VERSION ""

NS_ :

BS_:

BU_: FUSION ZONE_FR ZONE_DR D21_DKC ZONE_FR_24

BO_ 278 FD4_CE100_0: 32 FUSION
 SG_ CS_VCU1_CAN4 : 7|8@0+ (1,0) [0|255] ""  ZONE_FR,ZONE_DR
 SG_ RC_VCU1_CAN4 : 11|4@0+ (1,0) [0|14] ""  ZONE_FR,ZONE_DR
 SG_ Dr_SeatSta : 23|2@0+ (1,0) [0|2] ""  ZONE_FR,ZONE_DR,D21_DKC
 SG_ MSA_Crl_Sta : 21|3@0+ (1,0) [0|7] ""  ZONE_FR,ZONE_DR
 SG_ CC_Crl_Sta : 18|3@0+ (1,0) [0|7] ""  ZONE_FR,ZONE_DR
 SG_ ShiftGearPosn : 31|3@0+ (1,0) [0|7] ""  ZONE_FR,ZONE_DR,D21_DKC,ZONE_FR_24
 SG_ PwrSta : 28|3@0+ (1,0) [0|7] ""  ZONE_FR,ZONE_DR,D21_DKC,ZONE_FR_24
 SG_ ReBrakeLPReq : 25|1@0+ (1,0) [0|1] ""  ZONE_FR,ZONE_DR
 SG_ DKCTimeSN : 39|32@0+ (1,0) [0|4294967295] ""  ZONE_FR,ZONE_DR,D21_DKC
 SG_ TimeSNDKCFbk : 71|32@0+ (1,0) [0|4294967295] ""  ZONE_FR,ZONE_DR,D21_DKC
 SG_ EquivAccPedalSWSta : 103|1@0+ (1,0) [0|1] ""  ZONE_FR,ZONE_DR
 SG_ HornCtrl : 102|1@0+ (1,0) [0|1] ""  ZONE_FR,ZONE_DR
 SG_ BCM_DoorLock_Sta : 101|1@0+ (1,0) [0|1] ""  ZONE_FR,ZONE_DR,D21_DKC
 SG_ DimmerEN : 100|1@0+ (1,0) [0|1] ""  ZONE_FR,ZONE_DR
 SG_ RoomLampH : 99|1@0+ (1,0) [0|1] ""  ZONE_FR,ZONE_DR
 SG_ RoomLampL : 98|1@0+ (1,0) [0|1] ""  ZONE_FR,ZONE_DR
 SG_ TailgateRemote : 97|2@0+ (1,0) [0|3] ""  ZONE_FR,ZONE_DR
 SG_ Dimmer : 110|7@0+ (1,0) [0|100] "%"  ZONE_FR,ZONE_DR
 SG_ LockSetting : 118|1@0+ (1,0) [0|1] ""  ZONE_FR,ZONE_DR
 SG_ L_APM_WdwEnable : 117|1@0+ (1,0) [0|1] ""  ZONE_FR,ZONE_DR
 SG_ CrashDetd : 116|1@0+ (1,0) [0|1] ""  ZONE_FR,ZONE_DR
 SG_ AntiTheftSeatFold : 115|1@0+ (1,0) [0|1] ""  ZONE_FR,ZONE_DR
 SG_ AntitheftSta : 114|2@0+ (1,0) [0|3] ""  ZONE_FR,ZONE_DR,D21_DKC
 SG_ RTurnLP : 112|1@0+ (1,0) [0|1] ""  ZONE_FR,ZONE_DR,ZONE_FR_24
 SG_ LTurnLP : 127|1@0+ (1,0) [0|1] ""  ZONE_FR,ZONE_DR,ZONE_FR_24
 SG_ HazardSW : 126|1@0+ (1,0) [0|1] ""  ZONE_FR,ZONE_DR,ZONE_FR_24
 SG_ Rr_FogLamp : 125|1@0+ (1,0) [0|1] ""  ZONE_FR,ZONE_DR,ZONE_FR_24
 SG_ Fr_FogLamp : 124|1@0+ (1,0) [0|1] ""  ZONE_FR,ZONE_DR,ZONE_FR_24
 SG_ RBSD : 123|1@0+ (1,0) [0|1] ""  ZONE_FR,ZONE_DR,ZONE_FR_24
 SG_ LBSD : 122|1@0+ (1,0) [0|1] ""  ZONE_FR,ZONE_DR,ZONE_FR_24
 SG_ BrakeLamp : 121|1@0+ (1,0) [0|1] ""  ZONE_FR,ZONE_DR,ZONE_FR_24
 SG_ ReverseLamp : 120|1@0+ (1,0) [0|1] ""  ZONE_FR,ZONE_DR,ZONE_FR_24
 SG_ RDRL : 135|1@0+ (1,0) [0|1] ""  ZONE_FR,ZONE_DR,ZONE_FR_24
 SG_ LDRL : 134|1@0+ (1,0) [0|1] ""  ZONE_FR,ZONE_DR,ZONE_FR_24
 SG_ PosLamp : 133|1@0+ (1,0) [0|1] ""  ZONE_FR,ZONE_DR,ZONE_FR_24
 SG_ H_Beam : 132|1@0+ (1,0) [0|1] ""  ZONE_FR,ZONE_DR,ZONE_FR_24
 SG_ L_Beam : 131|1@0+ (1,0) [0|1] ""  ZONE_FR,ZONE_DR,ZONE_FR_24
 SG_ WasherCtrl : 130|2@0+ (1,0) [0|3] ""  ZONE_FR,ZONE_DR,ZONE_FR_24
 SG_ WiperFixMode : 128|1@0+ (1,0) [0|1] ""  ZONE_FR,ZONE_DR,ZONE_FR_24
 SG_ Rr_Wiper : 143|1@0+ (1,0) [0|1] ""  ZONE_FR,ZONE_DR
 SG_ Fr_Wiper_L : 142|1@0+ (1,0) [0|1] ""  ZONE_FR,ZONE_DR,ZONE_FR_24
 SG_ Fr_Wiper_H : 141|1@0+ (1,0) [0|1] ""  ZONE_FR,ZONE_DR,ZONE_FR_24
 SG_ MirrorCtrl : 140|2@0+ (1,0) [0|3] ""  ZONE_FR,ZONE_DR
 SG_ TailgateHDSW : 138|1@0+ (1,0) [0|1] ""  ZONE_FR,ZONE_DR,D21_DKC
 SG_ TrunkRel : 137|1@0+ (1,0) [0|1] ""  ZONE_FR,ZONE_DR
 SG_ Rr_Defog : 136|1@0+ (1,0) [0|1] ""  ZONE_FR,ZONE_DR
 SG_ Fr_ChargingDoorCtrl : 159|2@0+ (1,0) [0|3] ""  ZONE_FR,ZONE_DR
 SG_ HoodSW : 157|1@0+ (1,0) [0|1] ""  ZONE_FR,ZONE_DR,D21_DKC
 SG_ DoorLockIND : 156|1@0+ (1,0) [0|1] ""  ZONE_FR,ZONE_DR
 SG_ AllDoorSW : 155|1@0+ (1,0) [0|1] ""  ZONE_FR,ZONE_DR,D21_DKC
 SG_ RRDoorSW : 154|1@0+ (1,0) [0|1] ""  ZONE_FR,ZONE_DR,D21_DKC
 SG_ RLDoorSW : 153|1@0+ (1,0) [0|1] ""  ZONE_FR,ZONE_DR,D21_DKC
 SG_ PsDoorSW : 152|1@0+ (1,0) [0|1] ""  ZONE_FR,ZONE_DR,D21_DKC
 SG_ Rr_ChargingDoorCtrl : 167|2@0+ (1,0) [0|3] ""  ZONE_FR,ZONE_DR
 SG_ CTDCtrl : 165|2@0+ (1,0) [0|3] ""  ZONE_FR,ZONE_DR
 SG_ FD_TBOX_VehData_Sta : 163|4@0+ (1,0) [0|7] ""  ZONE_FR,ZONE_DR
 SG_ FD_TBOX_VehData_Err : 175|4@0+ (1,0) [0|7] ""  ZONE_FR,ZONE_DR
 SG_ FD_DKC_VehData_Sta : 171|4@0+ (1,0) [0|7] ""  ZONE_FR,ZONE_DR,D21_DKC
 SG_ FD_DKC_VehData_Err : 183|4@0+ (1,0) [0|7] ""  ZONE_FR,ZONE_DR,D21_DKC
 SG_ FD_TBOX_DTCData_Sta : 179|4@0+ (1,0) [0|7] ""  ZONE_FR,ZONE_DR
 SG_ FD_TBOX_DTCData_Err : 191|4@0+ (1,0) [0|7] ""  ZONE_FR,ZONE_DR
 SG_ LampPwr : 187|1@0+ (1,0) [0|1] ""  ZONE_FR,ZONE_DR
 SG_ DKCAuthSta : 185|2@0+ (1,0) [0|3] ""  ZONE_FR,ZONE_DR,D21_DKC
 SG_ MirrorDefog : 207|1@0+ (1,0) [0|1] ""  ZONE_FR,ZONE_DR
 SG_ DrDoorSW : 206|1@0+ (1,0) [0|1] ""  ZONE_FR,ZONE_DR,D21_DKC
 SG_ CTDLockSW : 215|1@0+ (1,0) [0|1] ""  ZONE_FR,ZONE_DR
 SG_ CTDUnlockSW : 214|1@0+ (1,0) [0|1] ""  ZONE_FR,ZONE_DR
 SG_ Tailgate_SW : 223|1@0+ (1,0) [0|1] ""  ZONE_FR,ZONE_DR,D21_DKC
 SG_ HWResetSta : 205|2@0+ (1,0) [0|3] ""  ZONE_FR,ZONE_DR
 SG_ CtrlFrBMSCCUCIR : 200|1@0+ (1,0) [0|1] ""  ZONE_FR
 SG_ CtrlFrEDUINVERTER : 201|1@0+ (1,0) [0|1] ""  ZONE_FR
 SG_ CtrlFrIRC1 : 202|1@0+ (1,0) [0|1] ""  ZONE_FR
 SG_ CtrlFrPwrStbA1P : 203|1@0+ (1,0) [0|1] ""  ZONE_FR
 SG_ CtrlDrPwrStbA2 : 222|1@0+ (1,0) [0|1] ""  ZONE_DR
 SG_ H_Beam_ADB : 24|1@0+ (1,0) [0|1] ""  ZONE_FR
 SG_ APS_Sta_System : 213|3@0+ (1,0) [0|7] ""  D21_DKC

BO_ 386 FD4_CE100_1: 64 FUSION
 SG_ CCU_HEATMaxLampSts : 23|1@0+ (1,0) [0|1] "" Vector__XXX
 SG_ CCU_ACLampSts : 22|1@0+ (1,0) [0|1] "" Vector__XXX
 SG_ CCU_Dispaly_Request : 21|1@0+ (1,0) [0|1] "" Vector__XXX
 SG_ CCU_EcoSts : 20|1@0+ (1,0) [0|1] "" Vector__XXX
 SG_ CCU_AutoMidLampSts : 19|1@0+ (1,0) [0|1] "" Vector__XXX
 SG_ CCU_AutoLampSts : 18|1@0+ (1,0) [0|1] "" Vector__XXX
 SG_ CCU_ACMaxLampSts : 17|1@0+ (1,0) [0|1] "" Vector__XXX
 SG_ Fr_Coolanttemp : 16|9@0+ (1,-40) [-40|214] "Deg^C" Vector__XXX
 SG_ CCU_RrOnOffLampSts : 39|1@0+ (1,0) [0|1] "" Vector__XXX
 SG_ CCU_FrtOnOffLampSts : 35|1@0+ (1,0) [0|1] "" Vector__XXX
 SG_ CCU_SyncLampSts : 55|1@0+ (1,0) [0|1] "" Vector__XXX
 SG_ HPThermalRecoveryReq : 71|2@0+ (1,0) [0|1] "" Vector__XXX
 SG_ EDriveMode : 79|2@0+ (1,0) [0|2] "" Vector__XXX
 SG_ Fr_Coolantflow : 77|6@0+ (0.25,0) [0|15.75] "L/min" Vector__XXX
 SG_ FD_RecyAuto_Cmd : 127|3@0+ (1,0) [0|7] ""  ZONE_DR
 SG_ BatteryMode : 134|3@0+ (1,0) [0|5] "" Vector__XXX
 SG_ CabinMode : 131|4@0+ (1,0) [0|15] ""  ZONE_DR
 SG_ Rr_Coolanttemp : 160|9@0+ (1,-40) [-40|214] "Deg^C" Vector__XXX
 SG_ FD_Blower_Cmd : 183|8@0+ (0.8,0) [0|200] "%"  ZONE_DR
 SG_ FD_SOV3_Cmd : 191|1@0+ (1,0) [0|1] ""  ZONE_FR
 SG_ FD_SOV2_Cmd : 190|1@0+ (1,0) [0|1] ""  ZONE_FR
 SG_ FD_SOV1_Cmd : 189|1@0+ (1,0) [0|1] ""  ZONE_FR
 SG_ FD_SOTXV_Cmd : 188|1@0+ (1,0) [0|1] ""  ZONE_FR
 SG_ FD_FWV_Cmd : 184|1@0+ (1,0) [0|1] ""  ZONE_FR
 SG_ CCU_HiVoltageReq : 199|1@0+ (1,0) [0|1] "" Vector__XXX
 SG_ FD_Comp_Cmd : 198|15@0+ (0.5,0) [0|8300] "RPM"  ZONE_FR
 SG_ CCU_CbnPreSts : 215|2@0+ (1,0) [0|3] "" Vector__XXX
 SG_ DeiceModReq : 213|2@0+ (1,0) [0|3] "" Vector__XXX
 SG_ CCU_CbnPreACWkSts : 211|2@0+ (1,0) [0|3] "" Vector__XXX
 SG_ FD_EXV1_Cmd : 209|10@0+ (1,0) [0|576] "step"  ZONE_FR
 SG_ CCU_CbnPreEstimdTi : 231|6@0+ (1,0) [0|63] "" Vector__XXX
 SG_ FD_EXV2_Cmd : 225|10@0+ (1,0) [0|576] "step"  ZONE_FR
 SG_ FD_TWV_Cmd : 247|8@0+ (0.392,0) [0|99.96] "%"  ZONE_FR
 SG_ FD_FrRiAPTCHeatPwr_Cmd : 255|8@0+ (25,0) [0|6375] "W"  ZONE_DR
 SG_ FD_FrLeAPTCHeatPwr_Cmd : 263|8@0+ (25,0) [0|6375] "W"  ZONE_DR
 SG_ FD_RrAPTCHeatPwr_Cmd : 271|8@0+ (25,0) [0|6375] "W"  ZONE_DR
 SG_ FD_FrWPTCHeatPwr_Cmd : 279|16@0+ (1,0) [0|65535] "W"  ZONE_FR
 SG_ FD_EWP3_Cmd : 295|8@0+ (1,0) [0|255] ""  ZONE_FR
 SG_ FD_EWP2_Cmd : 303|8@0+ (1,0) [0|255] ""  ZONE_FR
 SG_ FD_EWP1_Cmd : 311|8@0+ (1,0) [0|255] ""  ZONE_FR
 SG_ APTC_ActFrRiPwr : 319|8@0+ (25,0) [0|6375] "W" Vector__XXX
 SG_ BatLoopActWtFlw : 327|8@0+ (0.1,-5) [-5|20] "L/min" Vector__XXX
 SG_ CoolgFanActDuty : 335|8@0+ (0.5,0) [0|100] "%"  ZONE_FR
 SG_ sigRecircSt : 63|1@0+ (1,0) [0|1] ""  ZONE_DR
 SG_ sigWindDirZon1St : 38|3@0+ (1,0) [0|7] ""  ZONE_DR
 SG_ Rr_Coolantflow : 166|6@0+ (0.25,0) [0|15.75] "L/min" Vector__XXX
 SG_ sigHvacSt : 62|1@0+ (1,0) [0|1] "" Vector__XXX
 SG_ sigSetTempZon1St : 69|6@0+ (0.5,17) [17|32] "Deg^C" Vector__XXX
 SG_ sigSetTempZon2St : 61|6@0+ (0.5,17) [17|32] "Deg^C" Vector__XXX
 SG_ sigSetTempZon3St : 53|6@0+ (0.5,17) [17|32] "Deg^C" Vector__XXX
 SG_ sigWindDirZon3St : 34|3@0+ (1,0) [0|7] "" Vector__XXX
 SG_ ACSubMode : 187|3@0+ (1,0) [0|7] ""  ZONE_FR,ZONE_DR
 SG_ FDC_THCM_CLEVentY_Sta : 374|7@0+ (1,0) [0|127] "%"  ZONE_FR
 SG_ sigAirIntenZon1St : 47|4@0+ (1,0) [0|15] "" Vector__XXX
 SG_ sigAirIntenZon3St : 43|4@0+ (1,0) [0|15] "" Vector__XXX
 SG_ sigAmbAirT : 111|8@0+ (0.5,-40) [-40|85] "Deg^C"  ZONE_FR,ZONE_DR
 SG_ sigCbnAirT : 103|8@0+ (0.5,-40) [-40|85] "Deg^C" Vector__XXX
 SG_ sigCbnPTCPwrAct : 95|8@0+ (50,0) [0|12650] "W" Vector__XXX
 SG_ sigCbnSolarLeft : 143|8@0+ (5,0) [0|1265] "W" Vector__XXX
 SG_ sigCbnSolarRight : 119|8@0+ (5,0) [0|1265] "W" Vector__XXX
 SG_ sigClmtCmprPwrAct : 87|8@0+ (50,0) [0|12650] "W" Vector__XXX
 SG_ sigClntTHvBattOut : 151|8@0+ (0.5,-40) [-40|85] "Deg^C" Vector__XXX
 SG_ sigDfrstSt : 54|1@0+ (1,0) [0|1] "" Vector__XXX
 SG_ FDC_THCM_CLEVentZ_Sta : 382|7@0+ (1,0) [0|127] "%"  ZONE_FR
 SG_ FDC_THCM_CLVent_Sta : 359|1@0+ (1,0) [0|1] ""  ZONE_FR
 SG_ FDC_THCM_CREVentY_Sta : 390|7@0+ (1,0) [0|127] "%"  ZONE_FR
 SG_ FDC_THCM_CREVentZ_Sta : 398|7@0+ (1,0) [0|127] "%"  ZONE_FR
 SG_ FDC_THCM_CRVent_Sta : 367|1@0+ (1,0) [0|1] ""  ZONE_FR
 SG_ FDC_THCM_DrEVentMode_Sta : 405|3@0+ (1,0) [0|7] ""  ZONE_FR
 SG_ FDC_THCM_DrEVentY_Sta : 342|7@0+ (1,0) [0|127] "%"  ZONE_FR
 SG_ FDC_THCM_DrEVentZ_Sta : 350|7@0+ (1,0) [0|127] "%"  ZONE_FR
 SG_ FDC_THCM_DrVent_Sta : 343|1@0+ (1,0) [0|1] ""  ZONE_FR
 SG_ FDC_THCM_PsEVentMode_Sta : 402|3@0+ (1,0) [0|7] ""  ZONE_FR
 SG_ FDC_THCM_PsEVentY_Sta : 358|7@0+ (1,0) [0|127] "%"  ZONE_FR
 SG_ FDC_THCM_PsEVentZ_Sta : 366|7@0+ (1,0) [0|127] "%"  ZONE_FR
 SG_ FDC_THCM_PsVent_Sta : 351|1@0+ (1,0) [0|1] ""  ZONE_FR

BO_ 535 FD4_CE200_0: 32 FUSION
 SG_ FDLHandleLampCmd : 87|1@0+ (1,0) [0|1] "" Vector__XXX
 SG_ FDRHandleLampCmd : 79|1@0+ (1,0) [0|1] "" Vector__XXX
 SG_ AmbLightColor1 : 5|6@0+ (1,0) [0|63] ""  ZONE_DR
 SG_ BCM_Buzzer_Req : 63|1@0+ (1,0) [0|1] ""  ZONE_FR,ZONE_DR
 SG_ AmbLightColor2 : 13|6@0+ (1,0) [0|63] ""  ZONE_DR
 SG_ AmbLightColor3 : 21|6@0+ (1,0) [0|63] ""  ZONE_DR
 SG_ FDHandleCmd : 31|2@0+ (1,0) [0|3] "" Vector__XXX
 SG_ AmbLightColor4 : 29|6@0+ (1,0) [0|63] ""  ZONE_DR
 SG_ AmbLightColor5 : 37|6@0+ (1,0) [0|63] ""  ZONE_DR
 SG_ AmbLightColor6 : 45|6@0+ (1,0) [0|63] ""  ZONE_DR
 SG_ AmbLightBrightness1 : 54|7@0+ (1,0) [0|127] "%"  ZONE_DR
 SG_ AmbLightBrightness2 : 62|7@0+ (1,0) [0|127] "%"  ZONE_DR
 SG_ AmbLightBrightness3 : 70|7@0+ (1,0) [0|127] "%"  ZONE_DR
 SG_ AmbLightBrightness4 : 78|7@0+ (1,0) [0|127] "%"  ZONE_DR
 SG_ AmbLightBrightness5 : 86|7@0+ (1,0) [0|127] "%"  ZONE_DR
 SG_ AmbLightBrightness6 : 94|7@0+ (1,0) [0|127] "%"  ZONE_DR
 SG_ AmbLightBreath1 : 98|3@0+ (1,0) [0|7] ""  ZONE_DR
 SG_ AmbLightBreath2 : 101|3@0+ (1,0) [0|7] ""  ZONE_DR
 SG_ AmbLightBreath3 : 106|3@0+ (1,0) [0|7] ""  ZONE_DR
 SG_ AmbLightBreath4 : 109|3@0+ (1,0) [0|7] ""  ZONE_DR
 SG_ AmbLightBreath5 : 114|3@0+ (1,0) [0|7] ""  ZONE_DR
 SG_ AmbLightBreath6 : 117|3@0+ (1,0) [0|7] ""  ZONE_DR
 SG_ WelcomeLight : 23|2@0+ (1,0) [0|2] ""  ZONE_FR,ZONE_DR
 SG_ FDC_BCM_TurnSwTSetSta_Sta : 39|2@0+ (1,0) [0|3] ""  ZONE_DR
 SG_ FDC_BCM_UserHeightSet_Sta : 129|10@0+ (1,0) [0|1023] "" Vector__XXX
 SG_ FDC_BCM_UserNow_Sta : 122|3@0+ (1,0) [0|7] "" Vector__XXX
 SG_ FDC_DKC_CommandToBCM_Cmd : 159|4@0+ (1,0) [0|15] ""  ZONE_FR
 SG_ FDC_DKC_DKeyAreaPE_Sta : 47|2@0+ (1,0) [0|3] ""  ZONE_FR
 SG_ FDC_BCM_PTGOpenHeight_Sta : 125|3@0+ (1,0) [0|7] "" Vector__XXX
 SG_ FDC_BCM_ATCtrl_Cmd : 103|2@0+ (1,0) [0|2] ""  ZONE_DR
 SG_ FDC_BCM_LockAlarm_Cmd : 111|2@0+ (1,0) [0|2] ""  ZONE_DR
 SG_ FDC_BCM_FWipSw_Sta : 135|3@0+ (1,0) [0|7] ""  ZONE_DR
 SG_ FDC_BCM_TurnSw_Sta : 119|2@0+ (1,0) [0|3] ""  ZONE_DR
 SG_ FDC_BCM_FWasSw_Sta : 127|2@0+ (1,0) [0|3] ""  ZONE_DR
 SG_ FDC_BCM_PassSW_Sta : 55|1@0+ (1,0) [0|1] ""  ZONE_FR
 SG_ FDC_BCM_DimSw : 95|1@0+ (1,0) [0|1] ""  ZONE_FR
 SG_ FDC_THCM_ACTInitial_Cmd : 132|1@0+ (1,0) [0|1] ""  ZONE_DR
 SG_ FDC_DKC_SPTGDet_Cmd : 131|1@0+ (1,0) [0|1] "" Vector__XXX
 SG_ FDC_DKC_SPTGOpen_Cmd : 130|1@0+ (1,0) [0|1] "" Vector__XXX
 SG_ FDC_BCM_HazardIND_Cmd : 167|1@0+ (1,0) [0|1] ""  ZONE_DR
 SG_ FDC_THCM_AirIntZ3_Sta : 166|3@0+ (1,0) [0|7] ""  ZONE_DR
 SG_ FDC_BCM_OutMode_Cmd : 163|4@0+ (1,0) [0|15] "" Vector__XXX
 SG_ FDC_EChrg_SW_Sta : 175|2@0+ (1,0) [0|3] ""  ZONE_FR

BO_ 595 GW4_CE100_0: 32 FUSION
 SG_ IVI_Located_STA : 7|2@0+ (1,0) [0|3] ""  ZONE_FR,ZONE_DR
 SG_ Approach_Unlock_SW : 15|1@0+ (1,0) [0|1] ""  D21_DKC
 SG_ Walkaway_Lock_SW : 23|1@0+ (1,0) [0|1] ""  D21_DKC
 SG_ BrkSw_Sta : 31|1@0+ (1,0) [0|1] ""  ZONE_FR,ZONE_DR,D21_DKC
 SG_ DSEAT_anti_set : 39|1@0+ (1,0) [0|1] ""  ZONE_DR
 SG_ DSEAT_entryfun_set : 47|1@0+ (1,0) [0|1] ""  ZONE_DR
 SG_ IVI_PTG_Mode_SW : 46|2@0+ (1,0) [0|3] ""  ZONE_DR
 SG_ PSEAT_vent_req : 44|3@0+ (1,0) [0|7] ""  ZONE_DR
 SG_ IVI_PTG_Sta_SW : 41|2@0+ (1,0) [0|3] ""  ZONE_DR
 SG_ IVI_ISA_OffsetSpd : 55|4@0+ (1,0) [0|14] ""  ZONE_DR
 SG_ SenstivityPosition : 51|4@0+ (1,0) [0|15] ""  ZONE_DR
 SG_ IVI_Time_Check : 63|8@0+ (1,0) [0|255] ""  ZONE_FR,ZONE_DR,D21_DKC
 SG_ Distance_unit : 71|1@0+ (1,0) [0|1] ""  ZONE_DR
 SG_ IVI_Time_Year : 70|7@0+ (1,2000) [2000|2127] "YEAR"  ZONE_FR,ZONE_DR
 SG_ Hood_Latch_SW : 79|2@0+ (1,0) [0|3] ""  ZONE_DR
 SG_ IVI_Time_Minute : 77|6@0+ (1,0) [0|63] "MINUTE"  ZONE_FR,ZONE_DR,D21_DKC
 SG_ IVI_Time_Second : 85|6@0+ (1,0) [0|63] "SECOND"  ZONE_FR,ZONE_DR,D21_DKC
 SG_ DSEAT_vent_req : 95|3@0+ (1,0) [0|7] ""  ZONE_DR
 SG_ IVI_Time_Day : 92|5@0+ (1,0) [0|31] "DAY"  ZONE_FR,ZONE_DR,D21_DKC
 SG_ HeadLampSW : 102|2@0+ (1,0) [0|3] ""  ZONE_FR,ZONE_DR
 SG_ IVI_Time_Hour : 100|5@0+ (1,0) [0|31] "HOUR"  ZONE_FR,ZONE_DR,D21_DKC
 SG_ IVI_Time_Month : 107|4@0+ (1,0) [0|12] "MONTH"  ZONE_FR,ZONE_DR,D21_DKC
 SG_ IVI_DSEATHeater_Cmd : 110|3@0+ (1,0) [0|7] ""  ZONE_DR
 SG_ IVI_PSEATHeater_Cmd : 118|3@0+ (1,0) [0|7] ""  ZONE_DR
 SG_ FDC_PTG_inner_SW_2 : 5|2@0+ (1,0) [0|3] ""  D21_DKC
 SG_ BrkSw_V : 111|1@0+ (1,0) [0|1] ""  ZONE_DR
 SG_ MCPressure : 115|12@0+ (0.1,-9.7) [-9.7|195] "bar"  ZONE_DR
 SG_ MCPressure_V : 119|1@0+ (1,0) [0|1] ""  ZONE_DR
 SG_ BrkPedalPos : 135|8@0+ (0.4,0) [0|100] "%"  ZONE_DR
 SG_ BrkPedalPos_Sta : 103|1@0+ (1,0) [0|1] ""  ZONE_DR
 SG_ VehSpeed : 243|12@0+ (0.125,0) [0|255.875] "km/h"  ZONE_FR,ZONE_DR,D21_DKC
 SG_ L_Drv_CtrlCmd : 38|7@0+ (1,0) [0|127] "%"  ZONE_FR,ZONE_DR
 SG_ L_Pas_CtrlCmd : 30|7@0+ (1,0) [0|127] "%"  ZONE_FR,ZONE_DR
 SG_ L_RLD_CtrlCmd : 22|7@0+ (1,0) [0|127] "%"  ZONE_FR,ZONE_DR
 SG_ L_RRD_CtrlCmd : 14|7@0+ (1,0) [0|127] "%"  ZONE_FR,ZONE_DR
 SG_ OFF_AC_MODE : 143|3@0+ (1,0) [0|7] ""  ZONE_FR
 SG_ WlcmLight_Mode : 145|2@0+ (1,0) [0|3] ""  ZONE_FR,ZONE_DR
 SG_ Light_ShowStart_Req : 147|1@0+ (1,0) [0|1] ""  ZONE_FR,ZONE_DR
 SG_ Light_ShowStop_Req : 146|1@0+ (1,0) [0|1] ""  ZONE_FR,ZONE_DR
 SG_ AVM_parking_excute : 151|2@0+ (1,0) [0|3] ""  D21_DKC
 SG_ IVI_PTG_Open_Height : 2|3@0+ (1,0) [0|7] ""  ZONE_DR
 SG_ TBOX_Remote_PW : 140|5@0+ (1,0) [0|16] ""  ZONE_FR,ZONE_DR
 SG_ METER_KPH_Calcu : 159|8@0+ (1,0) [0|254] "km/h"  ZONE_DR
 SG_ ChrgInLockReq : 87|2@0+ (1,0) [0|2] ""  ZONE_FR
 SG_ IVI_TrailerCheckReq_Sta : 148|1@0+ (1,0) [0|1] ""  ZONE_FR
 SG_ IVI_TrailerModeSW_Sta : 149|1@0+ (1,0) [0|1] ""  ZONE_FR
 SG_ IVI_ChargePortSW_Sta : 3|1@0+ (1,0) [0|1] ""  ZONE_FR,ZONE_DR
 SG_ ChrgPlugSta : 183|2@0+ (1,0) [0|3] ""  ZONE_FR
 SG_ ExtChrgSta : 181|2@0+ (1,0) [0|3] ""  ZONE_FR
 SG_ OBCV2LSta : 179|2@0+ (1,0) [0|2] ""  ZONE_FR
 SG_ V2LSta : 177|2@0+ (1,0) [0|3] ""  ZONE_FR

BO_ 1080 FD4_OTA1: 12 FUSION
 SG_ OTA_Progress_Rate : 7|8@0+ (1,0) [0|102] "%" Vector__XXX
 SG_ OTA_MDA_Status : 52|5@0+ (1,0) [0|14] "" Vector__XXX
 SG_ OTA_Network_Type : 11|2@0+ (1,0) [0|3] "" Vector__XXX
 SG_ OTA_Mode : 9|1@0+ (1,0) [0|1] ""  ZONE_FR,ZONE_DR,D21_DKC
 SG_ OTA_DL_Available : 8|1@0+ (1,0) [0|1] "" Vector__XXX
 SG_ OTA_InVehicle_FW : 29|2@0+ (1,0) [0|2] "" Vector__XXX
 SG_ OTA_Update_Available : 62|1@0+ (1,0) [0|1] "" Vector__XXX
 SG_ OTA_Updating_ECU_8bit : 23|8@0+ (1,0) [0|255] "" Vector__XXX
 SG_ OTA_Lock_Req : 31|1@0+ (1,0) [0|1] ""  D21_DKC
 SG_ OTA_TBOXResetReq : 30|1@0+ (1,0) [0|1] ""  ZONE_DR
 SG_ OTA_DL_Speed : 27|20@0+ (1,0) [0|1048575] "Kb/s" Vector__XXX
 SG_ OTA_Permit_Agreed : 63|1@0+ (1,0) [0|1] "" Vector__XXX
 SG_ OTA_Remained_Time : 58|11@0+ (10,0) [0|1081] "SECOND" Vector__XXX
 SG_ OTA_Debug_Code : 79|8@0+ (1,0) [0|65] "" Vector__XXX
 SG_ OTA_Emergency_Sta : 61|2@0+ (1,0) [0|3] "" Vector__XXX

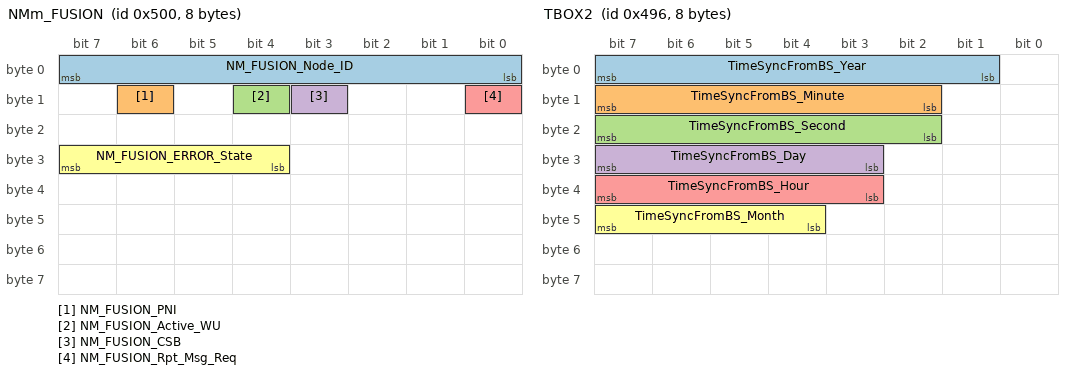
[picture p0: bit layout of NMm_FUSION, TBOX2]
BO_ 1280 NMm_FUSION: 8 FUSION
 SG_ NM_FUSION_Node_ID : 7|8@0+ (1,0) [0|127] ""  ZONE_FR,ZONE_DR,D21_DKC
 SG_ NM_FUSION_PNI : 14|1@0+ (1,0) [0|1] ""  ZONE_FR,ZONE_DR,D21_DKC
 SG_ NM_FUSION_Active_WU : 12|1@0+ (1,0) [0|1] ""  ZONE_FR,ZONE_DR,D21_DKC
 SG_ NM_FUSION_CSB : 11|1@0+ (1,0) [0|1] ""  ZONE_FR,ZONE_DR,D21_DKC
 SG_ NM_FUSION_Rpt_Msg_Req : 8|1@0+ (1,0) [0|1] ""  ZONE_FR,ZONE_DR,D21_DKC
 SG_ NM_FUSION_ERROR_State : 31|4@0+ (1,0) [0|8] ""  ZONE_FR,ZONE_DR,D21_DKC

BO_ 1668 DiagPhysReqToZONE_FR: 64 FUSION
 SG_ DiagPhysReqToZONE_FR : 455|64@0+ (1,0) [0|0] ""  ZONE_FR

BO_ 1669 DiagPhysReqToDKC: 32 FUSION
 SG_ DiagPhysReqToDKC : 7|64@0+ (1,0) [0|0] ""  D21_DKC

BO_ 1701 DiagPhysReqToAirPTC: 8 FUSION
 SG_ DiagPhysReqToAirPTC : 7|64@0+ (1,0) [0|0] ""  ZONE_DR

BO_ 1717 DiagPhysReqToWPTC: 8 FUSION
 SG_ DiagPhysReqToWPTC : 7|64@0+ (1,0) [0|0] ""  ZONE_FR

BO_ 1728 DiagPhysReqToZONE_DR: 64 FUSION
 SG_ DiagPhysReqToZONE_DR : 455|64@0+ (1,0) [0|0] ""  ZONE_DR

BO_ 1733 DiagPhysReqToCompressor: 8 FUSION
 SG_ DiagPhysReqToCompressor : 7|64@0+ (1,0) [0|0] ""  ZONE_FR

BO_ 2000 DiagFuncReqFT: 8 FUSION
 SG_ DiagFuncReqFT : 7|64@0+ (1,0) [0|0] ""  ZONE_FR,ZONE_DR,D21_DKC,ZONE_FR_24

BO_ 1174 TBOX2: 8 FUSION
 SG_ TimeSyncFromBS_Year : 7|7@0+ (1,2000) [2000|2099] "YEAR"  ZONE_FR,ZONE_DR
 SG_ TimeSyncFromBS_Minute : 15|6@0+ (1,0) [0|59] "MINUTE"  ZONE_FR,ZONE_DR
 SG_ TimeSyncFromBS_Second : 23|6@0+ (1,0) [0|59] "SECOND"  ZONE_FR,ZONE_DR
 SG_ TimeSyncFromBS_Day : 31|5@0+ (1,0) [0|31] "DAY"  ZONE_FR,ZONE_DR
 SG_ TimeSyncFromBS_Hour : 39|5@0+ (1,0) [0|23] "HOUR"  ZONE_FR,ZONE_DR
 SG_ TimeSyncFromBS_Month : 47|4@0+ (1,0) [0|12] "MONTH"  ZONE_FR,ZONE_DR

BO_ 497 ZONE_DR_VCU: 48 ZONE_DR
 SG_ DrPMMSysErrLmp : 7|1@0+ (1,0) [0|1] ""  FUSION
 SG_ DrPMMLVOutPErrLmp : 6|1@0+ (1,0) [0|1] ""  FUSION
 SG_ DrPMMLimpHomeActReq : 5|1@0+ (1,0) [0|1] ""  FUSION
 SG_ DrAPWStaErr : 4|1@0+ (1,0) [0|1] ""  FUSION
 SG_ DrIVIFault : 3|2@0+ (1,0) [0|2] ""  FUSION
 SG_ DrEOBDFault : 1|2@0+ (1,0) [0|2] ""  FUSION
 SG_ DrInfoFault : 15|2@0+ (1,0) [0|2] ""  FUSION
 SG_ DrPwrWindowECUFault : 13|2@0+ (1,0) [0|2] ""  FUSION
 SG_ DrTHCMFault : 11|2@0+ (1,0) [0|2] ""  FUSION
 SG_ DrColumnSWFault : 9|2@0+ (1,0) [0|2] ""  FUSION
 SG_ DrADASCurr : 23|8@0+ (0.125,0) [0|31.875] "A"  FUSION
 SG_ DrAuBoxPwrN2Curr : 31|8@0+ (0.125,0) [0|31.875] "A"  FUSION
 SG_ DrAuBoxPwrN1Curr : 39|8@0+ (0.125,0) [0|31.875] "A"  FUSION
 SG_ DrPwrStdbyACurr : 47|8@0+ (0.125,0) [0|31.875] "A"  FUSION
 SG_ DrPwrONA2Curr : 55|8@0+ (0.125,0) [0|31.875] "A"  FUSION
 SG_ DrPwrONA1Curr : 63|8@0+ (0.125,0) [0|31.875] "A"  FUSION
 SG_ Blower_FB : 71|4@0+ (12.5,0) [0|187.5] "%"  FUSION
 SG_ DrCtrlBDVolt : 67|12@0+ (0.01,0) [0|36] "V"  FUSION
 SG_ DrCtrlTemp : 87|16@0+ (0.01,-40) [-40|125] "Deg^C"  FUSION
 SG_ DrPowerTemp1 : 103|16@0+ (0.01,-40) [-40|125] "Deg^C"  FUSION
 SG_ DrPowerTemp2 : 119|16@0+ (0.01,-40) [-40|125] "Deg^C"  FUSION
 SG_ T_Foot_R : 135|8@0+ (0.5,-40) [-40|85] "Deg^C"  FUSION
 SG_ T_Foot_Rr : 143|8@0+ (0.5,-40) [-40|85] "Deg^C"  FUSION
 SG_ T_Face_Rr : 151|8@0+ (0.5,-40) [-40|85] "Deg^C"  FUSION
 SG_ T_Foot_L : 159|8@0+ (0.5,-40) [-40|85] "Deg^C"  FUSION
 SG_ T_Face_R : 167|8@0+ (0.5,-40) [-40|85] "Deg^C"  FUSION
 SG_ T_Face_L : 175|8@0+ (0.5,-40) [-40|85] "Deg^C"  FUSION
 SG_ Tevap : 183|8@0+ (0.5,-40) [-40|85] "Deg^C"  FUSION
 SG_ Tincar : 191|8@0+ (0.5,-40) [-40|85] "Deg^C"  FUSION
 SG_ SolarR : 199|8@0+ (5,0) [0|1265] "W"  FUSION
 SG_ SolarL : 207|8@0+ (5,0) [0|1265] "W"  FUSION
 SG_ APTC_Err : 215|2@0+ (1,0) [0|3] ""  FUSION
 SG_ Blower_Err : 213|2@0+ (1,0) [0|3] ""  FUSION
 SG_ T_Foot_Rr_Err : 211|2@0+ (1,0) [0|3] ""  FUSION
 SG_ T_Face_Rr_Err : 209|2@0+ (1,0) [0|3] ""  FUSION
 SG_ T_Foot_R_Err : 223|2@0+ (1,0) [0|3] ""  FUSION
 SG_ T_Face_R_Err : 221|2@0+ (1,0) [0|3] ""  FUSION
 SG_ T_Foot_L_Err : 219|2@0+ (1,0) [0|3] ""  FUSION
 SG_ T_Face_L_Err : 217|2@0+ (1,0) [0|3] ""  FUSION
 SG_ Tincar_Err : 231|2@0+ (1,0) [0|3] ""  FUSION
 SG_ Tevap_Err : 229|2@0+ (1,0) [0|3] ""  FUSION
 SG_ SolarR_Err : 227|2@0+ (1,0) [0|3] ""  FUSION
 SG_ SolarL_Err : 225|2@0+ (1,0) [0|3] ""  FUSION
 SG_ DrSCPSysErrLmp : 260|1@0+ (1,0) [0|1] ""  FUSION
 SG_ ZoneDrMalfunLevel : 250|3@0+ (1,0) [0|5] ""  FUSION
 SG_ DrAPWLINErr : 254|1@0+ (1,0) [0|1] ""  FUSION
 SG_ DrONA1ErrSta : 252|1@0+ (1,0) [0|1] ""  FUSION
 SG_ DrStdAErrSta : 251|1@0+ (1,0) [0|1] ""  FUSION
 SG_ DrPwrWinErrSta : 255|1@0+ (1,0) [0|1] ""  FUSION
 SG_ DrInfoErrSta : 253|1@0+ (1,0) [0|1] ""  FUSION
 SG_ RegenSW_Err : 262|1@0+ (1,0) [0|1] ""  FUSION
 SG_ DrPwrSta : 258|3@0+ (1,0) [0|7] ""  FUSION
 SG_ DrPwrInformationSta : 261|1@0+ (1,0) [0|1] ""  FUSION
 SG_ ZDR_SYS_APMRetryCnt_Sta : 247|8@0+ (1,0) [0|255] ""  FUSION
 SG_ ZDR_SYS_CSWRetryCnt_Sta : 239|8@0+ (1,0) [0|255] ""  FUSION
 SG_ ZDR_SYS_BSWSleepReq_Sta : 259|1@0+ (1,0) [0|1] ""  FUSION
 SG_ ZDR_VCU_HWReset_Sta : 268|5@0+ (1,0) [0|31] ""  FUSION
 SG_ ZDR_VCU_PwrSupply_Sta : 263|1@0+ (1,0) [0|1] ""  FUSION

BO_ 498 ZONE_FR_VCU: 48 ZONE_FR
 SG_ FrPwrStdbyA2PlusCurr : 7|8@0+ (0.125,0) [0|31.875] "A"  FUSION
 SG_ FrBMS_CCU_CIRCurr : 15|8@0+ (0.125,0) [0|31.875] "A"  FUSION
 SG_ FrEDU_INVERTERCurr : 23|8@0+ (0.125,0) [0|31.875] "A"  FUSION
 SG_ FrPwrStdbyA1PlusFault : 31|3@0+ (1,0) [0|7] ""  FUSION
 SG_ FrPwrStdbyA2PlusFault : 28|3@0+ (1,0) [0|7] ""  FUSION
 SG_ FrPwrONA1Fault : 25|2@0+ (1,0) [0|2] ""  FUSION
 SG_ FrBMS_CCU_CIRFault : 39|3@0+ (1,0) [0|7] ""  FUSION
 SG_ FrEDU_INVERTERFault : 36|3@0+ (1,0) [0|7] ""  FUSION
 SG_ FrPwrStdbyA1Fault : 33|2@0+ (1,0) [0|2] ""  FUSION
 SG_ FrPMMSysErrLmp : 47|1@0+ (1,0) [0|1] ""  FUSION
 SG_ FrPMMLVOutPErrLmp : 46|1@0+ (1,0) [0|1] ""  FUSION
 SG_ FrPMMLimpHomeActReq : 45|1@0+ (1,0) [0|1] ""  FUSION
 SG_ ZoneFrMalfunLevel : 44|3@0+ (1,0) [0|5] ""  FUSION
 SG_ FrIRC_1Curr : 41|10@0+ (1,0) [0|1023] "mA"  FUSION
 SG_ FrPwrStdbyA2Curr : 63|8@0+ (0.125,0) [0|31.875] "A"  FUSION
 SG_ FrPwrONA3Curr : 71|8@0+ (0.125,0) [0|31.875] "A"  FUSION
 SG_ FrPwrONA2Curr : 79|8@0+ (0.125,0) [0|31.875] "A"  FUSION
 SG_ FrStdA1PCErr : 87|1@0+ (1,0) [0|1] ""  FUSION
 SG_ FrStdA2PErr : 86|1@0+ (1,0) [0|1] ""  FUSION
 SG_ FrStdA2PCErr : 85|1@0+ (1,0) [0|1] ""  FUSION
 SG_ FrBMSCCUCErr : 84|1@0+ (1,0) [0|1] ""  FUSION
 SG_ FrEDUErr : 83|1@0+ (1,0) [0|1] ""  FUSION
 SG_ FrIRC_2Curr : 81|10@0+ (1,0) [0|1023] "mA"  FUSION
 SG_ FrPwrStdbyA1PlusCurr : 103|8@0+ (0.125,0) [0|31.875] "A"  FUSION
 SG_ FrPwrSta : 111|3@0+ (1,0) [0|7] ""  FUSION
 SG_ FrCtrlBDVolt : 107|12@0+ (0.01,0) [0|36] "V"  FUSION
 SG_ FrCtrlTemp : 127|16@0+ (0.01,-40) [-40|125] "Deg^C"  FUSION
 SG_ FrPowerTemp2 : 143|16@0+ (0.01,-40) [-40|125] "Deg^C"  FUSION
 SG_ FrPowerTemp1 : 159|16@0+ (0.01,-40) [-40|125] "Deg^C"  FUSION
 SG_ PT_High_Tact : 175|8@0+ (1,-40) [-40|140] "Deg^C"  FUSION
 SG_ EACProtectEnable : 183|2@0+ (1,0) [0|2] ""  FUSION
 SG_ PT_High_P : 179|12@0+ (1,0) [0|4000] "KPa"  FUSION
 SG_ PT_High_T : 199|8@0+ (0.5,-40) [-40|85] "Deg^C"  FUSION
 SG_ PT_Low_T2 : 207|8@0+ (0.5,-40) [-40|85] "Deg^C"  FUSION
 SG_ PT_Low_P2 : 215|12@0+ (1,0) [0|4000] "KPa"  FUSION
 SG_ PT_Low_P1 : 219|12@0+ (1,0) [0|4000] "KPa"  FUSION
 SG_ PT_Low_T1 : 239|8@0+ (0.5,-40) [-40|85] "Deg^C"  FUSION
 SG_ Tamb : 247|8@0+ (0.5,-40) [-40|85] "Deg^C"  FUSION
 SG_ Bat_Out_Temp : 255|8@0+ (0.5,-40) [-40|85] "Deg^C"  FUSION
 SG_ Bat_In_Temp : 263|8@0+ (0.5,-40) [-40|85] "Deg^C"  FUSION
 SG_ Motor_Out_Temp : 271|8@0+ (0.5,-40) [-40|85] "Deg^C"  FUSION
 SG_ Motor_In_Temp : 279|8@0+ (0.5,-40) [-40|85] "Deg^C"  FUSION
 SG_ TWV_Err : 287|2@0+ (1,0) [0|3] ""  FUSION
 SG_ EWP3_Err : 285|2@0+ (1,0) [0|3] ""  FUSION
 SG_ EWP2_Err : 283|2@0+ (1,0) [0|3] ""  FUSION
 SG_ FWV_Err : 281|2@0+ (1,0) [0|3] ""  FUSION
 SG_ EWP1_Err : 295|2@0+ (1,0) [0|3] ""  FUSION
 SG_ WPTC_Err : 293|2@0+ (1,0) [0|3] ""  FUSION
 SG_ Fan_Err : 289|2@0+ (1,0) [0|3] ""  FUSION
 SG_ EXV2_Err : 303|2@0+ (1,0) [0|3] ""  FUSION
 SG_ EXV1_Err : 301|2@0+ (1,0) [0|3] ""  FUSION
 SG_ SOTXV_Err : 299|2@0+ (1,0) [0|3] ""  FUSION
 SG_ COMP_Err : 297|2@0+ (1,0) [0|3] ""  FUSION
 SG_ SOV3_Err : 311|2@0+ (1,0) [0|3] ""  FUSION
 SG_ SOV2_Err : 309|2@0+ (1,0) [0|3] ""  FUSION
 SG_ SOV1_Err : 307|2@0+ (1,0) [0|3] ""  FUSION
 SG_ PT_High_Tact_Err : 305|2@0+ (1,0) [0|3] ""  FUSION
 SG_ PT_High_P_Err : 319|2@0+ (1,0) [0|3] ""  FUSION
 SG_ PT_Low_T2_Err : 317|2@0+ (1,0) [0|3] ""  FUSION
 SG_ PT_Low_P2_Err : 315|2@0+ (1,0) [0|3] ""  FUSION
 SG_ PT_Low_T1_Err : 313|2@0+ (1,0) [0|3] ""  FUSION
 SG_ PT_Low_P1_Err : 327|2@0+ (1,0) [0|3] ""  FUSION
 SG_ Motor_Out_Temp_Err : 325|2@0+ (1,0) [0|3] ""  FUSION
 SG_ Bat_Out_Temp_Err : 323|2@0+ (1,0) [0|3] ""  FUSION
 SG_ Motor_In_Temp_Err : 321|2@0+ (1,0) [0|3] ""  FUSION
 SG_ Bat_In_Temp_Err : 335|2@0+ (1,0) [0|3] ""  FUSION
 SG_ Tamb_Err : 333|2@0+ (1,0) [0|3] ""  FUSION
 SG_ ZFR_SYS_MCURetryCnt_Sta : 343|8@0+ (1,0) [0|255] ""  FUSION
 SG_ ZFR_SYS_BMSCCURetryCnt_Sta : 351|8@0+ (1,0) [0|255] ""  FUSION
 SG_ ZFR_SYS_BSWSleepReq_Sta : 82|1@0+ (1,0) [0|1] ""  FUSION
 SG_ ZFR_VCU_HWReset_Sta : 356|5@0+ (1,0) [0|31] ""  FUSION
 SG_ ZFR_VCU_PwrSupply_Sta : 108|1@0+ (1,0) [0|1] ""  FUSION

BO_ 547 zGW_APTC1: 24 ZONE_DR
 SG_ FrntPTCSts : 7|1@0+ (1,0) [0|1] ""  FUSION
 SG_ FrntPTCFltSt : 6|2@0+ (1,0) [0|3] ""  FUSION
 SG_ FrntPTCLVUnderUFlt : 4|1@0+ (1,0) [0|1] ""  FUSION
 SG_ FrntPTCLVOverUFlt : 3|1@0+ (1,0) [0|1] ""  FUSION
 SG_ FrntPTCHVUnderUFlt : 2|1@0+ (1,0) [0|1] ""  FUSION
 SG_ FrntPTCHVOverUFlt : 1|1@0+ (1,0) [0|1] ""  FUSION
 SG_ FrntPTCLeOverAFlt : 0|1@0+ (1,0) [0|1] ""  FUSION
 SG_ FrntPTCRiOverAFlt : 15|1@0+ (1,0) [0|1] ""  FUSION
 SG_ FrntPTCLeCoreTSnsrFlt : 14|1@0+ (1,0) [0|1] ""  FUSION
 SG_ FrntPTCRiCoreTSnsrFlt : 13|1@0+ (1,0) [0|1] ""  FUSION
 SG_ FrntPTCLeCoreOverTFlt : 12|1@0+ (1,0) [0|1] ""  FUSION
 SG_ FrntPTCRiCoreOverTFlt : 11|1@0+ (1,0) [0|1] ""  FUSION
 SG_ FrntPTCLeIGBTShoCircFlt : 10|1@0+ (1,0) [0|1] ""  FUSION
 SG_ FrntPTCRiIGBTShoCircFlt : 9|1@0+ (1,0) [0|1] ""  FUSION
 SG_ FrntPTCLeOpentCircFlt : 8|1@0+ (1,0) [0|1] ""  FUSION
 SG_ FrntPTCRiOpentCircFlt : 23|1@0+ (1,0) [0|1] ""  FUSION
 SG_ FrntPTCPCBTSnsrFlt : 22|1@0+ (1,0) [0|1] ""  FUSION
 SG_ FrntPTCPCBOverTFlt : 21|1@0+ (1,0) [0|1] ""  FUSION
 SG_ FrntPTCComFlt : 20|1@0+ (1,0) [0|1] ""  FUSION
 SG_ FrntPTCLeIGBTTSnsrFlt : 19|1@0+ (1,0) [0|1] ""  FUSION
 SG_ FrntPTCRiIGBTTSnsrFlt : 18|1@0+ (1,0) [0|1] ""  FUSION
 SG_ FrntPTCLeIGBTOverTFlt : 17|1@0+ (1,0) [0|1] ""  FUSION
 SG_ FrntPTCRiIGBTOverTFlt : 16|1@0+ (1,0) [0|1] ""  FUSION
 SG_ FrntPTCSWVers : 31|8@0+ (1,0) [0|255] ""  FUSION
 SG_ FrntPTCHWVers : 39|8@0+ (1,0) [0|255] ""  FUSION
 SG_ FrntPTCSupplierCod : 47|4@0+ (1,0) [0|15] ""  FUSION
 SG_ FrntPTCRearLeOverAFlt : 43|1@0+ (1,0) [0|1] ""  FUSION
 SG_ FrntPTCRearLeOpentCircFlt : 42|1@0+ (1,0) [0|1] ""  FUSION
 SG_ FrntPTCRearRiCoreOverTFlt : 41|1@0+ (1,0) [0|1] ""  FUSION
 SG_ FrntPTCRearLeCoreOverTFlt : 40|1@0+ (1,0) [0|1] ""  FUSION
 SG_ FrntPTCRearRiCoreTSnsrFlt : 55|1@0+ (1,0) [0|1] ""  FUSION
 SG_ FrntPTCRearLeCoreTSnsrFlt : 54|1@0+ (1,0) [0|1] ""  FUSION
 SG_ FrntPTCRearRiOverAFlt : 53|1@0+ (1,0) [0|1] ""  FUSION
 SG_ FrntPTCRearRiOpentCircFlt : 52|1@0+ (1,0) [0|1] ""  FUSION
 SG_ FrntPTCRearRiIGBTShoCFlt : 51|1@0+ (1,0) [0|1] ""  FUSION
 SG_ FrntPTCRearLeIGBTShoCFlt : 50|1@0+ (1,0) [0|1] ""  FUSION
 SG_ FrntPTCRearLeBusLineC : 63|8@0+ (0.1,0) [0|25.5] "A"  FUSION
 SG_ FrntPTCLeCoreT : 71|8@0+ (1,-40) [-40|215] "Deg^C"  FUSION
 SG_ FrntPTCRiCoreT : 79|8@0+ (1,-40) [-40|215] "Deg^C"  FUSION
 SG_ FrntPTCLeActHeatPwr : 87|8@0+ (25,0) [0|6375] "W"  FUSION
 SG_ FrntPTCRiActHeatPwr : 95|8@0+ (25,0) [0|6375] "W"  FUSION
 SG_ FrntPTCLeIGBTT : 103|8@0+ (1,-40) [-40|215] "Deg^C"  FUSION
 SG_ FrntPTCRiIGBTT : 111|8@0+ (1,-40) [-40|215] "Deg^C"  FUSION
 SG_ FrntPTCPCBT : 119|8@0+ (1,-40) [-40|215] "Deg^C"  FUSION
 SG_ FrntPTCRearRiBusLineC : 127|8@0+ (0.1,0) [0|25.5] "A"  FUSION
 SG_ FrntPTCRearLeActHeatPwr : 135|8@0+ (25,0) [0|6375] "W"  FUSION
 SG_ FrntPTCRearLeCoreT : 143|8@0+ (1,-40) [-40|215] "Deg^C"  FUSION
 SG_ FrntPTCRearRiActHeatPwr : 151|8@0+ (25,0) [0|6375] "W"  FUSION
 SG_ FrntPTCRearRiCoreT : 159|8@0+ (1,-40) [-40|215] "Deg^C"  FUSION
 SG_ FrntPTCLeBusLineC : 167|8@0+ (0.1,0) [0|25.5] "A"  FUSION
 SG_ FrntPTCRiBusLineC : 175|8@0+ (0.1,0) [0|25.5] "A"  FUSION
 SG_ FrntPTCBusLineHiV : 177|10@0+ (1,0) [0|1023] "V"  FUSION

BO_ 550 zGW_LINDr1: 32 ZONE_DR
 SG_ RLS_LIN_Resp_Err : 175|1@0+ (1,0) [0|1] ""  FUSION
 SG_ RLS_LightSnrErr : 255|1@0+ (1,0) [0|1] ""  FUSION
 SG_ RLS_RainSnrErr : 254|1@0+ (1,0) [0|1] ""  FUSION
 SG_ CSW_resp_error : 253|1@0+ (1,0) [0|1] ""  FUSION
 SG_ RLS_Lamp_Sta : 147|1@0+ (1,0) [0|1] ""  FUSION
 SG_ RLS_RainSnrWiperCmd : 146|3@0+ (1,0) [0|7] ""  FUSION
 SG_ CSW_FWipSw_Sta : 165|3@0+ (1,0) [0|7] ""  FUSION
 SG_ CSW_TurnSw_Sta : 63|2@0+ (1,0) [0|3] ""  FUSION
 SG_ CSW_RWasSW_Sta : 61|2@0+ (1,0) [0|3] ""  FUSION
 SG_ CSW_FWasSw_Sta : 59|2@0+ (1,0) [0|3] ""  FUSION
 SG_ CSW_PassSW_Sta : 252|1@0+ (1,0) [0|1] ""  FUSION
 SG_ CSW_DimSw : 251|1@0+ (1,0) [0|1] ""  FUSION
 SG_ CSW_RWipIntSw_Sta : 57|2@0+ (1,0) [0|3] ""  FUSION
 SG_ CSW_HW_version : 71|16@0+ (0.01,0) [0|99.99] ""  FUSION
 SG_ CSW_SW_version : 87|16@0+ (0.01,0) [0|99.99] ""  FUSION
 SG_ SWC_A_SW_version : 103|16@0+ (0.01,0) [0|99.99] ""  FUSION
 SG_ SWC_A_HW_version : 119|16@0+ (0.01,0) [0|99.99] ""  FUSION
 SG_ SWC_Drivemode_Sta : 135|2@0+ (1,0) [0|1] ""  FUSION
 SG_ SWC_CANCEL_Sta : 133|1@0+ (1,0) [0|1] ""  FUSION
 SG_ SWC_ACC_Sta : 132|1@0+ (1,0) [0|1] ""  FUSION
 SG_ SWC_A_Resp_Err : 131|1@0+ (1,0) [0|1] ""  FUSION
 SG_ SWC_Distance_Sta : 130|1@0+ (1,0) [0|1] ""  FUSION
 SG_ SWC_Down_Sta : 129|1@0+ (1,0) [0|1] ""  FUSION
 SG_ SWC_RegenUp : 128|1@0+ (1,0) [0|1] ""  FUSION
 SG_ SWC_Left_Sta : 143|1@0+ (1,0) [0|1] ""  FUSION
 SG_ SWC_mode_Sta : 142|1@0+ (1,0) [0|1] ""  FUSION
 SG_ SWC_resp_error : 141|1@0+ (1,0) [0|1] ""  FUSION
 SG_ SWC_Res_Up_Sta : 140|1@0+ (1,0) [0|1] ""  FUSION
 SG_ SWC_RegenDown : 139|1@0+ (1,0) [0|1] ""  FUSION
 SG_ SWC_Right_Sta : 138|1@0+ (1,0) [0|1] ""  FUSION
 SG_ SWC_Set_down_Sta : 137|1@0+ (1,0) [0|1] ""  FUSION
 SG_ SWC_Trip_Sta : 136|1@0+ (1,0) [0|1] ""  FUSION
 SG_ SWC_Up_Sta : 151|1@0+ (1,0) [0|1] ""  FUSION
 SG_ SWC_VR_Sta : 150|1@0+ (1,0) [0|1] ""  FUSION
 SG_ SWC_Undefined_Sta : 149|1@0+ (1,0) [0|1] ""  FUSION
 SG_ SWC_LKA_Sta : 148|1@0+ (1,0) [0|1] ""  FUSION
 SG_ L_Pas_Wdw_Obs_InhibitSts : 159|1@0+ (1,0) [0|1] ""  FUSION
 SG_ L_Drv_Wdw_RRD_Switch : 157|3@0+ (1,0) [0|7] ""  FUSION
 SG_ L_Drv_Wdw_RLD_Switch : 154|3@0+ (1,0) [0|7] ""  FUSION
 SG_ L_Pas_Wdw_OD_Sts : 167|1@0+ (1,0) [0|1] ""  FUSION
 SG_ L_Pas_Wdw_Init : 166|1@0+ (1,0) [0|1] ""  FUSION
 SG_ L_Pas_OverHeat_Protect : 158|1@0+ (1,0) [0|1] ""  FUSION
 SG_ L_Pas_Motor_Relay_Error : 54|1@0+ (1,0) [0|1] ""  FUSION
 SG_ L_Pas_Motor_Ripple_Error : 55|1@0+ (1,0) [0|1] ""  FUSION
 SG_ L_Drv_Wdw_Pas_Switch : 162|3@0+ (1,0) [0|7] ""  FUSION
 SG_ L_Pas_Val_Wdw_Opened : 174|7@0+ (1,0) [0|100] "%"  FUSION
 SG_ L_Pas_Wdw_PositionSts : 183|2@0+ (1,0) [0|3] ""  FUSION
 SG_ L_Pas_Wdw_LocalSwitch : 181|3@0+ (1,0) [0|7] ""  FUSION
 SG_ L_Pas_Wdw_Running_Sts : 178|3@0+ (1,0) [0|7] ""  FUSION
 SG_ L_Power_Status : 191|2@0+ (1,0) [0|3] ""  FUSION
 SG_ FAPWL_01_LIN_Response_Error : 189|1@0+ (1,0) [0|1] ""  FUSION
 SG_ L_Drv_Wdw_Obs_InhibitSts : 188|1@0+ (1,0) [0|1] ""  FUSION
 SG_ L_Drv_Wdw_OD_Sts : 187|1@0+ (1,0) [0|1] ""  FUSION
 SG_ L_Drv_Wdw_Init : 186|1@0+ (1,0) [0|1] ""  FUSION
 SG_ L_Drv_OverHeat_Protect : 185|1@0+ (1,0) [0|1] ""  FUSION
 SG_ L_Drv_Motor_Relay_Error : 184|1@0+ (1,0) [0|1] ""  FUSION
 SG_ L_Drv_Motor_Ripple_Error : 199|1@0+ (1,0) [0|1] ""  FUSION
 SG_ L_Drv_Val_Wdw_Opened : 198|7@0+ (1,0) [0|100] "%"  FUSION
 SG_ L_Drv_Wdw_PositionSts : 207|2@0+ (1,0) [0|3] ""  FUSION
 SG_ L_Drv_Wdw_LocalSwitch : 205|3@0+ (1,0) [0|7] ""  FUSION
 SG_ L_Drv_Wdw_Running_Sts : 202|3@0+ (1,0) [0|7] ""  FUSION
 SG_ L_RLD_Wdw_Init : 215|1@0+ (1,0) [0|1] ""  FUSION
 SG_ L_RRD_Val_Wdw_Opened : 214|7@0+ (1,0) [0|100] "%"  FUSION
 SG_ L_RRD_Wdw_PositionSts : 223|2@0+ (1,0) [0|3] ""  FUSION
 SG_ L_RRD_Wdw_Obs_InhibitSts : 221|1@0+ (1,0) [0|1] ""  FUSION
 SG_ L_RRD_Wdw_OD_Sts : 220|1@0+ (1,0) [0|1] ""  FUSION
 SG_ L_RRD_Wdw_Init : 219|1@0+ (1,0) [0|1] ""  FUSION
 SG_ L_RRD_OverHeat_Protect : 218|1@0+ (1,0) [0|1] ""  FUSION
 SG_ L_RRD_Motor_Relay_Error : 217|1@0+ (1,0) [0|1] ""  FUSION
 SG_ L_RRD_Motor_Ripple_Error : 216|1@0+ (1,0) [0|1] ""  FUSION
 SG_ L_RRD_Wdw_LocalSwitch : 231|3@0+ (1,0) [0|7] ""  FUSION
 SG_ L_RRD_Wdw_Running_Sts : 228|3@0+ (1,0) [0|7] ""  FUSION
 SG_ RAPWL_01_LIN_Response_Error : 225|1@0+ (1,0) [0|1] ""  FUSION
 SG_ L_RLD_Wdw_Obs_InhibitSts : 224|1@0+ (1,0) [0|1] ""  FUSION
 SG_ L_RLD_Wdw_OD_Sts : 239|1@0+ (1,0) [0|1] ""  FUSION
 SG_ L_RLD_Val_Wdw_Opened : 238|7@0+ (1,0) [0|100] "%"  FUSION
 SG_ L_RLD_OverHeat_Protect : 247|1@0+ (1,0) [0|1] ""  FUSION
 SG_ L_RLD_Motor_Relay_Error : 246|1@0+ (1,0) [0|1] ""  FUSION
 SG_ L_RLD_Motor_Ripple_Error : 245|1@0+ (1,0) [0|1] ""  FUSION
 SG_ L_RLD_Wdw_PositionSts : 244|2@0+ (1,0) [0|3] ""  FUSION
 SG_ L_RLD_Wdw_LocalSwitch : 242|3@0+ (1,0) [0|7] ""  FUSION
 SG_ L_RLD_Wdw_Running_Sts : 250|3@0+ (1,0) [0|7] ""  FUSION
 SG_ SWC2_HW_Version : 7|16@0+ (0.01,0) [0|655.35] ""  FUSION
 SG_ SWC2_SW_Version : 23|16@0+ (0.01,0) [0|655.35] ""  FUSION
 SG_ SWC2_R_Right_Sta : 39|1@0+ (1,0) [0|1] ""  FUSION
 SG_ SWC2_R_ScrollUp_Sta : 38|1@0+ (1,0) [0|1] ""  FUSION
 SG_ SWC2_R_ScrollPress_Sta : 37|1@0+ (1,0) [0|1] ""  FUSION
 SG_ SWC2_R_ScrollDown_Sta : 36|1@0+ (1,0) [0|1] ""  FUSION
 SG_ SWC2_R_Left_Sta : 35|1@0+ (1,0) [0|1] ""  FUSION
 SG_ SWC2_R_VR_Sta : 34|1@0+ (1,0) [0|1] ""  FUSION
 SG_ SWC2_R_PageSwitch_Sta : 33|1@0+ (1,0) [0|1] ""  FUSION
 SG_ SWC2_R_Customize_Sta : 32|1@0+ (1,0) [0|1] ""  FUSION
 SG_ SWC2_L_Left_Sta : 47|1@0+ (1,0) [0|1] ""  FUSION
 SG_ SWC2_L_ScrollUp_Sta : 46|1@0+ (1,0) [0|1] ""  FUSION
 SG_ SWC2_L_ScrollPress_Sta : 45|1@0+ (1,0) [0|1] ""  FUSION
 SG_ SWC2_L_ScrollDown_Sta : 44|1@0+ (1,0) [0|1] ""  FUSION
 SG_ SWC2_L_Right_Sta : 43|1@0+ (1,0) [0|1] ""  FUSION
 SG_ SWC2_L_RegenUp_Sta : 42|1@0+ (1,0) [0|1] ""  FUSION
 SG_ SWC2_L_ADAS_Sta : 41|1@0+ (1,0) [0|1] ""  FUSION
 SG_ SWC2_L_Home_Sta : 40|1@0+ (1,0) [0|1] ""  FUSION
 SG_ SWC2_ResponseError : 53|1@0+ (1,0) [0|1] ""  FUSION
 SG_ SWC2_R_RegenDown_Sta : 52|1@0+ (1,0) [0|1] ""  FUSION
 SG_ SWC2_L_DriveMode_Sta : 51|1@0+ (1,0) [0|1] ""  FUSION

BO_ 805 ZONE_DR1: 48 ZONE_DR
 SG_ ACT5_Stop_mode : 71|2@0+ (1,0) [0|3] ""  FUSION
 SG_ ACT5_Rotation_direction : 69|2@0+ (1,0) [0|3] ""  FUSION
 SG_ ACT5_Emergency_run_position : 67|2@0+ (1,0) [0|3] ""  FUSION
 SG_ ACT5_Emergency_run_release : 65|2@0+ (1,0) [0|3] ""  FUSION
 SG_ ACT5_Actuator_start_position : 79|16@0+ (1,0) [0|65535] ""  FUSION
 SG_ ACT5_Actuator_set_position : 95|16@0+ (1,0) [0|65535] ""  FUSION
 SG_ ACT5_Speed_specification : 111|4@0+ (1,0) [0|5] ""  FUSION
 SG_ ACT5_Select_position_specificati : 107|2@0+ (1,0) [0|3] ""  FUSION
 SG_ ACT5_Applied_holding_current : 105|2@0+ (1,0) [0|3] ""  FUSION
 SG_ ACT5_Clear_Event_Flags : 119|4@0+ (1,0) [0|15] ""  FUSION
 SG_ ACT5_Stall_detection_release : 115|2@0+ (1,0) [0|3] ""  FUSION
 SG_ ACT5_Save_programming_data : 113|2@0+ (1,0) [0|3] ""  FUSION
 SG_ ACT5_Actuator_address : 127|8@0+ (1,0) [1|126] ""  FUSION
 SG_ ACT4_Stop_mode : 135|2@0+ (1,0) [0|3] ""  FUSION
 SG_ ACT4_Rotation_direction : 133|2@0+ (1,0) [0|3] ""  FUSION
 SG_ ACT4_Emergency_run_position : 131|2@0+ (1,0) [0|3] ""  FUSION
 SG_ ACT4_Emergency_run_release : 129|2@0+ (1,0) [0|3] ""  FUSION
 SG_ ACT4_Actuator_start_position : 143|16@0+ (1,0) [0|65535] ""  FUSION
 SG_ ACT4_Actuator_set_position : 159|16@0+ (1,0) [0|65535] ""  FUSION
 SG_ ACT4_Speed_specification : 175|4@0+ (1,0) [0|5] ""  FUSION
 SG_ ACT4_Select_position_specificati : 171|2@0+ (1,0) [0|3] ""  FUSION
 SG_ ACT4_Applied_holding_current : 169|2@0+ (1,0) [0|3] ""  FUSION
 SG_ ACT4_Clear_Event_Flags : 183|4@0+ (1,0) [0|15] ""  FUSION
 SG_ ACT4_Stall_detection_release : 179|2@0+ (1,0) [0|3] ""  FUSION
 SG_ ACT4_Save_programming_data : 177|2@0+ (1,0) [0|3] ""  FUSION
 SG_ ACT4_Actuator_address : 191|8@0+ (1,0) [1|126] ""  FUSION
 SG_ ACT3_Stop_mode : 199|2@0+ (1,0) [0|3] ""  FUSION
 SG_ ACT3_Rotation_direction : 197|2@0+ (1,0) [0|3] ""  FUSION
 SG_ ACT3_Emergency_run_position : 195|2@0+ (1,0) [0|3] ""  FUSION
 SG_ ACT3_Emergency_run_release : 193|2@0+ (1,0) [0|3] ""  FUSION
 SG_ ACT3_Actuator_start_position : 207|16@0+ (1,0) [0|65535] ""  FUSION
 SG_ ACT3_Actuator_set_position : 223|16@0+ (1,0) [0|65535] ""  FUSION
 SG_ ACT3_Speed_specification : 239|4@0+ (1,0) [0|5] ""  FUSION
 SG_ ACT3_Select_position_specificati : 235|2@0+ (1,0) [0|3] ""  FUSION
 SG_ ACT3_Applied_holding_current : 233|2@0+ (1,0) [0|3] ""  FUSION
 SG_ ACT3_Clear_Event_Flags : 247|4@0+ (1,0) [0|15] ""  FUSION
 SG_ ACT3_Stall_detection_release : 243|2@0+ (1,0) [0|3] ""  FUSION
 SG_ ACT3_Save_programming_data : 241|2@0+ (1,0) [0|3] ""  FUSION
 SG_ ACT3_Actuator_address : 255|8@0+ (1,0) [1|126] ""  FUSION
 SG_ ACT2_Stop_mode : 263|2@0+ (1,0) [0|3] ""  FUSION
 SG_ ACT2_Rotation_direction : 261|2@0+ (1,0) [0|3] ""  FUSION
 SG_ ACT2_Emergency_run_position : 259|2@0+ (1,0) [0|3] ""  FUSION
 SG_ ACT2_Emergency_run_release : 257|2@0+ (1,0) [0|3] ""  FUSION
 SG_ ACT2_Actuator_start_position : 271|16@0+ (1,0) [0|65535] ""  FUSION
 SG_ ACT2_Actuator_set_position : 287|16@0+ (1,0) [0|65535] ""  FUSION
 SG_ ACT2_Speed_specification : 303|4@0+ (1,0) [0|5] ""  FUSION
 SG_ ACT2_Select_position_specificati : 299|2@0+ (1,0) [0|3] ""  FUSION
 SG_ ACT2_Applied_holding_current : 297|2@0+ (1,0) [0|3] ""  FUSION
 SG_ ACT2_Clear_Event_Flags : 311|4@0+ (1,0) [0|15] ""  FUSION
 SG_ ACT2_Stall_detection_release : 307|2@0+ (1,0) [0|3] ""  FUSION
 SG_ ACT2_Save_programming_data : 305|2@0+ (1,0) [0|3] ""  FUSION
 SG_ ACT2_Actuator_address : 319|8@0+ (1,0) [1|126] ""  FUSION
 SG_ ACT1_Stop_mode : 327|2@0+ (1,0) [0|3] ""  FUSION
 SG_ ACT1_Select_position_specificati : 363|2@0+ (1,0) [0|3] ""  FUSION
 SG_ ACT1_Stall_detection_release : 371|2@0+ (1,0) [0|3] ""  FUSION
 SG_ HornSW : 30|1@0+ (1,0) [0|1] ""  FUSION
 SG_ AllLockSta : 25|1@0+ (1,0) [0|1] ""  FUSION
 SG_ AutoLightSW : 35|1@0+ (1,0) [0|1] ""  FUSION
 SG_ BrakeLampFail : 29|1@0+ (1,0) [0|1] ""  FUSION
 SG_ DrLockSta : 24|1@0+ (1,0) [0|1] ""  FUSION
 SG_ WiperSWPos : 47|8@0+ (1,0) [0|255] ""  FUSION
 SG_ RRTurnLampC : 55|8@0+ (10,0) [0|2550] "mA"  FUSION
 SG_ RLTurnLampC : 63|8@0+ (10,0) [0|2550] "mA"  FUSION
 SG_ Wip_Speed : 33|2@0+ (1,0) [0|3] ""  FUSION
 SG_ MIRROR_FOLD_SW : 26|1@0+ (1,0) [0|1] ""  FUSION
 SG_ PsLockSta : 38|1@0+ (1,0) [0|1] ""  FUSION
 SG_ RLLockSta : 37|1@0+ (1,0) [0|1] ""  FUSION
 SG_ RLS_Exist : 39|1@0+ (1,0) [0|1] ""  FUSION
 SG_ RRLockSta : 36|1@0+ (1,0) [0|1] ""  FUSION
 SG_ RWiperAS : 27|1@0+ (1,0) [0|1] ""  FUSION
 SG_ RWiperProtection : 28|1@0+ (1,0) [0|1] ""  FUSION
 SG_ WiperZeroPosSW : 34|1@0+ (1,0) [0|1] ""  FUSION
 SG_ RLTurnLPErr : 23|1@0+ (1,0) [0|1] ""  FUSION
 SG_ RRTurnLPErr : 22|1@0+ (1,0) [0|1] ""  FUSION
 SG_ ZDR_THCM_IntakeFail_Sta : 15|2@0+ (1,0) [0|2] ""  FUSION
 SG_ ZDR_THCM_LINACT1_Sta : 11|2@0+ (1,0) [0|2] ""  FUSION
 SG_ ZDR_THCM_LINACT2_Sta : 9|2@0+ (1,0) [0|2] ""  FUSION
 SG_ ZDR_THCM_LINACT3_Sta : 21|2@0+ (1,0) [0|2] ""  FUSION
 SG_ ZDR_THCM_LINACT4_Sta : 19|2@0+ (1,0) [0|2] ""  FUSION
 SG_ ZDR_THCM_LINACT5_Sta : 17|2@0+ (1,0) [0|2] ""  FUSION
 SG_ ZDR_THCM_ModeFail_Sta : 13|2@0+ (1,0) [0|2] ""  FUSION
 SG_ ACT1_Actuator_address : 383|8@0+ (1,0) [1|126] ""  FUSION
 SG_ ACT1_Actuator_set_position : 351|16@0+ (1,0) [0|65535] ""  FUSION
 SG_ ACT1_Actuator_start_position : 335|16@0+ (1,0) [0|65535] ""  FUSION
 SG_ ACT1_Applied_holding_current : 361|2@0+ (1,0) [0|3] ""  FUSION
 SG_ ACT1_Clear_Event_Flags : 375|4@0+ (1,0) [0|15] ""  FUSION
 SG_ ACT1_Emergency_run_position : 323|2@0+ (1,0) [0|3] ""  FUSION
 SG_ ACT1_Emergency_run_release : 321|2@0+ (1,0) [0|3] ""  FUSION
 SG_ ACT1_Rotation_direction : 325|2@0+ (1,0) [0|3] ""  FUSION
 SG_ ACT1_Speed_specification : 367|4@0+ (1,0) [0|5] ""  FUSION
 SG_ ACT1_Save_programming_data : 369|2@0+ (1,0) [0|3] ""  FUSION

CM_ SG_ 278 CS_VCU1_CAN4 "Checksum of VCU1(AUTOSAR E2E profile 1)

Polynomial 0x1D (x^8+x^4+x^3+x^2+1) Both start value and XOR value are 0x00.";
CM_ SG_ 278 RC_VCU1_CAN4 "VCU1 4-bit rolling counter
It starts counting from 0, ends at 14 and returns to zero (0~14).";
CM_ SG_ 278 Dr_SeatSta "Driver seat switch state";
CM_ SG_ 278 MSA_Crl_Sta "MSA Status";
CM_ SG_ 278 CC_Crl_Sta "Cruise Control Status";
CM_ SG_ 278 ShiftGearPosn "EV Selector Position Status/ Selector Position Status Signal Failure";
CM_ SG_ 278 PwrSta "Vehicle Power Status";
CM_ SG_ 278 ReBrakeLPReq "Regen brake lamp request";
CM_ SG_ 278 DKCTimeSN "DKC time serial number";
CM_ SG_ 278 TimeSNDKCFbk "Time serial number DKC feedback";
CM_ SG_ 278 EquivAccPedalSWSta "ADAS equivalent acceleration pedal switch status";
CM_ SG_ 278 HornCtrl "Horn Control";
CM_ SG_ 278 BCM_DoorLock_Sta "BCM Unlock Single Door Setting";
CM_ SG_ 278 DimmerEN "Dimmer Enable";
CM_ SG_ 278 RoomLampH "Room Lamp High";
CM_ SG_ 278 RoomLampL "Room Lamp Low";
CM_ SG_ 278 TailgateRemote "Remote Control PTG";
CM_ SG_ 278 Dimmer "Dimmer";
CM_ SG_ 278 LockSetting "BCM Unlock Single Door Setting";
CM_ SG_ 278 L_APM_WdwEnable "Enable windows movement";
CM_ SG_ 278 CrashDetd "Crash Detected";
CM_ SG_ 278 AntiTheftSeatFold "Anti-theft Seat Fold";
CM_ SG_ 278 AntitheftSta "Anti-theft Status";
CM_ SG_ 278 RTurnLP "Right Turn Lamp";
CM_ SG_ 278 LTurnLP "Left Turn Lamp";
CM_ SG_ 278 HazardSW "Hazard SW";
CM_ SG_ 278 Rr_FogLamp "Rear Fog Lamp";
CM_ SG_ 278 Fr_FogLamp "Front Fog Lamp";
CM_ SG_ 278 RBSD "Right BSD";
CM_ SG_ 278 LBSD "Left BSD";
CM_ SG_ 278 BrakeLamp "BrakeLamp";
CM_ SG_ 278 ReverseLamp "ReverseLamp";
CM_ SG_ 278 RDRL "Right DRL";
CM_ SG_ 278 LDRL "Left DRL";
CM_ SG_ 278 PosLamp "PositionLamp";
CM_ SG_ 278 H_Beam "High Beam";
CM_ SG_ 278 L_Beam "Low Beam";
CM_ SG_ 278 WasherCtrl "WasherControl";
CM_ SG_ 278 WiperFixMode "Wiper Fix Mode";
CM_ SG_ 278 Rr_Wiper "Rear Wiper";
CM_ SG_ 278 Fr_Wiper_L "Front Wiper LOW";
CM_ SG_ 278 Fr_Wiper_H "Front Wiper High";
CM_ SG_ 278 MirrorCtrl "Mirror Control";
CM_ SG_ 278 TailgateHDSW "Tailgate Handle SW";
CM_ SG_ 278 TrunkRel "Trunk Release";
CM_ SG_ 278 Rr_Defog "Rear Defog";
CM_ SG_ 278 Fr_ChargingDoorCtrl "Front Charging Door Control";
CM_ SG_ 278 HoodSW "Hood Switch";
CM_ SG_ 278 DoorLockIND "Door Lock Indicator";
CM_ SG_ 278 AllDoorSW "All Door Switch";
CM_ SG_ 278 RRDoorSW "Rear Right Door Switch";
CM_ SG_ 278 RLDoorSW "Rear Left Door Switch";
CM_ SG_ 278 PsDoorSW "Passenger Side Door Switch";
CM_ SG_ 278 Rr_ChargingDoorCtrl "Rear Charging Door Control";
CM_ SG_ 278 CTDCtrl "Door Lock Control";
CM_ SG_ 278 FD_TBOX_VehData_Sta "Response the Status of  VehData to TBOX";
CM_ SG_ 278 FD_TBOX_VehData_Err "Response the Error of  VehData to TBOX";
CM_ SG_ 278 FD_DKC_VehData_Sta "Response the Status of  VehData to DKC";
CM_ SG_ 278 FD_DKC_VehData_Err "Response the Error of  VehData to DKC";
CM_ SG_ 278 FD_TBOX_DTCData_Sta "Response the Status of  DTCData to TBOX";
CM_ SG_ 278 FD_TBOX_DTCData_Err "Response the Error of  DTCData to TBOX";
CM_ SG_ 278 LampPwr "Lamp Power";
CM_ SG_ 278 DKCAuthSta "DKC authentication status";
CM_ SG_ 278 MirrorDefog "Mirror Defog";
CM_ SG_ 278 DrDoorSW "Driver Side Door Switch";
CM_ SG_ 278 CTDLockSW "Central Door Lock SW";
CM_ SG_ 278 CTDUnlockSW "Central Door Unlock SW";
CM_ SG_ 278 Tailgate_SW "Tailgate Switch";
CM_ SG_ 278 HWResetSta "Hardware reset state";
CM_ SG_ 278 CtrlFrBMSCCUCIR "Control zone Fr BMSCCUCIR  pin signal";
CM_ SG_ 278 CtrlFrEDUINVERTER "Control zone Fr EDUINVERTER  pin signal";
CM_ SG_ 278 CtrlFrIRC1 "Control zone Fr IRC1 plus pin signal";
CM_ SG_ 278 CtrlFrPwrStbA1P "Control zone Fr power standby A1 plus pin signal";
CM_ SG_ 278 CtrlDrPwrStbA2 "Control zone Dr power standby A2  pin signal";
CM_ SG_ 278 H_Beam_ADB "High Beam for ADB";
CM_ SG_ 278 APS_Sta_System "The operation status of APA system";
CM_ SG_ 386 CCU_HEATMaxLampSts "Climate HEATING Max lamp state";
CM_ SG_ 386 CCU_ACLampSts "Climate AC lamp state";
CM_ SG_ 386 CCU_Dispaly_Request "Air Conditioner display reuqest trigger";
CM_ SG_ 386 CCU_EcoSts "Economic mode status";
CM_ SG_ 386 CCU_AutoMidLampSts "Climate air conditionning middle left automatic mode lamp state";
CM_ SG_ 386 CCU_AutoLampSts "Climate air conditionning Front  automatic mode lamp state";
CM_ SG_ 386 CCU_ACMaxLampSts "Climate AC Max lamp state";
CM_ SG_ 386 Fr_Coolanttemp "LLC coolant temp";
CM_ SG_ 386 CCU_RrOnOffLampSts "Rear Climate On Off lamp state";
CM_ SG_ 386 CCU_FrtOnOffLampSts "Front Climate On Off lamp state";
CM_ SG_ 386 CCU_SyncLampSts "Climate SYNC lamp state";
CM_ SG_ 386 HPThermalRecoveryReq "Heat Pump thermal reuse request";
CM_ SG_ 386 EDriveMode "E-Drive Mode";
CM_ SG_ 386 Fr_Coolantflow "LLC coolant flow rate";
CM_ SG_ 386 FD_RecyAuto_Cmd "Auto recycle command";
CM_ SG_ 386 BatteryMode "Battery Mode";
CM_ SG_ 386 CabinMode "Cabin Mode";
CM_ SG_ 386 Rr_Coolanttemp "LLC coolant temp";
CM_ SG_ 386 FD_Blower_Cmd "Fusion Domain Blower Command";
CM_ SG_ 386 FD_SOV3_Cmd "Fusion Domain SOV3 Command";
CM_ SG_ 386 FD_SOV2_Cmd "Fusion Domain SOV2 Command";
CM_ SG_ 386 FD_SOV1_Cmd "Fusion Domain SOV1 Command";
CM_ SG_ 386 FD_SOTXV_Cmd "Fusion Domain SOTXV Command";
CM_ SG_ 386 FD_FWV_Cmd "Fusion Domain Four Way Valve Position Request";
CM_ SG_ 386 CCU_HiVoltageReq "High voltage request";
CM_ SG_ 386 FD_Comp_Cmd "Fusion Domain Compressor Request";
CM_ SG_ 386 CCU_CbnPreSts "Cabin Preconditioning Status
It shall stay as Off if A/C is turned on not by preconditioning request";
CM_ SG_ 386 DeiceModReq "Deice mode request";
CM_ SG_ 386 CCU_CbnPreACWkSts "Cabin Preconditioning A/C work status";
CM_ SG_ 386 FD_EXV1_Cmd "Fusion Domain Chiller EXV Command";
CM_ SG_ 386 CCU_CbnPreEstimdTi "Maximum Estimated Time to achieve the target temperature in minutes(Value 61,62 for reserved, value 63 for Invalid)
0x3d~0x3E:Reserved";
CM_ SG_ 386 FD_EXV2_Cmd "Fusion Domain HPChiller EXV Command";
CM_ SG_ 386 FD_TWV_Cmd "Fusion Domain Three Way Valve Position Request";
CM_ SG_ 386 FD_FrRiAPTCHeatPwr_Cmd "Fusion Domain Front Right Air PTC Heat Power Request";
CM_ SG_ 386 FD_FrLeAPTCHeatPwr_Cmd "Fusion Domain Front Left Air PTC Heat Power Request";
CM_ SG_ 386 FD_RrAPTCHeatPwr_Cmd "Fusion Domain Rear Air PTC Heat Power Request";
CM_ SG_ 386 FD_FrWPTCHeatPwr_Cmd "Fusion Domain Front Water PTC Heat Power Request";
CM_ SG_ 386 FD_EWP3_Cmd "Fusion Domain Battery Water Pump Command";
CM_ SG_ 386 FD_EWP2_Cmd "Fusion Domain FrTM Water Pump Command";
CM_ SG_ 386 FD_EWP1_Cmd "Fusion Domain RrTM Water Pump Command";
CM_ SG_ 386 APTC_ActFrRiPwr "Air PTC actual power front right";
CM_ SG_ 386 BatLoopActWtFlw "Battery loop actual water flow";
CM_ SG_ 386 CoolgFanActDuty "Cooling fan actual duty cycle (PWM)";
CM_ SG_ 386 sigRecircSt "Recirculation Status in the HVAC (Fre/Rec/Auto)";
CM_ SG_ 386 sigWindDirZon1St "Feedback: WInd DirectionZone 1. 
Feed, Body, WIndscreen and/or Auto";
CM_ SG_ 386 Rr_Coolantflow "LLC coolant flow rate";
CM_ SG_ 386 sigHvacSt "Status of the HVAC (ON / OFF)";
CM_ SG_ 386 sigSetTempZon1St "Feedback: Temperature set in the HVAC for Zone 1";
CM_ SG_ 386 sigSetTempZon2St "Feedback: Temperature set in the HVAC for Zone 2";
CM_ SG_ 386 sigSetTempZon3St "Feedback: Temperature set in the HVAC for Zone 3";
CM_ SG_ 386 sigWindDirZon3St "Feedback: WInd DirectionZone 3. 
Feed, Body and/or Auto";
CM_ SG_ 386 ACSubMode "AC system sub mode";
CM_ SG_ 386 FDC_THCM_CLEVentY_Sta "Y Status of Electric Vent on CTR-LH";
CM_ SG_ 386 sigAirIntenZon1St "Feedback FAN Level/Air Intensirty : 0-Max or Auto for zone 1";
CM_ SG_ 386 sigAirIntenZon3St "Feedback FAN Level/Air Intensirty : 0-Max or Auto for zone 3";
CM_ SG_ 386 sigAmbAirT "Environment temperature (outside ambient vehicle temperature)";
CM_ SG_ 386 sigCbnAirT "Cabin air temperature";
CM_ SG_ 386 sigCbnPTCPwrAct "Current power consumption FRONT AirPTC";
CM_ SG_ 386 sigCbnSolarLeft "Measured cabin sun exposure";
CM_ SG_ 386 sigCbnSolarRight "Measured cabin sun exposure";
CM_ SG_ 386 sigClmtCmprPwrAct "Current power consumption AC compressor";
CM_ SG_ 386 sigClntTHvBattOut "battery coolant outlet temperature";
CM_ SG_ 386 sigDfrstSt "Defrost Status in the HVAC (ON / AUTO)";
CM_ SG_ 386 FDC_THCM_CLEVentZ_Sta "Z Status of Electric Vent on CTR-LH";
CM_ SG_ 386 FDC_THCM_CLVent_Sta "CTR-LH Vent on off";
CM_ SG_ 386 FDC_THCM_CREVentY_Sta "Y Status of Electric Vent on CTR-RH";
CM_ SG_ 386 FDC_THCM_CREVentZ_Sta "Z Status of Electric Vent on CTR-RH";
CM_ SG_ 386 FDC_THCM_CRVent_Sta "CTR-RH Vent on off";
CM_ SG_ 386 FDC_THCM_DrEVentMode_Sta "Electric Vent Mode on Driver Side";
CM_ SG_ 386 FDC_THCM_DrEVentY_Sta "Y Status of Electric Vent on LH";
CM_ SG_ 386 FDC_THCM_DrEVentZ_Sta "Z Status of Electric Vent on LH";
CM_ SG_ 386 FDC_THCM_DrVent_Sta "LH Vent on off";
CM_ SG_ 386 FDC_THCM_PsEVentMode_Sta "Electric Vent Mode on Passenger Side";
CM_ SG_ 386 FDC_THCM_PsEVentY_Sta "Y Status of Electric Vent on RH";
CM_ SG_ 386 FDC_THCM_PsEVentZ_Sta "Z Status of Electric Vent on RH";
CM_ SG_ 386 FDC_THCM_PsVent_Sta "RH Vent on off";
CM_ SG_ 535 FDLHandleLampCmd "Door Handle Lamp Command for Zone_L";
CM_ SG_ 535 FDRHandleLampCmd "Door Handle Lamp Command for Zone_R";
CM_ SG_ 535 AmbLightColor1 "RGB 64 Color";
CM_ SG_ 535 BCM_Buzzer_Req "BCM Buzzer Request";
CM_ SG_ 535 AmbLightColor2 "RGB 64 Color";
CM_ SG_ 535 AmbLightColor3 "RGB 64 Color";
CM_ SG_ 535 FDHandleCmd "Door Handle Command";
CM_ SG_ 535 AmbLightColor4 "RGB 64 Color";
CM_ SG_ 535 AmbLightColor5 "RGB 64 Color";
CM_ SG_ 535 AmbLightColor6 "RGB 64 Color";
CM_ SG_ 535 AmbLightBrightness1 "Atmosphere Lamp 1 Bright adjustment";
CM_ SG_ 535 AmbLightBrightness2 "Atmosphere Lamp 2 Bright adjustment";
CM_ SG_ 535 AmbLightBrightness3 "Atmosphere Lamp 3 Bright adjustment";
CM_ SG_ 535 AmbLightBrightness4 "Atmosphere Lamp 4 Bright adjustment";
CM_ SG_ 535 AmbLightBrightness5 "Atmosphere Lamp 5 Bright adjustment";
CM_ SG_ 535 AmbLightBrightness6 "Atmosphere Lamp 6 Bright adjustment";
CM_ SG_ 535 AmbLightBreath1 "Atmosphere Lamp 1 Breathing Mode";
CM_ SG_ 535 AmbLightBreath2 "Atmosphere Lamp 2 Breathing Mode";
CM_ SG_ 535 AmbLightBreath3 "Atmosphere Lamp 3 Breathing Mode";
CM_ SG_ 535 AmbLightBreath4 "Atmosphere Lamp 4 Breathing Mode";
CM_ SG_ 535 AmbLightBreath5 "Atmosphere Lamp 5 Breathing Mode";
CM_ SG_ 535 AmbLightBreath6 "Atmosphere Lamp 6 Breathing Mode";
CM_ SG_ 535 WelcomeLight "Welcome mode Signal";
CM_ SG_ 535 FDC_BCM_TurnSwTSetSta_Sta "Turn Switch Time Set status";
CM_ SG_ 535 FDC_BCM_UserHeightSet_Sta "PTG user setting max open height";
CM_ SG_ 535 FDC_BCM_UserNow_Sta "Current User Number";
CM_ SG_ 535 FDC_DKC_CommandToBCM_Cmd "DKC command to BCM";
CM_ SG_ 535 FDC_DKC_DKeyAreaPE_Sta "Digital key  Lock and Unlock Area";
CM_ SG_ 535 FDC_BCM_PTGOpenHeight_Sta "PTG max open height";
CM_ SG_ 535 FDC_BCM_ATCtrl_Cmd "Antitheft Lamp Control";
CM_ SG_ 535 FDC_BCM_LockAlarm_Cmd "Lock alarm command";
CM_ SG_ 535 FDC_BCM_FWipSw_Sta "(FD_BCM combines the results of CAN CSW and LIN CSW)";
CM_ SG_ 535 FDC_BCM_TurnSw_Sta "CSW_TurnSw_Sta_CANbus (FD_BCM combines the results of CAN CSW and LIN CSW)";
CM_ SG_ 535 FDC_BCM_FWasSw_Sta "CSW_FWasherSW_Sta (FD_BCM combines the results of CAN CSW and LIN CSW)";
CM_ SG_ 535 FDC_BCM_PassSW_Sta "Passing Switch Status (FD_BCM combines the results of CAN CSW and LIN CSW)";
CM_ SG_ 535 FDC_BCM_DimSw "CSW_DimSw (FD_BCM combines the results of CAN CSW and LIN CSW)";
CM_ SG_ 535 FDC_THCM_ACTInitial_Cmd "Actuator Initial Command";
CM_ SG_ 535 FDC_DKC_SPTGDet_Cmd "SPTG Detect ";
CM_ SG_ 535 FDC_DKC_SPTGOpen_Cmd "SPTG open request";
CM_ SG_ 535 FDC_BCM_HazardIND_Cmd "Hazard Indicator";
CM_ SG_ 535 FDC_THCM_AirIntZ3_Sta "Air Volume state in Zone 3";
CM_ SG_ 535 FDC_BCM_OutMode_Cmd "Output mode for turn lamps";
CM_ SG_ 535 FDC_EChrg_SW_Sta "FDC EchrgPort switch state";
CM_ SG_ 595 IVI_Located_STA "IVI_GPS Satellite Located status";
CM_ SG_ 595 Approach_Unlock_SW "Unlock when approaching Switch";
CM_ SG_ 595 Walkaway_Lock_SW "Lock when walking away";
CM_ SG_ 595 BrkSw_Sta "Brake switch signal status";
CM_ SG_ 595 DSEAT_anti_set "Driver Seat Antitheft on/off request";
CM_ SG_ 595 DSEAT_entryfun_set "Driver Seat Entry on/off request";
CM_ SG_ 595 IVI_PTG_Mode_SW "Power Tail Gate Manual and Automatic mode Switch";
CM_ SG_ 595 PSEAT_vent_req "Passenger Seat Ventilate request
0= No Request,
1= Vent1,
2= Vent2,
3= Vent3,
4= Off";
CM_ SG_ 595 IVI_PTG_Sta_SW "Power Tail Gate Open and Close Switch";
CM_ SG_ 595 IVI_ISA_OffsetSpd "IVI ISA Offset speed";
CM_ SG_ 595 SenstivityPosition "wiper Senstivity Position";
CM_ SG_ 595 IVI_Time_Check "IVI_GPS Satellite Time_Check Sum";
CM_ SG_ 595 Distance_unit "Distance unit";
CM_ SG_ 595 IVI_Time_Year "IVI_GPS Satellite Time_Year";
CM_ SG_ 595 Hood_Latch_SW "Hood Latch Switch";
CM_ SG_ 595 IVI_Time_Minute "IVI_GPS Satellite Time_Minute";
CM_ SG_ 595 IVI_Time_Second "IVI_GPS Satellite Time_Second";
CM_ SG_ 595 DSEAT_vent_req "Driver Seat ventilate request";
CM_ SG_ 595 IVI_Time_Day "IVI_GPS Satellite Time_Day";
CM_ SG_ 595 HeadLampSW "Head Lamp Switch";
CM_ SG_ 595 IVI_Time_Hour "IVI_GPS Satellite Time_Hour";
CM_ SG_ 595 IVI_Time_Month "IVI_GPS Satellite Time_Month";
CM_ SG_ 595 IVI_DSEATHeater_Cmd "IVI Driver seat heater request";
CM_ SG_ 595 IVI_PSEATHeater_Cmd "IVI Passenger seat heater request";
CM_ SG_ 595 FDC_PTG_inner_SW_2 "FD routing Power Tail Gate Inner SW#2 State to DKC";
CM_ SG_ 595 BrkSw_V "Brake switch signal Vaild";
CM_ SG_ 595 MCPressure "Master Cylinder Pressure";
CM_ SG_ 595 MCPressure_V "Master Cylinder Pressure Validity";
CM_ SG_ 595 BrkPedalPos "Brake Pedal Position";
CM_ SG_ 595 BrkPedalPos_Sta "Brake Pedal Position Status";
CM_ SG_ 595 VehSpeed "Vehicle Speed";
CM_ SG_ 595 L_Drv_CtrlCmd "Driver Window Control  Command
FDC BCM Tx";
CM_ SG_ 595 L_Pas_CtrlCmd "Passenger Window Control  Command
FDC BCM Tx";
CM_ SG_ 595 L_RLD_CtrlCmd "Rear Left Window Control  Command
FDC BCM Tx";
CM_ SG_ 595 L_RRD_CtrlCmd "Rear Right Window Control  Command
FDC BCM Tx";
CM_ SG_ 595 OFF_AC_MODE "OFF AC MODE";
CM_ SG_ 595 WlcmLight_Mode "Welcome Light Mode";
CM_ SG_ 595 Light_ShowStart_Req "Light Show Start Request";
CM_ SG_ 595 Light_ShowStop_Req "Light Show Stop Request";
CM_ SG_ 595 AVM_parking_excute "confirm and start to auto parking";
CM_ SG_ 595 IVI_PTG_Open_Height "IVI 'PTG Open Height' Menu Status";
CM_ SG_ 595 TBOX_Remote_PW "TBOX_Remote_PW";
CM_ SG_ 595 METER_KPH_Calcu "METER Calculated Speed(KPH)";
CM_ SG_ 595 ChrgInLockReq "ChargeInlet Lock Request";
CM_ SG_ 595 IVI_TrailerCheckReq_Sta "Trailer Check request";
CM_ SG_ 595 IVI_TrailerModeSW_Sta "Trailer Mode Switch";
CM_ SG_ 595 IVI_ChargePortSW_Sta "IVI Charge Port Switch";
CM_ SG_ 595 ChrgPlugSta "Charger plug status";
CM_ SG_ 595 ExtChrgSta "External charging status";
CM_ SG_ 595 OBCV2LSta "OBC V2L Status";
CM_ SG_ 595 V2LSta "V2L Adapter Status";
CM_ SG_ 1080 OTA_Progress_Rate "MDA download or update progress rate";
CM_ SG_ 1080 OTA_MDA_Status "Fusion Master OTA agent status";
CM_ SG_ 1080 OTA_Network_Type "Vehicle Network Type";
CM_ SG_ 1080 OTA_Mode "Vehicel OTA mode Status";
CM_ SG_ 1080 OTA_DL_Available "Fusion MDA available for download";
CM_ SG_ 1080 OTA_InVehicle_FW "In Vehicle Firmware Version Status";
CM_ SG_ 1080 OTA_Update_Available "Fusion MDA available for update";
CM_ SG_ 1080 OTA_Updating_ECU_8bit "Fusion MDA is updating ECU";
CM_ SG_ 1080 OTA_Lock_Req "OTA Lock request to DKC";
CM_ SG_ 1080 OTA_TBOXResetReq "TBOX Reset Request";
CM_ SG_ 1080 OTA_DL_Speed "Firmware Package download speed";
CM_ SG_ 1080 OTA_Permit_Agreed "Download/Upgrade coundition check result";
CM_ SG_ 1080 OTA_Remained_Time "Download/Upgrade Estimated Time";
CM_ SG_ 1080 OTA_Debug_Code "OTA Error Code for Debug";
CM_ SG_ 1080 OTA_Emergency_Sta "Fusion emergency state";
CM_ SG_ 1280 NM_FUSION_Node_ID "Source Node Identifier";
CM_ SG_ 1280 NM_FUSION_PNI "Partial Network Information Bit (PNI)";
CM_ SG_ 1280 NM_FUSION_Active_WU "Active Wakeup Bit";
CM_ SG_ 1280 NM_FUSION_CSB "NM Coordinator Sleep Bit";
CM_ SG_ 1280 NM_FUSION_Rpt_Msg_Req "Repeat Message Request";
CM_ SG_ 1280 NM_FUSION_ERROR_State "Defined Error states of the CAN Controller";
CM_ SG_ 1668 DiagPhysReqToZONE_FR "Diagnostic Physical Request to ZONE_FR";
CM_ SG_ 1669 DiagPhysReqToDKC "Diagnostic Physical Request to DKC";
CM_ SG_ 1701 DiagPhysReqToAirPTC "Diagnostic Physical Request to AirPTC";
CM_ SG_ 1717 DiagPhysReqToWPTC "Diagnostic Physical Request to WPTC";
CM_ SG_ 1728 DiagPhysReqToZONE_DR "Diagnostic Physical Request to ZONE_DR";
CM_ SG_ 1733 DiagPhysReqToCompressor "Diagnostic Physical Request to Compressor";
CM_ SG_ 2000 DiagFuncReqFT "Diagnostic Functional Request from Tester";
CM_ SG_ 1174 TimeSyncFromBS_Year "Time Sync. From Base Station of Year";
CM_ SG_ 1174 TimeSyncFromBS_Minute "Time Sync. From Base Station of Minute";
CM_ SG_ 1174 TimeSyncFromBS_Second "Time Sync. From Base Station of Second";
CM_ SG_ 1174 TimeSyncFromBS_Day "Time Sync. from Base Station - DAY";
CM_ SG_ 1174 TimeSyncFromBS_Hour "Time Sync. From Base Station of Hour";
CM_ SG_ 1174 TimeSyncFromBS_Month "Time Sync. From Base Station of  Month";
CM_ SG_ 497 DrPMMSysErrLmp "PMM system error lamp request";
CM_ SG_ 497 DrPMMLVOutPErrLmp "PMM LV output error lamp request";
CM_ SG_ 497 DrPMMLimpHomeActReq "PMM Limp Home act request";
CM_ SG_ 497 DrAPWStaErr "APW relay error state";
CM_ SG_ 497 DrIVIFault "Zone Dr 'IVI' pin fault state";
CM_ SG_ 497 DrEOBDFault "Zone Dr 'EOBD' pin fault state";
CM_ SG_ 497 DrInfoFault "Zone Dr 'Information' pin pin fault state";
CM_ SG_ 497 DrPwrWindowECUFault "Zone Dr 'Power_Window_ECU' pin fault state";
CM_ SG_ 497 DrTHCMFault "Zone Dr 'THCM' pin fault state";
CM_ SG_ 497 DrColumnSWFault "Zone Dr 'ColumnSW' pin fault state";
CM_ SG_ 497 DrADASCurr "Zone Dr 'ADAS' pin electric current";
CM_ SG_ 497 DrAuBoxPwrN2Curr "Zone Dr 'AUDIO BOX POWER NODE2' pin electric current";
CM_ SG_ 497 DrAuBoxPwrN1Curr "Zone Dr 'AUDIO BOX POWER NODE1' pin electric current";
CM_ SG_ 497 DrPwrStdbyACurr "Zone Dr 'Power_Standby_A' pin electric current";
CM_ SG_ 497 DrPwrONA2Curr "Zone Dr 'Power_ON_A2' pin electric current";
CM_ SG_ 497 DrPwrONA1Curr "Zone Dr 'Power_ON_A1' pin electric current";
CM_ SG_ 497 Blower_FB "Blower Feedback";
CM_ SG_ 497 DrCtrlBDVolt "Detect voltage on ZONE Ctrl board";
CM_ SG_ 497 DrCtrlTemp "Detect temperature on ZONE Ctrl board";
CM_ SG_ 497 DrPowerTemp1 "Detect temperature on ZONE power board";
CM_ SG_ 497 DrPowerTemp2 "Detect temperature on ZONE power board";
CM_ SG_ 497 T_Foot_R "Right Foot Temperature";
CM_ SG_ 497 T_Foot_Rr "Rear Foot Temperature";
CM_ SG_ 497 T_Face_Rr "Rear Face Temperature";
CM_ SG_ 497 T_Foot_L "Left Foot Temperature";
CM_ SG_ 497 T_Face_R "Right Face Temperature";
CM_ SG_ 497 T_Face_L "Left Face Temperature";
CM_ SG_ 497 Tevap "Evaporator Temperature";
CM_ SG_ 497 Tincar "Incar Temperature";
CM_ SG_ 497 SolarR "cabin sun exposure Right";
CM_ SG_ 497 SolarL "cabin sun exposure Left";
CM_ SG_ 497 APTC_Err "Air PTC error";
CM_ SG_ 497 Blower_Err "Blower error";
CM_ SG_ 497 T_Foot_Rr_Err "Foot wind direction rear duct temperature sensor error";
CM_ SG_ 497 T_Face_Rr_Err "Face wind direction rear duct temperature sensor error";
CM_ SG_ 497 T_Foot_R_Err "Foot wind direction in right side duct temperature sensor error";
CM_ SG_ 497 T_Face_R_Err "Face wind direction in right side duct temperature sensor error";
CM_ SG_ 497 T_Foot_L_Err "Foot wind direction in left side duct temperature sensor error";
CM_ SG_ 497 T_Face_L_Err "Face wind direction in left side duct temperature sensor error";
CM_ SG_ 497 Tincar_Err "In-cabin temperature sensor error";
CM_ SG_ 497 Tevap_Err "Evaporator temperature sensor error";
CM_ SG_ 497 SolarR_Err "Solar sensor right error";
CM_ SG_ 497 SolarL_Err "Solar sensor left error";
CM_ SG_ 497 DrSCPSysErrLmp "SCP system error lamp  request ";
CM_ SG_ 497 ZoneDrMalfunLevel "Zone Dr VCU error level";
CM_ SG_ 497 DrAPWLINErr "APW LIN lost communication";
CM_ SG_ 497 DrONA1ErrSta "Zone Dr power ON A1 power pin error state";
CM_ SG_ 497 DrStdAErrSta "Zone Dr power standby A power pin error  state";
CM_ SG_ 497 DrPwrWinErrSta "Zone Dr power window power pin error  state";
CM_ SG_ 497 DrInfoErrSta "Zone Dr information power pin error  state";
CM_ SG_ 497 RegenSW_Err "regen switch error";
CM_ SG_ 497 DrPwrSta "DR PwrSta transmit";
CM_ SG_ 497 DrPwrInformationSta "Information pin B+ power request status";
CM_ SG_ 497 ZDR_SYS_APMRetryCnt_Sta "Zone DR APM power output pin retry count";
CM_ SG_ 497 ZDR_SYS_CSWRetryCnt_Sta "Zone DR ColumnSW power output pin retry count";
CM_ SG_ 497 ZDR_SYS_BSWSleepReq_Sta "Zone DR sleep request from BSW";
CM_ SG_ 497 ZDR_VCU_HWReset_Sta "Zone Dr VCU hardware reset state";
CM_ SG_ 497 ZDR_VCU_PwrSupply_Sta "Zone Dr VCU power supply state";
CM_ SG_ 498 FrPwrStdbyA2PlusCurr "Zone Fr 'Power_Standby_A2+' pin electric current";
CM_ SG_ 498 FrBMS_CCU_CIRCurr "Zone Fr 'BMS_CCU_CIR' pin electric current";
CM_ SG_ 498 FrEDU_INVERTERCurr "Zone Fr 'INVERTER' pin electric current";
CM_ SG_ 498 FrPwrStdbyA1PlusFault "Zone Fr 'Power_Standby_A1+' pin fault state";
CM_ SG_ 498 FrPwrStdbyA2PlusFault "Zone Fr 'Power_Standby_A2+' pin fault state";
CM_ SG_ 498 FrPwrONA1Fault "Zone Fr 'Power_ON_A1' pin fault state";
CM_ SG_ 498 FrBMS_CCU_CIRFault "Zone Fr 'BMS_CCU_CIR' pin fault state";
CM_ SG_ 498 FrEDU_INVERTERFault "Zone Fr 'INVERTER' pin fault state";
CM_ SG_ 498 FrPwrStdbyA1Fault "Zone Fr 'Power_Standby_A1' pin fault state";
CM_ SG_ 498 FrPMMSysErrLmp "PMM system error lamp request";
CM_ SG_ 498 FrPMMLVOutPErrLmp "PMM LV output error lamp request";
CM_ SG_ 498 FrPMMLimpHomeActReq "PMM Limp Home act request";
CM_ SG_ 498 ZoneFrMalfunLevel "Zone Fr VCU error level";
CM_ SG_ 498 FrIRC_1Curr "Zone Fr 'IRC_1' pin electric current";
CM_ SG_ 498 FrPwrStdbyA2Curr "Zone Fr 'Power_Standby_A2' pin electric current";
CM_ SG_ 498 FrPwrONA3Curr "Zone Fr 'Power_ON_A3' pin electric current";
CM_ SG_ 498 FrPwrONA2Curr "Zone Fr 'Power_ON_A2' pin electric current";
CM_ SG_ 498 FrStdA1PCErr "Zone Fr power standby A1 plus power pin current error state";
CM_ SG_ 498 FrStdA2PErr "Zone Fr power standby A2 plus power pin error state";
CM_ SG_ 498 FrStdA2PCErr "Zone Fr power standby A2 plus power pin current error state";
CM_ SG_ 498 FrBMSCCUCErr "Zone Fr BMS CCU power pin current error state";
CM_ SG_ 498 FrEDUErr "Zone Fr EDU power pin current error state";
CM_ SG_ 498 FrIRC_2Curr "Zone Fr 'IRC_2' pin electric current";
CM_ SG_ 498 FrPwrStdbyA1PlusCurr "Zone Fr 'Power_Standby_A1+' pin electric current";
CM_ SG_ 498 FrPwrSta "FR PwrSta transmit";
CM_ SG_ 498 FrCtrlBDVolt "Detect voltage on ZONE Ctrl board";
CM_ SG_ 498 FrCtrlTemp "Detect temperature on ZONE Ctrl board";
CM_ SG_ 498 FrPowerTemp2 "Detect temperature on ZONE power board";
CM_ SG_ 498 FrPowerTemp1 "Detect temperature on ZONE power board";
CM_ SG_ 498 PT_High_Tact "actual temperature of PT SENSOR_HIGH";
CM_ SG_ 498 EACProtectEnable "E-compressor protect enable";
CM_ SG_ 498 PT_High_P "Comp dis Pressure";
CM_ SG_ 498 PT_High_T "Comp dis Temperature";
CM_ SG_ 498 PT_Low_T2 "Heating Mode Temperature";
CM_ SG_ 498 PT_Low_P2 "Heating Mode Pressure";
CM_ SG_ 498 PT_Low_P1 "Cooling Mode Pressure";
CM_ SG_ 498 PT_Low_T1 "Cooling Mode Temperature";
CM_ SG_ 498 Tamb "AMB Temperature";
CM_ SG_ 498 Bat_Out_Temp "Battery Out Water Temperature";
CM_ SG_ 498 Bat_In_Temp "Battery In Water Temperature";
CM_ SG_ 498 Motor_Out_Temp "Motor Out Water Temperature";
CM_ SG_ 498 Motor_In_Temp "Motor In Water Temperature";
CM_ SG_ 498 TWV_Err "Three way valve error";
CM_ SG_ 498 EWP3_Err "NO3 electrical water pump error";
CM_ SG_ 498 EWP2_Err "NO2 electrical water pump error";
CM_ SG_ 498 FWV_Err "Four way valve error";
CM_ SG_ 498 EWP1_Err "NO1 electrical water pump error";
CM_ SG_ 498 WPTC_Err "Water PTC error";
CM_ SG_ 498 Fan_Err "Cooling fan error";
CM_ SG_ 498 EXV2_Err "NO2 electronic expansion valve error";
CM_ SG_ 498 EXV1_Err "NO1 electronic expansion valve error";
CM_ SG_ 498 SOTXV_Err "Thermal expansion valve with solenoid valve function is error";
CM_ SG_ 498 COMP_Err "Compressor error";
CM_ SG_ 498 SOV3_Err "NO3 solenoid valve error";
CM_ SG_ 498 SOV2_Err "NO2 solenoid valve error";
CM_ SG_ 498 SOV1_Err "NO1 solenoid valve error";
CM_ SG_ 498 PT_High_Tact_Err "The temperature of temperature and high pressure sensor is error";
CM_ SG_ 498 PT_High_P_Err "The pressure of temperature and high pressure sensor is error";
CM_ SG_ 498 PT_Low_T2_Err "The temperature of NO2 temperature and low pressure sensor is error";
CM_ SG_ 498 PT_Low_P2_Err "The pressure of NO2 temperature and low pressure sensor is error";
CM_ SG_ 498 PT_Low_T1_Err "The temperature of NO1 temperature and low pressure sensor is error";
CM_ SG_ 498 PT_Low_P1_Err "The pressure of NO1 temperature and low pressure sensor is error";
CM_ SG_ 498 Motor_Out_Temp_Err "Driver motor outlet water temperature sensor error";
CM_ SG_ 498 Bat_Out_Temp_Err "High voltage battery outlet water temperature sensor error";
CM_ SG_ 498 Motor_In_Temp_Err "Driver motor inlet water temperature sensor error";
CM_ SG_ 498 Bat_In_Temp_Err "High voltage battery inlet water temperature sensor error";
CM_ SG_ 498 Tamb_Err "Ambient temperature sensor error";
CM_ SG_ 498 ZFR_SYS_MCURetryCnt_Sta "Zone FR MCU power output pin retry count";
CM_ SG_ 498 ZFR_SYS_BMSCCURetryCnt_Sta "Zone FR BMS_CCU power output pin retry count";
CM_ SG_ 498 ZFR_SYS_BSWSleepReq_Sta "Zone FR sleep request from BSW";
CM_ SG_ 498 ZFR_VCU_HWReset_Sta "Zone Fr VCU hardware reset state";
CM_ SG_ 498 ZFR_VCU_PwrSupply_Sta "Zone Fr VCU power supply state";
CM_ SG_ 547 FrntPTCSts "Front PTC Status signals";
CM_ SG_ 547 FrntPTCFltSt "Front PTC Fault Status";
CM_ SG_ 547 FrntPTCLVUnderUFlt "Front PTC Low Voltage Under Voltage Fault";
CM_ SG_ 547 FrntPTCLVOverUFlt "Front PTC Low Voltage Over Voltage Fault";
CM_ SG_ 547 FrntPTCHVUnderUFlt "Front PTC High Voltage Under Voltage Fault";
CM_ SG_ 547 FrntPTCHVOverUFlt "Frot PTC High Voltage Over Voltage Fault";
CM_ SG_ 547 FrntPTCLeOverAFlt "Front PTC Left Over Current Fault";
CM_ SG_ 547 FrntPTCRiOverAFlt "Front PTC Right Over Current Fault";
CM_ SG_ 547 FrntPTCLeCoreTSnsrFlt "Front PTC Left Core Temperature Sensor Fault";
CM_ SG_ 547 FrntPTCRiCoreTSnsrFlt "Frotn PTC Right Core Temperature Sensor Fault";
CM_ SG_ 547 FrntPTCLeCoreOverTFlt "Front PTC Left Core Over Remperature Fault";
CM_ SG_ 547 FrntPTCRiCoreOverTFlt "Front PTC Right Core Over Remperature Fault";
CM_ SG_ 547 FrntPTCLeIGBTShoCircFlt "Front PTC Left IGBT Short Circuit Fault";
CM_ SG_ 547 FrntPTCRiIGBTShoCircFlt "Front PTC Right IGBT Short Circuit Fault";
CM_ SG_ 547 FrntPTCLeOpentCircFlt "Front PTC Left Opent Circuit Fault";
CM_ SG_ 547 FrntPTCRiOpentCircFlt "Front PTC Right Opent Circuit Fault";
CM_ SG_ 547 FrntPTCPCBTSnsrFlt "Front PTC PCB Temperature Sensor Fault";
CM_ SG_ 547 FrntPTCPCBOverTFlt "Front PTC PCB Over Temperature Fault";
CM_ SG_ 547 FrntPTCComFlt "Front PTC Communication Fault";
CM_ SG_ 547 FrntPTCLeIGBTTSnsrFlt "Front PTC Left IGBT Temperature Sensor Fault";
CM_ SG_ 547 FrntPTCRiIGBTTSnsrFlt "Front PTC Right IGBT Temperature Sensor Fault";
CM_ SG_ 547 FrntPTCLeIGBTOverTFlt "Front PTC Left IGBT Over Temperature Fault";
CM_ SG_ 547 FrntPTCRiIGBTOverTFlt "Front PTC Right IGBT Over Temperature Fault";
CM_ SG_ 547 FrntPTCSWVers "Front PTC Software Version";
CM_ SG_ 547 FrntPTCHWVers "Front PTC Hardware Version";
CM_ SG_ 547 FrntPTCSupplierCod "Front PTC Supplier Code";
CM_ SG_ 547 FrntPTCRearLeOverAFlt "Frnt PTC Rear Left Over Current Fault";
CM_ SG_ 547 FrntPTCRearLeOpentCircFlt "Frnt PTC Rear Left Opent Circuit Fault";
CM_ SG_ 547 FrntPTCRearRiCoreOverTFlt "Frnt PTC Rear Right Core Over Remperature Fault";
CM_ SG_ 547 FrntPTCRearLeCoreOverTFlt "Frnt PTC Rear Left Core Over Remperature Fault";
CM_ SG_ 547 FrntPTCRearRiCoreTSnsrFlt "Frotn PTC Rear Right Core Temperature Sensor Fault";
CM_ SG_ 547 FrntPTCRearLeCoreTSnsrFlt "Frnt PTC Rear Left Core Temperature Sensor Fault";
CM_ SG_ 547 FrntPTCRearRiOverAFlt "Frnt PTC Rear Right Over Current Fault";
CM_ SG_ 547 FrntPTCRearRiOpentCircFlt "Frnt PTC Rear Right Opent Circuit Fault";
CM_ SG_ 547 FrntPTCRearRiIGBTShoCFlt "Frnt PTC Rear Right IGBT Short Circuit Fault";
CM_ SG_ 547 FrntPTCRearLeIGBTShoCFlt "Frnt PTC Rear Left IGBT Short Circuit Fault";
CM_ SG_ 547 FrntPTCRearLeBusLineC "Frnt PTC Rear Left  current";
CM_ SG_ 547 FrntPTCLeCoreT "Front PTC Left Core Temperature";
CM_ SG_ 547 FrntPTCRiCoreT "Front PTC Right Core Temperature";
CM_ SG_ 547 FrntPTCLeActHeatPwr "Front PTC Left Actual Heat Power";
CM_ SG_ 547 FrntPTCRiActHeatPwr "Front PTC Right Actual Heat Power";
CM_ SG_ 547 FrntPTCLeIGBTT "Front PTC Left IGBT Temperature";
CM_ SG_ 547 FrntPTCRiIGBTT "Front PTC Right IGBT Temperature";
CM_ SG_ 547 FrntPTCPCBT "Front PTC PCB Temperature";
CM_ SG_ 547 FrntPTCRearRiBusLineC "Frnt PTC Rear Right  current";
CM_ SG_ 547 FrntPTCRearLeActHeatPwr "Frnt PTC Rear Left Actual Heat Power 0x00-0xC8:actual value; 0xC9-0xFE:Reserved";
CM_ SG_ 547 FrntPTCRearLeCoreT "0x00~0xFE:Value 0xFF:Invalid";
CM_ SG_ 547 FrntPTCRearRiCoreT "Frnt PTC Rear Right Core Temperature 0x00~0xFE:Value";
CM_ BO_ 550 "Routing from LIN_DR1,2,3";
CM_ SG_ 550 RLS_LightSnrErr "LightSensorError";
CM_ SG_ 550 RLS_RainSnrErr "RainSensorError";
CM_ SG_ 550 RLS_Lamp_Sta "Lampstatus";
CM_ SG_ 550 RLS_RainSnrWiperCmd "RainSensorWiperCommand";
CM_ SG_ 550 CSW_TurnSw_Sta "CSW_TurnSw_Sta_CANbus (ZONE_DR BCM)";
CM_ SG_ 550 CSW_RWasSW_Sta "CSW_RWasherSW_Sta";
CM_ SG_ 550 CSW_FWasSw_Sta "CSW_FWasherSW_Sta";
CM_ SG_ 550 CSW_PassSW_Sta "CSW_PassSW_Sta";
CM_ SG_ 550 CSW_DimSw "CSW_DimSw";
CM_ SG_ 550 CSW_RWipIntSw_Sta "CSW_RWipSW_Sta";
CM_ SG_ 550 SWC_CANCEL_Sta "CANCEL Button Status";
CM_ SG_ 550 SWC_ACC_Sta "ACC Button Status";
CM_ SG_ 550 SWC_Distance_Sta "Distance Button Status";
CM_ SG_ 550 SWC_Down_Sta "DOWN Button Status";
CM_ SG_ 550 SWC_RegenUp "Regen Up";
CM_ SG_ 550 SWC_Left_Sta "Seek Backward track/radio";
CM_ SG_ 550 SWC_mode_Sta "Mode Button Status";
CM_ SG_ 550 SWC_Res_Up_Sta "Res up Button Status";
CM_ SG_ 550 SWC_RegenDown "Regen Down";
CM_ SG_ 550 SWC_Right_Sta "Seek Forward track/radio";
CM_ SG_ 550 SWC_Set_down_Sta "SET down Button Status";
CM_ SG_ 550 SWC_Trip_Sta "Trip Button Status";
CM_ SG_ 550 SWC_Up_Sta "UP Button Status";
CM_ SG_ 550 SWC_VR_Sta "VR Button Status";
CM_ SG_ 550 SWC_Undefined_Sta "Undefined button Status";
CM_ SG_ 550 SWC_LKA_Sta "LKA Button Status";
CM_ SG_ 550 L_Pas_Wdw_Obs_InhibitSts "Obstacle inhibit status";
CM_ SG_ 550 L_Drv_Wdw_RRD_Switch "Passager switch status of Rear Right window";
CM_ SG_ 550 L_Drv_Wdw_RLD_Switch "Passager switch status of Rear Left window";
CM_ SG_ 550 L_Pas_Wdw_OD_Sts "Obstacle detection status";
CM_ SG_ 550 L_Pas_Wdw_Init "ECU Initialization";
CM_ SG_ 550 L_Pas_OverHeat_Protect "OverHeat Protect";
CM_ SG_ 550 L_Pas_Motor_Relay_Error "Motor relay Error";
CM_ SG_ 550 L_Pas_Motor_Ripple_Error "Motor ripple Error";
CM_ SG_ 550 L_Drv_Wdw_Pas_Switch "Passager switch status of driver window";
CM_ SG_ 550 L_Pas_Val_Wdw_Opened "Window Opened Value";
CM_ SG_ 550 L_Pas_Wdw_PositionSts "Position status of passager window";
CM_ SG_ 550 L_Pas_Wdw_LocalSwitch "Local switch status of passager window";
CM_ SG_ 550 L_Pas_Wdw_Running_Sts "Running status of passager window";
CM_ SG_ 550 L_Power_Status "Power_Status";
CM_ SG_ 550 FAPWL_01_LIN_Response_Error "LIN Communication ERROR";
CM_ SG_ 550 L_Drv_Wdw_Obs_InhibitSts "Obstacle inhibit status";
CM_ SG_ 550 L_Drv_Wdw_OD_Sts "Obstacle detection status";
CM_ SG_ 550 L_Drv_Wdw_Init "ECU Initialization";
CM_ SG_ 550 L_Drv_OverHeat_Protect "OverHeat Protect";
CM_ SG_ 550 L_Drv_Motor_Relay_Error "Motor relay Error";
CM_ SG_ 550 L_Drv_Motor_Ripple_Error "Motor ripple Error";
CM_ SG_ 550 L_Drv_Val_Wdw_Opened "Window Opened Value";
CM_ SG_ 550 L_Drv_Wdw_PositionSts "Position status of driver window";
CM_ SG_ 550 L_Drv_Wdw_LocalSwitch "Local switch status of driver window";
CM_ SG_ 550 L_Drv_Wdw_Running_Sts "Running status of driver window";
CM_ SG_ 550 L_RLD_Wdw_Init "ECU Initialization";
CM_ SG_ 550 L_RRD_Val_Wdw_Opened "Window Opened Value";
CM_ SG_ 550 L_RRD_Wdw_PositionSts "Position status of Rear Right window";
CM_ SG_ 550 L_RRD_Wdw_Obs_InhibitSts "Obstacle inhibit status";
CM_ SG_ 550 L_RRD_Wdw_OD_Sts "Obstacle detection status";
CM_ SG_ 550 L_RRD_Wdw_Init "ECU Initialization";
CM_ SG_ 550 L_RRD_OverHeat_Protect "OverHeat Protect";
CM_ SG_ 550 L_RRD_Motor_Relay_Error "Motor relay Error";
CM_ SG_ 550 L_RRD_Motor_Ripple_Error "Motor ripple Error";
CM_ SG_ 550 L_RRD_Wdw_LocalSwitch "Local switch status of Rear Right window";
CM_ SG_ 550 L_RRD_Wdw_Running_Sts "Running status of Rear Right window";
CM_ SG_ 550 RAPWL_01_LIN_Response_Error "LIN Communication ERROR";
CM_ SG_ 550 L_RLD_Wdw_Obs_InhibitSts "Obstacle inhibit status";
CM_ SG_ 550 L_RLD_Wdw_OD_Sts "Obstacle detection status";
CM_ SG_ 550 L_RLD_Val_Wdw_Opened "Window Opened Value";
CM_ SG_ 550 L_RLD_OverHeat_Protect "OverHeat Protect";
CM_ SG_ 550 L_RLD_Motor_Relay_Error "Motor relay Error";
CM_ SG_ 550 L_RLD_Motor_Ripple_Error "Motor ripple Error";
CM_ SG_ 550 L_RLD_Wdw_PositionSts "Position status of Rear Left window";
CM_ SG_ 550 L_RLD_Wdw_LocalSwitch "Local switch status of Rear Left window";
CM_ SG_ 550 L_RLD_Wdw_Running_Sts "Running status of Rear Left window";
CM_ SG_ 550 SWC2_HW_Version "SWC gen2 HardwareVersionNumber, Min= 00h, Max= 270Fh, Undefined= 2710h - FFFFh";
CM_ SG_ 550 SWC2_SW_Version "SWC gen2 SoftwareVersionNumber, Min= 00h, Max= 270Fh, Undefined= 2710h - FFFFh";
CM_ SG_ 550 SWC2_R_Right_Sta "R Right Status SWC gen2";
CM_ SG_ 550 SWC2_R_ScrollUp_Sta "R Scroll Up Status SWC gen2";
CM_ SG_ 550 SWC2_R_ScrollPress_Sta "R Scroll Press Status SWC gen2";
CM_ SG_ 550 SWC2_R_ScrollDown_Sta "R Scroll Down Status SWC gen2";
CM_ SG_ 550 SWC2_R_Left_Sta "R Left Status SWC gen2";
CM_ SG_ 550 SWC2_R_VR_Sta "R VR Status SWC gen2";
CM_ SG_ 550 SWC2_R_PageSwitch_Sta "R PageSwitch Status SWC gen2";
CM_ SG_ 550 SWC2_R_Customize_Sta "R Customize Status SWC gen2";
CM_ SG_ 550 SWC2_L_Left_Sta "L Left Status SWC gen2";
CM_ SG_ 550 SWC2_L_ScrollUp_Sta "L Scroll Up Status SWC gen2";
CM_ SG_ 550 SWC2_L_ScrollPress_Sta "L Scroll press Status SWC gen2";
CM_ SG_ 550 SWC2_L_ScrollDown_Sta "L Scroll Down Status SWC gen2";
CM_ SG_ 550 SWC2_L_Right_Sta "L Right Status SWC gen2";
CM_ SG_ 550 SWC2_L_RegenUp_Sta "L Regen Up Status SWC gen2";
CM_ SG_ 550 SWC2_L_ADAS_Sta "L ADAS Status SWC gen2";
CM_ SG_ 550 SWC2_L_Home_Sta "L Home Status SWC gen2";
CM_ SG_ 550 SWC2_ResponseError "ResponseError SWC gen2";
CM_ SG_ 550 SWC2_R_RegenDown_Sta "R Regen Down Status SWC gen2";
CM_ SG_ 550 SWC2_L_DriveMode_Sta "L Drive Mode Status SWC gen2";
CM_ SG_ 805 HornSW "Horn Switch status";
CM_ SG_ 805 AllLockSta "All Door Lock";
CM_ SG_ 805 AutoLightSW "LightActivation";
CM_ SG_ 805 BrakeLampFail "BrakeLamp Failed";
CM_ SG_ 805 DrLockSta "Driver Side Door Lock Staus";
CM_ SG_ 805 WiperSWPos "WiperSwitchPosition";
CM_ SG_ 805 RRTurnLampC "Rear Right TurnLamp Current";
CM_ SG_ 805 RLTurnLampC "Rear Left TurnLamp Current";
CM_ SG_ 805 Wip_Speed "Wip_Speed";
CM_ SG_ 805 MIRROR_FOLD_SW "MIRROR_FOLD_SW";
CM_ SG_ 805 PsLockSta "Passenger Side Door Lock Status";
CM_ SG_ 805 RLLockSta "Rear Left Door Lock Status";
CM_ SG_ 805 RLS_Exist "RLS_Exist";
CM_ SG_ 805 RRLockSta "Rear Right Door Lock Status";
CM_ SG_ 805 RWiperAS "Rear Wiper AS";
CM_ SG_ 805 RWiperProtection "Rear Wiper Protection";
CM_ SG_ 805 WiperZeroPosSW "WiperZeroPositionSwitch";
CM_ SG_ 805 RLTurnLPErr "Rear Left Turn Lamp Err";
CM_ SG_ 805 RRTurnLPErr "Rear Right Turn Lamp Err";
CM_ SG_ 805 ZDR_THCM_IntakeFail_Sta "Intake Motor Fail Signal";
CM_ SG_ 805 ZDR_THCM_LINACT1_Sta "LIN ACT1 Fail Signal";
CM_ SG_ 805 ZDR_THCM_LINACT2_Sta "LIN ACT2 Fail Signal";
CM_ SG_ 805 ZDR_THCM_LINACT3_Sta "LIN ACT3 Fail Signal";
CM_ SG_ 805 ZDR_THCM_LINACT4_Sta "LIN ACT4 Fail Signal";
CM_ SG_ 805 ZDR_THCM_LINACT5_Sta "LIN ACT5 Fail Signal";
CM_ SG_ 805 ZDR_THCM_ModeFail_Sta "Mode Motor Fail Signal";
BA_DEF_ BO_  "GenMsgSendType" ENUM  "Cycle","NoMsgSendType","IfActive","Event","CA","CE";
BA_DEF_ BO_  "GenMsgNrOfRepetition" INT 0 0;
BA_DEF_ BO_  "GenMsgILSupport" ENUM  "No","Yes";
BA_DEF_ BO_  "GenMsgCycleTimeFast" INT 0 0;
BA_DEF_ BO_  "GenMsgCycleTime" INT 0 0;
BA_DEF_ BO_  "DiagResponse" ENUM  "No","Yes";
BA_DEF_ BO_  "DiagRequest" ENUM  "No","Yes";
BA_DEF_ BO_  "NmMessage" ENUM  "No","Yes";
BA_DEF_ BO_  "VFrameFormat" ENUM  "StandardCAN","ExtendedCAN","reserved","reserved","reserved","reserved","reserved","reserved","reserved","reserved","reserved","reserved","reserved","reserved","StandardCAN_FD","ExtendedCAN_FD";
BA_DEF_ BO_  "DataID" STRING ;
BA_DEF_ BO_  "DoIPLogicalAddress" STRING ;
BA_DEF_ BO_  "CANFD_BRS" ENUM  "0","1";
BA_DEF_ BO_  "GenMsgRequestable" INT 0 1;
BA_DEF_  "NmType" STRING ;
BA_DEF_  "VersionYear" INT 2010 2999;
BA_DEF_  "ProtocolType" STRING ;
BA_DEF_  "NmMessageCount" INT 0 255;
BA_DEF_  "NmBaseAddress" HEX 1280 1407;
BA_DEF_  "Manufacturer" STRING ;
BA_DEF_  "DBName" STRING ;
BA_DEF_  "BusType" STRING ;
BA_DEF_  "Baudrate" INT 0 1000000;
BA_DEF_  "Datarate" INT 0 2000000;
BA_DEF_  "NmAsrWaitBusSleepTime" INT 0 0;
BA_DEF_  "NmAsrTimeoutTime" INT 0 0;
BA_DEF_  "NmAsrRepeatMessageTime" INT 0 0;
BA_DEF_  "NmAsrMessageCount" INT 1 128;
BA_DEF_  "NmAsrCanMsgCycleTime" INT 0 0;
BA_DEF_  "NmAsrBaseAddress" HEX 0 536870911;
BA_DEF_ BU_  "NodeLayerModules" STRING ;
BA_DEF_ BU_  "ILUsed" ENUM  "No","Yes";
BA_DEF_ BU_  "NmCAN" INT 1 2;
BA_DEF_ BU_  "NmStationAddress" HEX 0 127;
BA_DEF_ BU_  "NmAsrNodeIdentifier" HEX 0 255;
BA_DEF_ BU_  "NmAsrCanMsgReducedTime" INT 0 0;
BA_DEF_ BU_  "CANFD_CANFD_Gateway" ENUM  "Yes","No";
BA_DEF_ BU_  "CAN_CANFD_Gateway" ENUM  "Yes","No";
BA_DEF_ BU_  "CANFD_LIN_Gateway" ENUM  "Yes","No";
BA_DEF_ BU_  "CAN_LIN_Gateway" ENUM  "Yes","No";
BA_DEF_ BU_  "CAN_CAN_Gateway" ENUM  "Yes","No";
BA_DEF_ BU_  "BootloaderNode" ENUM  "No","Yes";
BA_DEF_ SG_  "GenSigInvalidValue" HEX 0 0;
BA_DEF_ SG_  "GenSigStartValue" HEX 0 0;
BA_DEF_ SG_  "GenSigInactiveValue" HEX 0 0;
BA_DEF_ SG_  "GenSigRoutingTimeoutValue_String" STRING ;
BA_DEF_ SG_  "GenSigRoutingTimeoutValue" HEX 0 0;
BA_DEF_ SG_  "GenSigSendType" ENUM  "Cycle","OnWrite","OnWriteWithRepetition","OnChange","OnChangeWithRepetition","IfActive","IfActiveWithRepetition","NoSigSendType","vector_leerstring";
BA_DEF_ SG_  "SigType" ENUM  "Default","Range","RangeSigned","ASCII","Discrete","Control","ReferencePGN","DTC","StringDelimiter","StringLength","StringLengthControl","MessageCounter","MessageChecksum";
BA_DEF_ SG_  "GenSigILSupport" ENUM  "No","Yes";
BA_DEF_ SG_  "SystemSignalLongSymbol" STRING ;
BA_DEF_DEF_  "GenMsgSendType" "Cycle";
BA_DEF_DEF_  "GenMsgNrOfRepetition" 0;
BA_DEF_DEF_  "GenMsgILSupport" "Yes";
BA_DEF_DEF_  "GenMsgCycleTimeFast" 0;
BA_DEF_DEF_  "GenMsgCycleTime" 100;
BA_DEF_DEF_  "DiagResponse" "No";
BA_DEF_DEF_  "DiagRequest" "No";
BA_DEF_DEF_  "NmMessage" "No";
BA_DEF_DEF_  "VFrameFormat" "StandardCAN";
BA_DEF_DEF_  "DataID" "";
BA_DEF_DEF_  "DoIPLogicalAddress" "";
BA_DEF_DEF_  "CANFD_BRS" "1";
BA_DEF_DEF_  "GenMsgRequestable" 1;
BA_DEF_DEF_  "NmType" "AUTOSAR";
BA_DEF_DEF_  "VersionYear" 2024;
BA_DEF_DEF_  "ProtocolType" "CAN";
BA_DEF_DEF_  "NmMessageCount" 128;
BA_DEF_DEF_  "NmBaseAddress" 1280;
BA_DEF_DEF_  "Manufacturer" "";
BA_DEF_DEF_  "DBName" "";
BA_DEF_DEF_  "BusType" "";
BA_DEF_DEF_  "Baudrate" 500000;
BA_DEF_DEF_  "Datarate" 2000000;
BA_DEF_DEF_  "NmAsrWaitBusSleepTime" 1500;
BA_DEF_DEF_  "NmAsrTimeoutTime" 2000;
BA_DEF_DEF_  "NmAsrRepeatMessageTime" 3200;
BA_DEF_DEF_  "NmAsrMessageCount" 64;
BA_DEF_DEF_  "NmAsrCanMsgCycleTime" 640;
BA_DEF_DEF_  "NmAsrBaseAddress" 1024;
BA_DEF_DEF_  "NodeLayerModules" "CANoeILNLVector.dll";
BA_DEF_DEF_  "ILUsed" "Yes";
BA_DEF_DEF_  "NmCAN" 2;
BA_DEF_DEF_  "NmStationAddress" 0;
BA_DEF_DEF_  "NmAsrNodeIdentifier" 0;
BA_DEF_DEF_  "NmAsrCanMsgReducedTime" 6400;
BA_DEF_DEF_  "CANFD_CANFD_Gateway" "No";
BA_DEF_DEF_  "CAN_CANFD_Gateway" "No";
BA_DEF_DEF_  "CANFD_LIN_Gateway" "No";
BA_DEF_DEF_  "CAN_LIN_Gateway" "No";
BA_DEF_DEF_  "CAN_CAN_Gateway" "No";
BA_DEF_DEF_  "BootloaderNode" "No";
BA_DEF_DEF_  "GenSigInvalidValue" 0;
BA_DEF_DEF_  "GenSigStartValue" 0;
BA_DEF_DEF_  "GenSigInactiveValue" 0;
BA_DEF_DEF_  "GenSigRoutingTimeoutValue_String" "";
BA_DEF_DEF_  "GenSigRoutingTimeoutValue" 0;
BA_DEF_DEF_  "GenSigSendType" "Cycle";
BA_DEF_DEF_  "SigType" "Default";
BA_DEF_DEF_  "GenSigILSupport" "Yes";
BA_DEF_DEF_  "SystemSignalLongSymbol" "";
BA_ "Manufacturer" "FVT";
BA_ "NmAsrBaseAddress" 4132;
BA_ "ProtocolType" "CAN FD";
BA_ "BusType" "CAN FD";
BA_ "DBName" "CAN4";
BA_ "CANFD_LIN_Gateway" BU_ FUSION 0;
BA_ "CAN_CANFD_Gateway" BU_ FUSION 0;
BA_ "CANFD_CANFD_Gateway" BU_ FUSION 0;
BA_ "CAN_CAN_Gateway" BU_ FUSION 0;
BA_ "CANFD_LIN_Gateway" BU_ ZONE_FR 0;
BA_ "CAN_CANFD_Gateway" BU_ ZONE_FR 0;
BA_ "CANFD_CANFD_Gateway" BU_ ZONE_FR 0;
BA_ "BootloaderNode" BU_ ZONE_FR 1;
BA_ "CAN_LIN_Gateway" BU_ ZONE_DR 0;
BA_ "CANFD_LIN_Gateway" BU_ ZONE_DR 0;
BA_ "CAN_CANFD_Gateway" BU_ ZONE_DR 0;
BA_ "CANFD_CANFD_Gateway" BU_ ZONE_DR 0;
BA_ "BootloaderNode" BU_ ZONE_DR 1;
BA_ "BootloaderNode" BU_ D21_DKC 1;
BA_ "CAN_CANFD_Gateway" BU_ ZONE_FR_24 0;
BA_ "GenMsgSendType" BO_ 278 3;
BA_ "GenMsgCycleTimeFast" BO_ 278 10;
BA_ "DataID" BO_ 278 "0x4D08";
BA_ "GenMsgNrOfRepetition" BO_ 278 1;
BA_ "VFrameFormat" BO_ 278 14;
BA_ "GenMsgSendType" BO_ 386 5;
BA_ "GenMsgCycleTimeFast" BO_ 386 10;
BA_ "GenMsgNrOfRepetition" BO_ 386 1;
BA_ "VFrameFormat" BO_ 386 14;
BA_ "GenMsgSendType" BO_ 535 5;
BA_ "GenMsgCycleTimeFast" BO_ 535 10;
BA_ "GenMsgCycleTime" BO_ 535 200;
BA_ "GenMsgNrOfRepetition" BO_ 535 1;
BA_ "VFrameFormat" BO_ 535 14;
BA_ "GenMsgSendType" BO_ 595 5;
BA_ "GenMsgCycleTimeFast" BO_ 595 10;
BA_ "GenMsgNrOfRepetition" BO_ 595 1;
BA_ "VFrameFormat" BO_ 595 14;
BA_ "GenMsgSendType" BO_ 1080 5;
BA_ "GenMsgCycleTimeFast" BO_ 1080 20;
BA_ "GenMsgCycleTime" BO_ 1080 200;
BA_ "GenMsgNrOfRepetition" BO_ 1080 1;
BA_ "VFrameFormat" BO_ 1080 14;
BA_ "GenMsgSendType" BO_ 1280 3;
BA_ "NmMessage" BO_ 1280 1;
BA_ "GenMsgCycleTime" BO_ 1280 0;
BA_ "DoIPLogicalAddress" BO_ 1668 "0x0684";
BA_ "GenMsgSendType" BO_ 1668 3;
BA_ "DiagRequest" BO_ 1668 1;
BA_ "GenMsgCycleTime" BO_ 1668 0;
BA_ "VFrameFormat" BO_ 1668 14;
BA_ "DoIPLogicalAddress" BO_ 1669 "0x0685";
BA_ "GenMsgSendType" BO_ 1669 3;
BA_ "DiagRequest" BO_ 1669 1;
BA_ "GenMsgCycleTime" BO_ 1669 0;
BA_ "VFrameFormat" BO_ 1669 14;
BA_ "DoIPLogicalAddress" BO_ 1701 "0x06A5";
BA_ "GenMsgSendType" BO_ 1701 3;
BA_ "DiagRequest" BO_ 1701 1;
BA_ "GenMsgCycleTime" BO_ 1701 0;
BA_ "VFrameFormat" BO_ 1701 14;
BA_ "DoIPLogicalAddress" BO_ 1717 "0x06B5";
BA_ "GenMsgSendType" BO_ 1717 3;
BA_ "DiagRequest" BO_ 1717 1;
BA_ "GenMsgCycleTime" BO_ 1717 0;
BA_ "VFrameFormat" BO_ 1717 14;
BA_ "DoIPLogicalAddress" BO_ 1728 "0x06C0";
BA_ "GenMsgSendType" BO_ 1728 3;
BA_ "DiagRequest" BO_ 1728 1;
BA_ "GenMsgCycleTime" BO_ 1728 0;
BA_ "VFrameFormat" BO_ 1728 14;
BA_ "DoIPLogicalAddress" BO_ 1733 "0x06C5";
BA_ "GenMsgSendType" BO_ 1733 3;
BA_ "DiagRequest" BO_ 1733 1;
BA_ "GenMsgCycleTime" BO_ 1733 0;
BA_ "VFrameFormat" BO_ 1733 14;
BA_ "DoIPLogicalAddress" BO_ 2000 "0xEFFF";
BA_ "GenMsgSendType" BO_ 2000 3;
BA_ "DiagRequest" BO_ 2000 1;
BA_ "GenMsgCycleTime" BO_ 2000 0;
BA_ "VFrameFormat" BO_ 2000 14;
BA_ "GenMsgCycleTime" BO_ 1174 1000;
BA_ "GenMsgNrOfRepetition" BO_ 1174 1;
BA_ "VFrameFormat" BO_ 1174 14;
BA_ "GenMsgSendType" BO_ 497 5;
BA_ "GenMsgCycleTimeFast" BO_ 497 5;
BA_ "GenMsgCycleTime" BO_ 497 20;
BA_ "GenMsgNrOfRepetition" BO_ 497 1;
BA_ "VFrameFormat" BO_ 497 14;
BA_ "GenMsgSendType" BO_ 498 5;
BA_ "GenMsgCycleTimeFast" BO_ 498 5;
BA_ "GenMsgCycleTime" BO_ 498 20;
BA_ "GenMsgNrOfRepetition" BO_ 498 1;
BA_ "VFrameFormat" BO_ 498 14;
BA_ "GenMsgCycleTimeFast" BO_ 547 50;
BA_ "GenMsgNrOfRepetition" BO_ 547 1;
BA_ "VFrameFormat" BO_ 547 14;
BA_ "GenMsgSendType" BO_ 550 5;
BA_ "GenMsgCycleTimeFast" BO_ 550 50;
BA_ "GenMsgCycleTime" BO_ 550 200;
BA_ "GenMsgNrOfRepetition" BO_ 550 1;
BA_ "VFrameFormat" BO_ 550 14;
BA_ "GenMsgSendType" BO_ 805 5;
BA_ "GenMsgCycleTimeFast" BO_ 805 50;
BA_ "GenMsgNrOfRepetition" BO_ 805 1;
BA_ "VFrameFormat" BO_ 805 14;
BA_ "GenSigSendType" SG_ 278 CS_VCU1_CAN4 1;
BA_ "GenSigSendType" SG_ 278 RC_VCU1_CAN4 1;
BA_ "GenSigSendType" SG_ 278 Dr_SeatSta 1;
BA_ "GenSigRoutingTimeoutValue" SG_ 278 Dr_SeatSta 2;
BA_ "GenSigInactiveValue" SG_ 278 Dr_SeatSta 2;
BA_ "GenSigRoutingTimeoutValue_String" SG_ 278 Dr_SeatSta "0x2";
BA_ "GenSigStartValue" SG_ 278 Dr_SeatSta 2;
BA_ "GenSigInvalidValue" SG_ 278 Dr_SeatSta 2;
BA_ "GenSigSendType" SG_ 278 MSA_Crl_Sta 1;
BA_ "GenSigRoutingTimeoutValue" SG_ 278 MSA_Crl_Sta 6;
BA_ "GenSigInactiveValue" SG_ 278 MSA_Crl_Sta 6;
BA_ "GenSigRoutingTimeoutValue_String" SG_ 278 MSA_Crl_Sta "0x6";
BA_ "GenSigInvalidValue" SG_ 278 MSA_Crl_Sta 6;
BA_ "GenSigSendType" SG_ 278 CC_Crl_Sta 1;
BA_ "GenSigInvalidValue" SG_ 278 CC_Crl_Sta 6;
BA_ "GenSigSendType" SG_ 278 ShiftGearPosn 1;
BA_ "GenSigRoutingTimeoutValue" SG_ 278 ShiftGearPosn 1;
BA_ "GenSigInactiveValue" SG_ 278 ShiftGearPosn 1;
BA_ "GenSigRoutingTimeoutValue_String" SG_ 278 ShiftGearPosn "0x1";
BA_ "GenSigStartValue" SG_ 278 ShiftGearPosn 1;
BA_ "GenSigInvalidValue" SG_ 278 ShiftGearPosn 1;
BA_ "GenSigSendType" SG_ 278 PwrSta 1;
BA_ "GenSigRoutingTimeoutValue" SG_ 278 PwrSta 7;
BA_ "GenSigInactiveValue" SG_ 278 PwrSta 7;
BA_ "GenSigRoutingTimeoutValue_String" SG_ 278 PwrSta "0x7";
BA_ "GenSigStartValue" SG_ 278 PwrSta 7;
BA_ "GenSigInvalidValue" SG_ 278 PwrSta 7;
BA_ "GenSigSendType" SG_ 278 ReBrakeLPReq 1;
BA_ "GenSigSendType" SG_ 278 DKCTimeSN 1;
BA_ "GenSigSendType" SG_ 278 TimeSNDKCFbk 1;
BA_ "GenSigSendType" SG_ 278 EquivAccPedalSWSta 1;
BA_ "GenSigSendType" SG_ 278 HornCtrl 1;
BA_ "GenSigSendType" SG_ 278 BCM_DoorLock_Sta 1;
BA_ "GenSigRoutingTimeoutValue_String" SG_ 278 BCM_DoorLock_Sta "0x0";
BA_ "GenSigSendType" SG_ 278 DimmerEN 1;
BA_ "GenSigSendType" SG_ 278 RoomLampH 1;
BA_ "GenSigSendType" SG_ 278 RoomLampL 1;
BA_ "GenSigSendType" SG_ 278 TailgateRemote 1;
BA_ "GenSigSendType" SG_ 278 Dimmer 1;
BA_ "GenSigRoutingTimeoutValue" SG_ 278 Dimmer 127;
BA_ "GenSigRoutingTimeoutValue_String" SG_ 278 Dimmer "0x7F";
BA_ "GenSigInvalidValue" SG_ 278 Dimmer 127;
BA_ "GenSigSendType" SG_ 278 LockSetting 1;
BA_ "GenSigSendType" SG_ 278 L_APM_WdwEnable 1;
BA_ "GenSigSendType" SG_ 278 CrashDetd 1;
BA_ "GenSigSendType" SG_ 278 AntiTheftSeatFold 1;
BA_ "GenSigRoutingTimeoutValue_String" SG_ 278 AntiTheftSeatFold "0x0";
BA_ "GenSigSendType" SG_ 278 AntitheftSta 1;
BA_ "GenSigRoutingTimeoutValue_String" SG_ 278 AntitheftSta "0x0";
BA_ "GenSigSendType" SG_ 278 RTurnLP 1;
BA_ "GenSigSendType" SG_ 278 LTurnLP 1;
BA_ "GenSigSendType" SG_ 278 HazardSW 1;
BA_ "GenSigSendType" SG_ 278 Rr_FogLamp 1;
BA_ "GenSigSendType" SG_ 278 Fr_FogLamp 1;
BA_ "GenSigSendType" SG_ 278 RBSD 1;
BA_ "GenSigSendType" SG_ 278 LBSD 1;
BA_ "GenSigSendType" SG_ 278 BrakeLamp 1;
BA_ "GenSigSendType" SG_ 278 ReverseLamp 1;
BA_ "GenSigSendType" SG_ 278 RDRL 1;
BA_ "GenSigSendType" SG_ 278 LDRL 1;
BA_ "GenSigSendType" SG_ 278 PosLamp 1;
BA_ "GenSigSendType" SG_ 278 H_Beam 1;
BA_ "GenSigSendType" SG_ 278 L_Beam 1;
BA_ "GenSigSendType" SG_ 278 WasherCtrl 1;
BA_ "GenSigSendType" SG_ 278 WiperFixMode 1;
BA_ "GenSigSendType" SG_ 278 Rr_Wiper 1;
BA_ "GenSigSendType" SG_ 278 Fr_Wiper_L 1;
BA_ "GenSigSendType" SG_ 278 Fr_Wiper_H 1;
BA_ "GenSigSendType" SG_ 278 MirrorCtrl 1;
BA_ "GenSigSendType" SG_ 278 TailgateHDSW 1;
BA_ "GenSigSendType" SG_ 278 TrunkRel 1;
BA_ "GenSigSendType" SG_ 278 Rr_Defog 1;
BA_ "GenSigSendType" SG_ 278 Fr_ChargingDoorCtrl 1;
BA_ "GenSigSendType" SG_ 278 HoodSW 1;
BA_ "GenSigSendType" SG_ 278 DoorLockIND 1;
BA_ "GenSigSendType" SG_ 278 AllDoorSW 1;
BA_ "GenSigSendType" SG_ 278 RRDoorSW 1;
BA_ "GenSigSendType" SG_ 278 RLDoorSW 1;
BA_ "GenSigSendType" SG_ 278 PsDoorSW 1;
BA_ "GenSigSendType" SG_ 278 Rr_ChargingDoorCtrl 1;
BA_ "GenSigSendType" SG_ 278 CTDCtrl 1;
BA_ "GenSigSendType" SG_ 278 FD_TBOX_VehData_Sta 1;
BA_ "GenSigSendType" SG_ 278 FD_TBOX_VehData_Err 1;
BA_ "GenSigSendType" SG_ 278 FD_DKC_VehData_Sta 1;
BA_ "GenSigSendType" SG_ 278 FD_DKC_VehData_Err 1;
BA_ "GenSigSendType" SG_ 278 FD_TBOX_DTCData_Sta 1;
BA_ "GenSigSendType" SG_ 278 FD_TBOX_DTCData_Err 1;
BA_ "GenSigSendType" SG_ 278 LampPwr 1;
BA_ "GenSigSendType" SG_ 278 DKCAuthSta 1;
BA_ "GenSigRoutingTimeoutValue" SG_ 278 DKCAuthSta 3;
BA_ "GenSigRoutingTimeoutValue_String" SG_ 278 DKCAuthSta "0x3";
BA_ "GenSigInvalidValue" SG_ 278 DKCAuthSta 3;
BA_ "GenSigSendType" SG_ 278 MirrorDefog 1;
BA_ "GenSigSendType" SG_ 278 DrDoorSW 1;
BA_ "GenSigRoutingTimeoutValue_String" SG_ 278 DrDoorSW "0x0";
BA_ "GenSigSendType" SG_ 278 CTDLockSW 1;
BA_ "GenSigSendType" SG_ 278 CTDUnlockSW 1;
BA_ "GenSigSendType" SG_ 278 Tailgate_SW 1;
BA_ "GenSigSendType" SG_ 278 HWResetSta 1;
BA_ "GenSigSendType" SG_ 278 CtrlFrBMSCCUCIR 1;
BA_ "GenSigSendType" SG_ 278 CtrlFrEDUINVERTER 1;
BA_ "GenSigSendType" SG_ 278 CtrlFrIRC1 1;
BA_ "GenSigSendType" SG_ 278 CtrlFrPwrStbA1P 1;
BA_ "GenSigSendType" SG_ 278 CtrlDrPwrStbA2 1;
BA_ "GenSigSendType" SG_ 278 H_Beam_ADB 1;
BA_ "GenSigSendType" SG_ 278 APS_Sta_System 1;
BA_ "GenSigStartValue" SG_ 386 Fr_Coolanttemp 40;
BA_ "GenSigRoutingTimeoutValue" SG_ 386 FD_RecyAuto_Cmd 7;
BA_ "GenSigInactiveValue" SG_ 386 FD_RecyAuto_Cmd 7;
BA_ "GenSigRoutingTimeoutValue_String" SG_ 386 FD_RecyAuto_Cmd "0x7";
BA_ "GenSigStartValue" SG_ 386 FD_RecyAuto_Cmd 7;
BA_ "GenSigInvalidValue" SG_ 386 FD_RecyAuto_Cmd 7;
BA_ "GenSigRoutingTimeoutValue" SG_ 386 CabinMode 15;
BA_ "GenSigInactiveValue" SG_ 386 CabinMode 15;
BA_ "GenSigRoutingTimeoutValue_String" SG_ 386 CabinMode "0xF";
BA_ "GenSigStartValue" SG_ 386 CabinMode 15;
BA_ "GenSigInvalidValue" SG_ 386 CabinMode 15;
BA_ "GenSigStartValue" SG_ 386 Rr_Coolanttemp 40;
BA_ "GenSigSendType" SG_ 386 FD_Blower_Cmd 3;
BA_ "GenSigSendType" SG_ 386 FD_Comp_Cmd 3;
BA_ "GenSigSendType" SG_ 386 FD_FrRiAPTCHeatPwr_Cmd 3;
BA_ "GenSigInvalidValue" SG_ 386 FD_FrRiAPTCHeatPwr_Cmd 255;
BA_ "GenSigSendType" SG_ 386 FD_FrLeAPTCHeatPwr_Cmd 3;
BA_ "GenSigInvalidValue" SG_ 386 FD_FrLeAPTCHeatPwr_Cmd 255;
BA_ "GenSigSendType" SG_ 386 FD_RrAPTCHeatPwr_Cmd 3;
BA_ "GenSigSendType" SG_ 386 FD_FrWPTCHeatPwr_Cmd 3;
BA_ "GenSigInvalidValue" SG_ 386 FD_FrWPTCHeatPwr_Cmd 255;
BA_ "GenSigInvalidValue" SG_ 386 FD_EWP3_Cmd 255;
BA_ "GenSigInvalidValue" SG_ 386 FD_EWP2_Cmd 255;
BA_ "GenSigInvalidValue" SG_ 386 FD_EWP1_Cmd 255;
BA_ "GenSigSendType" SG_ 386 APTC_ActFrRiPwr 3;
BA_ "GenSigSendType" SG_ 386 CoolgFanActDuty 3;
BA_ "GenSigRoutingTimeoutValue" SG_ 386 sigWindDirZon1St 7;
BA_ "GenSigInactiveValue" SG_ 386 sigWindDirZon1St 7;
BA_ "GenSigRoutingTimeoutValue_String" SG_ 386 sigWindDirZon1St "0x7";
BA_ "GenSigStartValue" SG_ 386 sigWindDirZon1St 7;
BA_ "GenSigInvalidValue" SG_ 386 sigWindDirZon1St 7;
BA_ "GenSigRoutingTimeoutValue" SG_ 386 sigWindDirZon3St 7;
BA_ "GenSigInactiveValue" SG_ 386 sigWindDirZon3St 7;
BA_ "GenSigRoutingTimeoutValue_String" SG_ 386 sigWindDirZon3St "0x7";
BA_ "GenSigStartValue" SG_ 386 sigWindDirZon3St 7;
BA_ "GenSigInvalidValue" SG_ 386 sigWindDirZon3St 7;
BA_ "GenSigRoutingTimeoutValue" SG_ 386 FDC_THCM_CLEVentY_Sta 127;
BA_ "GenSigRoutingTimeoutValue_String" SG_ 386 FDC_THCM_CLEVentY_Sta "0x7F";
BA_ "GenSigInvalidValue" SG_ 386 FDC_THCM_CLEVentY_Sta 127;
BA_ "GenSigRoutingTimeoutValue" SG_ 386 sigAirIntenZon1St 15;
BA_ "GenSigRoutingTimeoutValue_String" SG_ 386 sigAirIntenZon1St "0xF";
BA_ "GenSigInvalidValue" SG_ 386 sigAirIntenZon1St 15;
BA_ "GenSigRoutingTimeoutValue" SG_ 386 sigAirIntenZon3St 15;
BA_ "GenSigRoutingTimeoutValue_String" SG_ 386 sigAirIntenZon3St "0xF";
BA_ "GenSigInvalidValue" SG_ 386 sigAirIntenZon3St 15;
BA_ "GenSigInvalidValue" SG_ 386 sigAmbAirT 255;
BA_ "GenSigStartValue" SG_ 386 sigCbnSolarLeft 253;
BA_ "GenSigStartValue" SG_ 386 sigCbnSolarRight 253;
BA_ "GenSigStartValue" SG_ 386 sigClntTHvBattOut 120;
BA_ "GenSigRoutingTimeoutValue" SG_ 386 FDC_THCM_CLEVentZ_Sta 127;
BA_ "GenSigRoutingTimeoutValue_String" SG_ 386 FDC_THCM_CLEVentZ_Sta "0x7F";
BA_ "GenSigInvalidValue" SG_ 386 FDC_THCM_CLEVentZ_Sta 127;
BA_ "GenSigSendType" SG_ 386 FDC_THCM_CLVent_Sta 3;
BA_ "GenSigRoutingTimeoutValue" SG_ 386 FDC_THCM_CREVentY_Sta 127;
BA_ "GenSigRoutingTimeoutValue_String" SG_ 386 FDC_THCM_CREVentY_Sta "0x7F";
BA_ "GenSigInvalidValue" SG_ 386 FDC_THCM_CREVentY_Sta 127;
BA_ "GenSigRoutingTimeoutValue" SG_ 386 FDC_THCM_CREVentZ_Sta 127;
BA_ "GenSigRoutingTimeoutValue_String" SG_ 386 FDC_THCM_CREVentZ_Sta "0x7F";
BA_ "GenSigInvalidValue" SG_ 386 FDC_THCM_CREVentZ_Sta 127;
BA_ "GenSigSendType" SG_ 386 FDC_THCM_CRVent_Sta 3;
BA_ "GenSigSendType" SG_ 386 FDC_THCM_DrEVentMode_Sta 3;
BA_ "GenSigRoutingTimeoutValue_String" SG_ 386 FDC_THCM_DrEVentMode_Sta "0x0";
BA_ "GenSigRoutingTimeoutValue" SG_ 386 FDC_THCM_DrEVentY_Sta 127;
BA_ "GenSigRoutingTimeoutValue_String" SG_ 386 FDC_THCM_DrEVentY_Sta "0x7F";
BA_ "GenSigInvalidValue" SG_ 386 FDC_THCM_DrEVentY_Sta 127;
BA_ "GenSigRoutingTimeoutValue" SG_ 386 FDC_THCM_DrEVentZ_Sta 127;
BA_ "GenSigRoutingTimeoutValue_String" SG_ 386 FDC_THCM_DrEVentZ_Sta "0x7F";
BA_ "GenSigInvalidValue" SG_ 386 FDC_THCM_DrEVentZ_Sta 127;
BA_ "GenSigSendType" SG_ 386 FDC_THCM_DrVent_Sta 3;
BA_ "GenSigSendType" SG_ 386 FDC_THCM_PsEVentMode_Sta 3;
BA_ "GenSigRoutingTimeoutValue_String" SG_ 386 FDC_THCM_PsEVentMode_Sta "0x0";
BA_ "GenSigRoutingTimeoutValue" SG_ 386 FDC_THCM_PsEVentY_Sta 127;
BA_ "GenSigRoutingTimeoutValue_String" SG_ 386 FDC_THCM_PsEVentY_Sta "0x7F";
BA_ "GenSigInvalidValue" SG_ 386 FDC_THCM_PsEVentY_Sta 127;
BA_ "GenSigRoutingTimeoutValue" SG_ 386 FDC_THCM_PsEVentZ_Sta 127;
BA_ "GenSigRoutingTimeoutValue_String" SG_ 386 FDC_THCM_PsEVentZ_Sta "0x7F";
BA_ "GenSigInvalidValue" SG_ 386 FDC_THCM_PsEVentZ_Sta 127;
BA_ "GenSigSendType" SG_ 386 FDC_THCM_PsVent_Sta 3;
BA_ "GenSigSendType" SG_ 535 FDLHandleLampCmd 3;
BA_ "GenSigSendType" SG_ 535 FDRHandleLampCmd 3;
BA_ "GenSigSendType" SG_ 535 AmbLightColor1 3;
BA_ "GenSigSendType" SG_ 535 BCM_Buzzer_Req 3;
BA_ "GenSigRoutingTimeoutValue_String" SG_ 535 BCM_Buzzer_Req "0x0";
BA_ "GenSigSendType" SG_ 535 AmbLightColor2 3;
BA_ "GenSigSendType" SG_ 535 AmbLightColor3 3;
BA_ "GenSigSendType" SG_ 535 FDHandleCmd 3;
BA_ "GenSigSendType" SG_ 535 AmbLightColor4 3;
BA_ "GenSigSendType" SG_ 535 AmbLightColor5 3;
BA_ "GenSigSendType" SG_ 535 AmbLightColor6 3;
BA_ "GenSigSendType" SG_ 535 AmbLightBrightness1 3;
BA_ "GenSigRoutingTimeoutValue" SG_ 535 AmbLightBrightness1 127;
BA_ "GenSigRoutingTimeoutValue_String" SG_ 535 AmbLightBrightness1 "0x7F";
BA_ "GenSigInvalidValue" SG_ 535 AmbLightBrightness1 127;
BA_ "GenSigSendType" SG_ 535 AmbLightBrightness2 3;
BA_ "GenSigRoutingTimeoutValue" SG_ 535 AmbLightBrightness2 127;
BA_ "GenSigRoutingTimeoutValue_String" SG_ 535 AmbLightBrightness2 "0x7F";
BA_ "GenSigInvalidValue" SG_ 535 AmbLightBrightness2 127;
BA_ "GenSigSendType" SG_ 535 AmbLightBrightness3 3;
BA_ "GenSigRoutingTimeoutValue" SG_ 535 AmbLightBrightness3 127;
BA_ "GenSigRoutingTimeoutValue_String" SG_ 535 AmbLightBrightness3 "0x7F";
BA_ "GenSigInvalidValue" SG_ 535 AmbLightBrightness3 127;
BA_ "GenSigSendType" SG_ 535 AmbLightBrightness4 3;
BA_ "GenSigRoutingTimeoutValue" SG_ 535 AmbLightBrightness4 127;
BA_ "GenSigRoutingTimeoutValue_String" SG_ 535 AmbLightBrightness4 "0x7F";
BA_ "GenSigInvalidValue" SG_ 535 AmbLightBrightness4 127;
BA_ "GenSigSendType" SG_ 535 AmbLightBrightness5 3;
BA_ "GenSigRoutingTimeoutValue" SG_ 535 AmbLightBrightness5 127;
BA_ "GenSigRoutingTimeoutValue_String" SG_ 535 AmbLightBrightness5 "0x7F";
BA_ "GenSigInvalidValue" SG_ 535 AmbLightBrightness5 127;
BA_ "GenSigSendType" SG_ 535 AmbLightBrightness6 3;
BA_ "GenSigRoutingTimeoutValue" SG_ 535 AmbLightBrightness6 127;
BA_ "GenSigRoutingTimeoutValue_String" SG_ 535 AmbLightBrightness6 "0x7F";
BA_ "GenSigInvalidValue" SG_ 535 AmbLightBrightness6 127;
BA_ "GenSigSendType" SG_ 535 AmbLightBreath1 3;
BA_ "GenSigSendType" SG_ 535 AmbLightBreath2 3;
BA_ "GenSigSendType" SG_ 535 AmbLightBreath3 3;
BA_ "GenSigSendType" SG_ 535 AmbLightBreath4 3;
BA_ "GenSigSendType" SG_ 535 AmbLightBreath5 3;
BA_ "GenSigSendType" SG_ 535 AmbLightBreath6 3;
BA_ "GenSigSendType" SG_ 535 WelcomeLight 3;
BA_ "GenSigSendType" SG_ 535 FDC_BCM_TurnSwTSetSta_Sta 3;
BA_ "GenSigRoutingTimeoutValue" SG_ 535 FDC_BCM_TurnSwTSetSta_Sta 3;
BA_ "GenSigInactiveValue" SG_ 535 FDC_BCM_TurnSwTSetSta_Sta 3;
BA_ "GenSigRoutingTimeoutValue_String" SG_ 535 FDC_BCM_TurnSwTSetSta_Sta "0x3";
BA_ "GenSigStartValue" SG_ 535 FDC_BCM_TurnSwTSetSta_Sta 3;
BA_ "GenSigInvalidValue" SG_ 535 FDC_BCM_TurnSwTSetSta_Sta 3;
BA_ "GenSigSendType" SG_ 535 FDC_BCM_UserHeightSet_Sta 3;
BA_ "GenSigRoutingTimeoutValue" SG_ 535 FDC_BCM_UserHeightSet_Sta 1023;
BA_ "GenSigInactiveValue" SG_ 535 FDC_BCM_UserHeightSet_Sta 1023;
BA_ "GenSigRoutingTimeoutValue_String" SG_ 535 FDC_BCM_UserHeightSet_Sta "0x3FF";
BA_ "GenSigStartValue" SG_ 535 FDC_BCM_UserHeightSet_Sta 1023;
BA_ "GenSigInvalidValue" SG_ 535 FDC_BCM_UserHeightSet_Sta 1023;
BA_ "GenSigSendType" SG_ 535 FDC_BCM_UserNow_Sta 3;
BA_ "GenSigSendType" SG_ 535 FDC_DKC_CommandToBCM_Cmd 3;
BA_ "GenSigRoutingTimeoutValue" SG_ 535 FDC_DKC_CommandToBCM_Cmd 15;
BA_ "GenSigInactiveValue" SG_ 535 FDC_DKC_CommandToBCM_Cmd 15;
BA_ "GenSigRoutingTimeoutValue_String" SG_ 535 FDC_DKC_CommandToBCM_Cmd "0xF";
BA_ "GenSigStartValue" SG_ 535 FDC_DKC_CommandToBCM_Cmd 15;
BA_ "GenSigInvalidValue" SG_ 535 FDC_DKC_CommandToBCM_Cmd 15;
BA_ "GenSigSendType" SG_ 535 FDC_DKC_DKeyAreaPE_Sta 3;
BA_ "GenSigSendType" SG_ 535 FDC_BCM_PTGOpenHeight_Sta 3;
BA_ "GenSigRoutingTimeoutValue" SG_ 535 FDC_BCM_PTGOpenHeight_Sta 7;
BA_ "GenSigInactiveValue" SG_ 535 FDC_BCM_PTGOpenHeight_Sta 7;
BA_ "GenSigRoutingTimeoutValue_String" SG_ 535 FDC_BCM_PTGOpenHeight_Sta "0x7";
BA_ "GenSigStartValue" SG_ 535 FDC_BCM_PTGOpenHeight_Sta 7;
BA_ "GenSigInvalidValue" SG_ 535 FDC_BCM_PTGOpenHeight_Sta 7;
BA_ "GenSigSendType" SG_ 535 FDC_BCM_ATCtrl_Cmd 3;
BA_ "GenSigSendType" SG_ 535 FDC_BCM_LockAlarm_Cmd 3;
BA_ "GenSigSendType" SG_ 535 FDC_BCM_FWipSw_Sta 3;
BA_ "GenSigRoutingTimeoutValue" SG_ 535 FDC_BCM_FWipSw_Sta 7;
BA_ "GenSigInactiveValue" SG_ 535 FDC_BCM_FWipSw_Sta 7;
BA_ "GenSigRoutingTimeoutValue_String" SG_ 535 FDC_BCM_FWipSw_Sta "0x7";
BA_ "GenSigStartValue" SG_ 535 FDC_BCM_FWipSw_Sta 7;
BA_ "GenSigInvalidValue" SG_ 535 FDC_BCM_FWipSw_Sta 7;
BA_ "GenSigSendType" SG_ 535 FDC_BCM_TurnSw_Sta 3;
BA_ "GenSigRoutingTimeoutValue" SG_ 535 FDC_BCM_TurnSw_Sta 3;
BA_ "GenSigInactiveValue" SG_ 535 FDC_BCM_TurnSw_Sta 3;
BA_ "GenSigRoutingTimeoutValue_String" SG_ 535 FDC_BCM_TurnSw_Sta "0x3";
BA_ "GenSigStartValue" SG_ 535 FDC_BCM_TurnSw_Sta 3;
BA_ "GenSigInvalidValue" SG_ 535 FDC_BCM_TurnSw_Sta 3;
BA_ "GenSigSendType" SG_ 535 FDC_BCM_FWasSw_Sta 3;
BA_ "GenSigRoutingTimeoutValue" SG_ 535 FDC_BCM_FWasSw_Sta 3;
BA_ "GenSigInactiveValue" SG_ 535 FDC_BCM_FWasSw_Sta 3;
BA_ "GenSigRoutingTimeoutValue_String" SG_ 535 FDC_BCM_FWasSw_Sta "0x3";
BA_ "GenSigStartValue" SG_ 535 FDC_BCM_FWasSw_Sta 3;
BA_ "GenSigInvalidValue" SG_ 535 FDC_BCM_FWasSw_Sta 3;
BA_ "GenSigSendType" SG_ 535 FDC_BCM_PassSW_Sta 3;
BA_ "GenSigSendType" SG_ 535 FDC_BCM_DimSw 3;
BA_ "GenSigSendType" SG_ 535 FDC_THCM_ACTInitial_Cmd 3;
BA_ "GenSigSendType" SG_ 535 FDC_DKC_SPTGDet_Cmd 3;
BA_ "GenSigSendType" SG_ 535 FDC_DKC_SPTGOpen_Cmd 3;
BA_ "GenSigSendType" SG_ 535 FDC_BCM_HazardIND_Cmd 3;
BA_ "GenSigRoutingTimeoutValue_String" SG_ 535 FDC_BCM_HazardIND_Cmd "0x0";
BA_ "GenSigSendType" SG_ 535 FDC_THCM_AirIntZ3_Sta 3;
BA_ "GenSigRoutingTimeoutValue_String" SG_ 535 FDC_BCM_OutMode_Cmd "0x0";
BA_ "GenSigSendType" SG_ 535 FDC_EChrg_SW_Sta 3;
BA_ "GenSigRoutingTimeoutValue" SG_ 535 FDC_EChrg_SW_Sta 2;
BA_ "GenSigRoutingTimeoutValue_String" SG_ 535 FDC_EChrg_SW_Sta "0x2";
BA_ "GenSigInvalidValue" SG_ 535 FDC_EChrg_SW_Sta 2;
BA_ "GenSigSendType" SG_ 595 IVI_Located_STA 3;
BA_ "GenSigRoutingTimeoutValue" SG_ 595 IVI_Located_STA 3;
BA_ "GenSigInactiveValue" SG_ 595 IVI_Located_STA 3;
BA_ "GenSigRoutingTimeoutValue_String" SG_ 595 IVI_Located_STA "0x3";
BA_ "GenSigStartValue" SG_ 595 IVI_Located_STA 3;
BA_ "GenSigInvalidValue" SG_ 595 IVI_Located_STA 3;
BA_ "GenSigSendType" SG_ 595 Approach_Unlock_SW 3;
BA_ "GenSigRoutingTimeoutValue_String" SG_ 595 Approach_Unlock_SW "0x0";
BA_ "GenSigSendType" SG_ 595 Walkaway_Lock_SW 3;
BA_ "GenSigRoutingTimeoutValue_String" SG_ 595 Walkaway_Lock_SW "0x0";
BA_ "GenSigStartValue" SG_ 595 Walkaway_Lock_SW 1;
BA_ "GenSigSendType" SG_ 595 BrkSw_Sta 3;
BA_ "GenSigRoutingTimeoutValue_String" SG_ 595 BrkSw_Sta "0x0";
BA_ "GenSigSendType" SG_ 595 DSEAT_anti_set 3;
BA_ "GenSigRoutingTimeoutValue_String" SG_ 595 DSEAT_anti_set "0x0";
BA_ "GenSigSendType" SG_ 595 DSEAT_entryfun_set 3;
BA_ "GenSigRoutingTimeoutValue_String" SG_ 595 DSEAT_entryfun_set "0x0";
BA_ "GenSigSendType" SG_ 595 IVI_PTG_Mode_SW 3;
BA_ "GenSigRoutingTimeoutValue" SG_ 595 IVI_PTG_Mode_SW 2;
BA_ "GenSigRoutingTimeoutValue_String" SG_ 595 IVI_PTG_Mode_SW "0x2";
BA_ "GenSigInvalidValue" SG_ 595 IVI_PTG_Mode_SW 2;
BA_ "GenSigSendType" SG_ 595 PSEAT_vent_req 3;
BA_ "GenSigRoutingTimeoutValue_String" SG_ 595 PSEAT_vent_req "0x0";
BA_ "GenSigSendType" SG_ 595 IVI_PTG_Sta_SW 3;
BA_ "GenSigRoutingTimeoutValue" SG_ 595 IVI_PTG_Sta_SW 2;
BA_ "GenSigRoutingTimeoutValue_String" SG_ 595 IVI_PTG_Sta_SW "0x2";
BA_ "GenSigInvalidValue" SG_ 595 IVI_PTG_Sta_SW 2;
BA_ "GenSigSendType" SG_ 595 IVI_ISA_OffsetSpd 3;
BA_ "GenSigRoutingTimeoutValue" SG_ 595 IVI_ISA_OffsetSpd 15;
BA_ "GenSigInactiveValue" SG_ 595 IVI_ISA_OffsetSpd 15;
BA_ "GenSigRoutingTimeoutValue_String" SG_ 595 IVI_ISA_OffsetSpd "0xF";
BA_ "GenSigStartValue" SG_ 595 IVI_ISA_OffsetSpd 15;
BA_ "GenSigInvalidValue" SG_ 595 IVI_ISA_OffsetSpd 15;
BA_ "GenSigRoutingTimeoutValue_String" SG_ 595 SenstivityPosition "0x0";
BA_ "GenSigRoutingTimeoutValue_String" SG_ 595 IVI_Time_Check "0x0";
BA_ "GenSigSendType" SG_ 595 Distance_unit 3;
BA_ "GenSigRoutingTimeoutValue_String" SG_ 595 Distance_unit "0x0";
BA_ "GenSigRoutingTimeoutValue_String" SG_ 595 IVI_Time_Year "0x0";
BA_ "GenSigSendType" SG_ 595 Hood_Latch_SW 3;
BA_ "GenSigRoutingTimeoutValue" SG_ 595 Hood_Latch_SW 2;
BA_ "GenSigRoutingTimeoutValue_String" SG_ 595 Hood_Latch_SW "0x2";
BA_ "GenSigInvalidValue" SG_ 595 Hood_Latch_SW 2;
BA_ "GenSigRoutingTimeoutValue_String" SG_ 595 IVI_Time_Minute "0x0";
BA_ "GenSigRoutingTimeoutValue_String" SG_ 595 IVI_Time_Second "0x0";
BA_ "GenSigSendType" SG_ 595 DSEAT_vent_req 3;
BA_ "GenSigRoutingTimeoutValue_String" SG_ 595 DSEAT_vent_req "0x0";
BA_ "GenSigRoutingTimeoutValue_String" SG_ 595 IVI_Time_Day "0x0";
BA_ "GenSigSendType" SG_ 595 HeadLampSW 3;
BA_ "GenSigRoutingTimeoutValue_String" SG_ 595 HeadLampSW "0x0";
BA_ "GenSigRoutingTimeoutValue_String" SG_ 595 IVI_Time_Hour "0x0";
BA_ "GenSigRoutingTimeoutValue_String" SG_ 595 IVI_Time_Month "0x0";
BA_ "GenSigSendType" SG_ 595 IVI_DSEATHeater_Cmd 3;
BA_ "GenSigRoutingTimeoutValue_String" SG_ 595 IVI_DSEATHeater_Cmd "0x0";
BA_ "GenSigSendType" SG_ 595 IVI_PSEATHeater_Cmd 3;
BA_ "GenSigRoutingTimeoutValue_String" SG_ 595 IVI_PSEATHeater_Cmd "0x0";
BA_ "GenSigSendType" SG_ 595 FDC_PTG_inner_SW_2 3;
BA_ "GenSigSendType" SG_ 595 BrkSw_V 3;
BA_ "GenSigRoutingTimeoutValue" SG_ 595 BrkSw_V 1;
BA_ "GenSigRoutingTimeoutValue_String" SG_ 595 BrkSw_V "0x1";
BA_ "GenSigInvalidValue" SG_ 595 BrkSw_V 1;
BA_ "GenSigSendType" SG_ 595 MCPressure 3;
BA_ "GenSigRoutingTimeoutValue" SG_ 595 MCPressure 4095;
BA_ "GenSigRoutingTimeoutValue_String" SG_ 595 MCPressure "0xFFF";
BA_ "GenSigStartValue" SG_ 595 MCPressure 97;
BA_ "GenSigInvalidValue" SG_ 595 MCPressure 4095;
BA_ "GenSigSendType" SG_ 595 MCPressure_V 3;
BA_ "GenSigRoutingTimeoutValue" SG_ 595 MCPressure_V 1;
BA_ "GenSigRoutingTimeoutValue_String" SG_ 595 MCPressure_V "0x1";
BA_ "GenSigInvalidValue" SG_ 595 MCPressure_V 1;
BA_ "GenSigSendType" SG_ 595 BrkPedalPos 3;
BA_ "GenSigRoutingTimeoutValue" SG_ 595 BrkPedalPos 255;
BA_ "GenSigRoutingTimeoutValue_String" SG_ 595 BrkPedalPos "0xFF";
BA_ "GenSigInvalidValue" SG_ 595 BrkPedalPos 255;
BA_ "GenSigSendType" SG_ 595 BrkPedalPos_Sta 3;
BA_ "GenSigRoutingTimeoutValue_String" SG_ 595 BrkPedalPos_Sta "0x0";
BA_ "GenSigRoutingTimeoutValue" SG_ 595 VehSpeed 4095;
BA_ "GenSigInactiveValue" SG_ 595 VehSpeed 4095;
BA_ "GenSigRoutingTimeoutValue_String" SG_ 595 VehSpeed "0xFFF";
BA_ "GenSigInvalidValue" SG_ 595 VehSpeed 4095;
BA_ "GenSigSendType" SG_ 595 L_Drv_CtrlCmd 3;
BA_ "GenSigRoutingTimeoutValue" SG_ 595 L_Drv_CtrlCmd 127;
BA_ "GenSigInactiveValue" SG_ 595 L_Drv_CtrlCmd 127;
BA_ "GenSigRoutingTimeoutValue_String" SG_ 595 L_Drv_CtrlCmd "0x7F";
BA_ "GenSigStartValue" SG_ 595 L_Drv_CtrlCmd 127;
BA_ "GenSigInvalidValue" SG_ 595 L_Drv_CtrlCmd 127;
BA_ "GenSigSendType" SG_ 595 L_Pas_CtrlCmd 3;
BA_ "GenSigRoutingTimeoutValue" SG_ 595 L_Pas_CtrlCmd 127;
BA_ "GenSigInactiveValue" SG_ 595 L_Pas_CtrlCmd 127;
BA_ "GenSigRoutingTimeoutValue_String" SG_ 595 L_Pas_CtrlCmd "0x7F";
BA_ "GenSigStartValue" SG_ 595 L_Pas_CtrlCmd 127;
BA_ "GenSigInvalidValue" SG_ 595 L_Pas_CtrlCmd 127;
BA_ "GenSigSendType" SG_ 595 L_RLD_CtrlCmd 3;
BA_ "GenSigRoutingTimeoutValue" SG_ 595 L_RLD_CtrlCmd 127;
BA_ "GenSigInactiveValue" SG_ 595 L_RLD_CtrlCmd 127;
BA_ "GenSigRoutingTimeoutValue_String" SG_ 595 L_RLD_CtrlCmd "0x7F";
BA_ "GenSigStartValue" SG_ 595 L_RLD_CtrlCmd 127;
BA_ "GenSigInvalidValue" SG_ 595 L_RLD_CtrlCmd 127;
BA_ "GenSigSendType" SG_ 595 L_RRD_CtrlCmd 3;
BA_ "GenSigRoutingTimeoutValue" SG_ 595 L_RRD_CtrlCmd 127;
BA_ "GenSigInactiveValue" SG_ 595 L_RRD_CtrlCmd 127;
BA_ "GenSigRoutingTimeoutValue_String" SG_ 595 L_RRD_CtrlCmd "0x7F";
BA_ "GenSigStartValue" SG_ 595 L_RRD_CtrlCmd 127;
BA_ "GenSigInvalidValue" SG_ 595 L_RRD_CtrlCmd 127;
BA_ "GenSigSendType" SG_ 595 OFF_AC_MODE 3;
BA_ "GenSigRoutingTimeoutValue" SG_ 595 OFF_AC_MODE 7;
BA_ "GenSigInactiveValue" SG_ 595 OFF_AC_MODE 7;
BA_ "GenSigRoutingTimeoutValue_String" SG_ 595 OFF_AC_MODE "0x7";
BA_ "GenSigInvalidValue" SG_ 595 OFF_AC_MODE 7;
BA_ "GenSigSendType" SG_ 595 WlcmLight_Mode 3;
BA_ "GenSigRoutingTimeoutValue_String" SG_ 595 WlcmLight_Mode "0x0";
BA_ "GenSigSendType" SG_ 595 Light_ShowStart_Req 3;
BA_ "GenSigRoutingTimeoutValue_String" SG_ 595 Light_ShowStart_Req "0x0";
BA_ "GenSigSendType" SG_ 595 Light_ShowStop_Req 3;
BA_ "GenSigRoutingTimeoutValue_String" SG_ 595 Light_ShowStop_Req "0x0";
BA_ "GenSigSendType" SG_ 595 AVM_parking_excute 3;
BA_ "GenSigRoutingTimeoutValue" SG_ 595 AVM_parking_excute 2;
BA_ "GenSigRoutingTimeoutValue_String" SG_ 595 AVM_parking_excute "0x2";
BA_ "GenSigInvalidValue" SG_ 595 AVM_parking_excute 2;
BA_ "GenSigSendType" SG_ 595 IVI_PTG_Open_Height 3;
BA_ "GenSigRoutingTimeoutValue" SG_ 595 IVI_PTG_Open_Height 7;
BA_ "GenSigInactiveValue" SG_ 595 IVI_PTG_Open_Height 5;
BA_ "GenSigRoutingTimeoutValue_String" SG_ 595 IVI_PTG_Open_Height "0x7";
BA_ "GenSigStartValue" SG_ 595 IVI_PTG_Open_Height 5;
BA_ "GenSigInvalidValue" SG_ 595 IVI_PTG_Open_Height 7;
BA_ "GenSigSendType" SG_ 595 TBOX_Remote_PW 3;
BA_ "GenSigRoutingTimeoutValue_String" SG_ 595 TBOX_Remote_PW "0x0";
BA_ "GenSigRoutingTimeoutValue" SG_ 595 METER_KPH_Calcu 255;
BA_ "GenSigRoutingTimeoutValue_String" SG_ 595 METER_KPH_Calcu "0xFF";
BA_ "GenSigInvalidValue" SG_ 595 METER_KPH_Calcu 255;
BA_ "GenSigSendType" SG_ 595 ChrgInLockReq 3;
BA_ "GenSigRoutingTimeoutValue_String" SG_ 595 ChrgInLockReq "0x0";
BA_ "GenSigSendType" SG_ 595 IVI_TrailerCheckReq_Sta 3;
BA_ "GenSigRoutingTimeoutValue_String" SG_ 595 IVI_TrailerCheckReq_Sta "0x0";
BA_ "GenSigSendType" SG_ 595 IVI_TrailerModeSW_Sta 3;
BA_ "GenSigRoutingTimeoutValue_String" SG_ 595 IVI_TrailerModeSW_Sta "0x0";
BA_ "GenSigSendType" SG_ 595 IVI_ChargePortSW_Sta 3;
BA_ "GenSigRoutingTimeoutValue_String" SG_ 595 IVI_ChargePortSW_Sta "0x0";
BA_ "GenSigSendType" SG_ 595 ChrgPlugSta 3;
BA_ "GenSigRoutingTimeoutValue_String" SG_ 595 ChrgPlugSta "0x0";
BA_ "GenSigSendType" SG_ 595 ExtChrgSta 3;
BA_ "GenSigRoutingTimeoutValue" SG_ 595 ExtChrgSta 3;
BA_ "GenSigRoutingTimeoutValue_String" SG_ 595 ExtChrgSta "0x3";
BA_ "GenSigSendType" SG_ 595 OBCV2LSta 3;
BA_ "GenSigRoutingTimeoutValue" SG_ 595 OBCV2LSta 2;
BA_ "GenSigRoutingTimeoutValue_String" SG_ 595 OBCV2LSta "0x2";
BA_ "GenSigSendType" SG_ 595 V2LSta 3;
BA_ "GenSigRoutingTimeoutValue" SG_ 595 V2LSta 3;
BA_ "GenSigInactiveValue" SG_ 595 V2LSta 3;
BA_ "GenSigRoutingTimeoutValue_String" SG_ 595 V2LSta "0x3";
BA_ "GenSigInvalidValue" SG_ 595 V2LSta 3;
BA_ "GenSigSendType" SG_ 1080 OTA_Progress_Rate 3;
BA_ "GenSigInvalidValue" SG_ 1080 OTA_Progress_Rate 102;
BA_ "GenSigSendType" SG_ 1080 OTA_MDA_Status 3;
BA_ "GenSigSendType" SG_ 1080 OTA_Network_Type 3;
BA_ "GenSigSendType" SG_ 1080 OTA_Mode 3;
BA_ "GenSigRoutingTimeoutValue_String" SG_ 1080 OTA_Mode "0x0";
BA_ "GenSigSendType" SG_ 1080 OTA_DL_Available 3;
BA_ "GenSigSendType" SG_ 1080 OTA_InVehicle_FW 3;
BA_ "GenSigSendType" SG_ 1080 OTA_Update_Available 3;
BA_ "GenSigSendType" SG_ 1080 OTA_Updating_ECU_8bit 3;
BA_ "GenSigInvalidValue" SG_ 1080 OTA_Updating_ECU_8bit 30;
BA_ "GenSigSendType" SG_ 1080 OTA_Lock_Req 3;
BA_ "GenSigSendType" SG_ 1080 OTA_TBOXResetReq 3;
BA_ "GenSigSendType" SG_ 1080 OTA_DL_Speed 3;
BA_ "GenSigInvalidValue" SG_ 1080 OTA_Remained_Time 1082;
BA_ "GenSigSendType" SG_ 1080 OTA_Emergency_Sta 3;
BA_ "GenSigRoutingTimeoutValue_String" SG_ 1080 OTA_Emergency_Sta "0x0";
BA_ "GenSigSendType" SG_ 1280 NM_FUSION_Node_ID 7;
BA_ "GenSigSendType" SG_ 1280 NM_FUSION_PNI 7;
BA_ "GenSigSendType" SG_ 1280 NM_FUSION_Active_WU 7;
BA_ "GenSigSendType" SG_ 1280 NM_FUSION_CSB 7;
BA_ "GenSigSendType" SG_ 1280 NM_FUSION_Rpt_Msg_Req 7;
BA_ "GenSigSendType" SG_ 1280 NM_FUSION_ERROR_State 7;
BA_ "GenSigSendType" SG_ 1668 DiagPhysReqToZONE_FR 3;
BA_ "GenSigSendType" SG_ 1669 DiagPhysReqToDKC 3;
BA_ "GenSigSendType" SG_ 1701 DiagPhysReqToAirPTC 3;
BA_ "GenSigSendType" SG_ 1717 DiagPhysReqToWPTC 3;
BA_ "GenSigSendType" SG_ 1728 DiagPhysReqToZONE_DR 3;
BA_ "GenSigSendType" SG_ 1733 DiagPhysReqToCompressor 3;
BA_ "GenSigSendType" SG_ 2000 DiagFuncReqFT 3;
BA_ "GenSigRoutingTimeoutValue_String" SG_ 1174 TimeSyncFromBS_Year "0x0";
BA_ "GenSigRoutingTimeoutValue_String" SG_ 1174 TimeSyncFromBS_Minute "0x0";
BA_ "GenSigRoutingTimeoutValue_String" SG_ 1174 TimeSyncFromBS_Second "0x0";
BA_ "GenSigRoutingTimeoutValue_String" SG_ 1174 TimeSyncFromBS_Day "0x0";
BA_ "GenSigRoutingTimeoutValue_String" SG_ 1174 TimeSyncFromBS_Hour "0x0";
BA_ "GenSigRoutingTimeoutValue_String" SG_ 1174 TimeSyncFromBS_Month "0x0";
BA_ "GenSigSendType" SG_ 497 DrPMMSysErrLmp 3;
BA_ "GenSigRoutingTimeoutValue_String" SG_ 497 DrPMMSysErrLmp "0x0";
BA_ "GenSigSendType" SG_ 497 DrPMMLVOutPErrLmp 3;
BA_ "GenSigRoutingTimeoutValue_String" SG_ 497 DrPMMLVOutPErrLmp "0x0";
BA_ "GenSigSendType" SG_ 497 DrPMMLimpHomeActReq 3;
BA_ "GenSigSendType" SG_ 497 DrAPWStaErr 3;
BA_ "GenSigRoutingTimeoutValue" SG_ 497 Blower_FB 15;
BA_ "GenSigInactiveValue" SG_ 497 Blower_FB 15;
BA_ "GenSigRoutingTimeoutValue_String" SG_ 497 Blower_FB "0xF";
BA_ "GenSigStartValue" SG_ 497 Blower_FB 15;
BA_ "GenSigInvalidValue" SG_ 497 Blower_FB 15;
BA_ "GenSigStartValue" SG_ 497 SolarR 253;
BA_ "GenSigStartValue" SG_ 497 SolarL 253;
BA_ "GenSigSendType" SG_ 497 APTC_Err 3;
BA_ "GenSigRoutingTimeoutValue" SG_ 497 APTC_Err 3;
BA_ "GenSigInactiveValue" SG_ 497 APTC_Err 3;
BA_ "GenSigRoutingTimeoutValue_String" SG_ 497 APTC_Err "0x3";
BA_ "GenSigStartValue" SG_ 497 APTC_Err 3;
BA_ "GenSigInvalidValue" SG_ 497 APTC_Err 3;
BA_ "GenSigSendType" SG_ 497 Blower_Err 3;
BA_ "GenSigRoutingTimeoutValue" SG_ 497 Blower_Err 3;
BA_ "GenSigInactiveValue" SG_ 497 Blower_Err 3;
BA_ "GenSigRoutingTimeoutValue_String" SG_ 497 Blower_Err "0x3";
BA_ "GenSigStartValue" SG_ 497 Blower_Err 3;
BA_ "GenSigInvalidValue" SG_ 497 Blower_Err 3;
BA_ "GenSigSendType" SG_ 497 T_Foot_Rr_Err 3;
BA_ "GenSigRoutingTimeoutValue" SG_ 497 T_Foot_Rr_Err 3;
BA_ "GenSigInactiveValue" SG_ 497 T_Foot_Rr_Err 3;
BA_ "GenSigRoutingTimeoutValue_String" SG_ 497 T_Foot_Rr_Err "0x3";
BA_ "GenSigStartValue" SG_ 497 T_Foot_Rr_Err 3;
BA_ "GenSigInvalidValue" SG_ 497 T_Foot_Rr_Err 3;
BA_ "GenSigSendType" SG_ 497 T_Face_Rr_Err 3;
BA_ "GenSigRoutingTimeoutValue" SG_ 497 T_Face_Rr_Err 3;
BA_ "GenSigInactiveValue" SG_ 497 T_Face_Rr_Err 3;
BA_ "GenSigRoutingTimeoutValue_String" SG_ 497 T_Face_Rr_Err "0x3";
BA_ "GenSigStartValue" SG_ 497 T_Face_Rr_Err 3;
BA_ "GenSigInvalidValue" SG_ 497 T_Face_Rr_Err 3;
BA_ "GenSigSendType" SG_ 497 T_Foot_R_Err 3;
BA_ "GenSigRoutingTimeoutValue" SG_ 497 T_Foot_R_Err 3;
BA_ "GenSigInactiveValue" SG_ 497 T_Foot_R_Err 3;
BA_ "GenSigRoutingTimeoutValue_String" SG_ 497 T_Foot_R_Err "0x3";
BA_ "GenSigStartValue" SG_ 497 T_Foot_R_Err 3;
BA_ "GenSigInvalidValue" SG_ 497 T_Foot_R_Err 3;
BA_ "GenSigSendType" SG_ 497 T_Face_R_Err 3;
BA_ "GenSigRoutingTimeoutValue" SG_ 497 T_Face_R_Err 3;
BA_ "GenSigInactiveValue" SG_ 497 T_Face_R_Err 3;
BA_ "GenSigRoutingTimeoutValue_String" SG_ 497 T_Face_R_Err "0x3";
BA_ "GenSigStartValue" SG_ 497 T_Face_R_Err 3;
BA_ "GenSigInvalidValue" SG_ 497 T_Face_R_Err 3;
BA_ "GenSigSendType" SG_ 497 T_Foot_L_Err 3;
BA_ "GenSigRoutingTimeoutValue" SG_ 497 T_Foot_L_Err 3;
BA_ "GenSigInactiveValue" SG_ 497 T_Foot_L_Err 3;
BA_ "GenSigRoutingTimeoutValue_String" SG_ 497 T_Foot_L_Err "0x3";
BA_ "GenSigStartValue" SG_ 497 T_Foot_L_Err 3;
BA_ "GenSigInvalidValue" SG_ 497 T_Foot_L_Err 3;
BA_ "GenSigSendType" SG_ 497 T_Face_L_Err 3;
BA_ "GenSigRoutingTimeoutValue" SG_ 497 T_Face_L_Err 3;
BA_ "GenSigInactiveValue" SG_ 497 T_Face_L_Err 3;
BA_ "GenSigRoutingTimeoutValue_String" SG_ 497 T_Face_L_Err "0x3";
BA_ "GenSigStartValue" SG_ 497 T_Face_L_Err 3;
BA_ "GenSigInvalidValue" SG_ 497 T_Face_L_Err 3;
BA_ "GenSigSendType" SG_ 497 Tincar_Err 3;
BA_ "GenSigRoutingTimeoutValue" SG_ 497 Tincar_Err 3;
BA_ "GenSigInactiveValue" SG_ 497 Tincar_Err 3;
BA_ "GenSigRoutingTimeoutValue_String" SG_ 497 Tincar_Err "0x3";
BA_ "GenSigStartValue" SG_ 497 Tincar_Err 3;
BA_ "GenSigInvalidValue" SG_ 497 Tincar_Err 3;
BA_ "GenSigSendType" SG_ 497 Tevap_Err 3;
BA_ "GenSigRoutingTimeoutValue" SG_ 497 Tevap_Err 3;
BA_ "GenSigInactiveValue" SG_ 497 Tevap_Err 3;
BA_ "GenSigRoutingTimeoutValue_String" SG_ 497 Tevap_Err "0x3";
BA_ "GenSigStartValue" SG_ 497 Tevap_Err 3;
BA_ "GenSigInvalidValue" SG_ 497 Tevap_Err 3;
BA_ "GenSigSendType" SG_ 497 SolarR_Err 3;
BA_ "GenSigRoutingTimeoutValue" SG_ 497 SolarR_Err 3;
BA_ "GenSigInactiveValue" SG_ 497 SolarR_Err 3;
BA_ "GenSigRoutingTimeoutValue_String" SG_ 497 SolarR_Err "0x3";
BA_ "GenSigStartValue" SG_ 497 SolarR_Err 3;
BA_ "GenSigInvalidValue" SG_ 497 SolarR_Err 3;
BA_ "GenSigSendType" SG_ 497 SolarL_Err 3;
BA_ "GenSigRoutingTimeoutValue" SG_ 497 SolarL_Err 3;
BA_ "GenSigInactiveValue" SG_ 497 SolarL_Err 3;
BA_ "GenSigRoutingTimeoutValue_String" SG_ 497 SolarL_Err "0x3";
BA_ "GenSigStartValue" SG_ 497 SolarL_Err 3;
BA_ "GenSigInvalidValue" SG_ 497 SolarL_Err 3;
BA_ "GenSigSendType" SG_ 497 DrSCPSysErrLmp 3;
BA_ "GenSigRoutingTimeoutValue_String" SG_ 497 DrSCPSysErrLmp "0x0";
BA_ "GenSigSendType" SG_ 497 ZoneDrMalfunLevel 3;
BA_ "GenSigRoutingTimeoutValue" SG_ 497 ZoneDrMalfunLevel 5;
BA_ "GenSigInactiveValue" SG_ 497 ZoneDrMalfunLevel 5;
BA_ "GenSigRoutingTimeoutValue_String" SG_ 497 ZoneDrMalfunLevel "0x5";
BA_ "GenSigStartValue" SG_ 497 ZoneDrMalfunLevel 5;
BA_ "GenSigInvalidValue" SG_ 497 ZoneDrMalfunLevel 5;
BA_ "GenSigSendType" SG_ 497 DrAPWLINErr 3;
BA_ "GenSigSendType" SG_ 497 DrONA1ErrSta 3;
BA_ "GenSigSendType" SG_ 497 DrStdAErrSta 3;
BA_ "GenSigSendType" SG_ 497 DrPwrWinErrSta 3;
BA_ "GenSigSendType" SG_ 497 DrInfoErrSta 3;
BA_ "GenSigSendType" SG_ 497 RegenSW_Err 3;
BA_ "GenSigSendType" SG_ 497 DrPwrSta 3;
BA_ "GenSigRoutingTimeoutValue" SG_ 497 DrPwrSta 7;
BA_ "GenSigInactiveValue" SG_ 497 DrPwrSta 7;
BA_ "GenSigRoutingTimeoutValue_String" SG_ 497 DrPwrSta "0x7";
BA_ "GenSigStartValue" SG_ 497 DrPwrSta 7;
BA_ "GenSigInvalidValue" SG_ 497 DrPwrSta 7;
BA_ "GenSigSendType" SG_ 497 DrPwrInformationSta 3;
BA_ "GenSigSendType" SG_ 497 ZDR_SYS_APMRetryCnt_Sta 3;
BA_ "GenSigSendType" SG_ 497 ZDR_SYS_CSWRetryCnt_Sta 3;
BA_ "GenSigSendType" SG_ 497 ZDR_SYS_BSWSleepReq_Sta 3;
BA_ "GenSigSendType" SG_ 497 ZDR_VCU_HWReset_Sta 3;
BA_ "GenSigSendType" SG_ 497 ZDR_VCU_PwrSupply_Sta 3;
BA_ "GenSigSendType" SG_ 498 FrPMMSysErrLmp 3;
BA_ "GenSigSendType" SG_ 498 FrPMMLVOutPErrLmp 3;
BA_ "GenSigSendType" SG_ 498 FrPMMLimpHomeActReq 3;
BA_ "GenSigRoutingTimeoutValue_String" SG_ 498 FrPMMLimpHomeActReq "0x0";
BA_ "GenSigSendType" SG_ 498 ZoneFrMalfunLevel 3;
BA_ "GenSigRoutingTimeoutValue" SG_ 498 ZoneFrMalfunLevel 5;
BA_ "GenSigInactiveValue" SG_ 498 ZoneFrMalfunLevel 5;
BA_ "GenSigRoutingTimeoutValue_String" SG_ 498 ZoneFrMalfunLevel "0x5";
BA_ "GenSigStartValue" SG_ 498 ZoneFrMalfunLevel 5;
BA_ "GenSigInvalidValue" SG_ 498 ZoneFrMalfunLevel 5;
BA_ "GenSigSendType" SG_ 498 FrStdA1PCErr 3;
BA_ "GenSigSendType" SG_ 498 FrStdA2PErr 3;
BA_ "GenSigSendType" SG_ 498 FrStdA2PCErr 3;
BA_ "GenSigSendType" SG_ 498 FrBMSCCUCErr 3;
BA_ "GenSigSendType" SG_ 498 FrEDUErr 3;
BA_ "GenSigSendType" SG_ 498 FrPwrSta 3;
BA_ "GenSigRoutingTimeoutValue" SG_ 498 FrPwrSta 7;
BA_ "GenSigInactiveValue" SG_ 498 FrPwrSta 7;
BA_ "GenSigRoutingTimeoutValue_String" SG_ 498 FrPwrSta "0x7";
BA_ "GenSigStartValue" SG_ 498 FrPwrSta 7;
BA_ "GenSigInvalidValue" SG_ 498 FrPwrSta 7;
BA_ "GenSigSendType" SG_ 498 EACProtectEnable 3;
BA_ "GenSigStartValue" SG_ 498 PT_High_P 2700;
BA_ "GenSigSendType" SG_ 498 TWV_Err 3;
BA_ "GenSigRoutingTimeoutValue" SG_ 498 TWV_Err 3;
BA_ "GenSigInactiveValue" SG_ 498 TWV_Err 3;
BA_ "GenSigRoutingTimeoutValue_String" SG_ 498 TWV_Err "0x3";
BA_ "GenSigStartValue" SG_ 498 TWV_Err 3;
BA_ "GenSigInvalidValue" SG_ 498 TWV_Err 3;
BA_ "GenSigSendType" SG_ 498 EWP3_Err 3;
BA_ "GenSigRoutingTimeoutValue" SG_ 498 EWP3_Err 3;
BA_ "GenSigInactiveValue" SG_ 498 EWP3_Err 3;
BA_ "GenSigRoutingTimeoutValue_String" SG_ 498 EWP3_Err "0x3";
BA_ "GenSigStartValue" SG_ 498 EWP3_Err 3;
BA_ "GenSigInvalidValue" SG_ 498 EWP3_Err 3;
BA_ "GenSigSendType" SG_ 498 EWP2_Err 3;
BA_ "GenSigRoutingTimeoutValue" SG_ 498 EWP2_Err 3;
BA_ "GenSigInactiveValue" SG_ 498 EWP2_Err 3;
BA_ "GenSigRoutingTimeoutValue_String" SG_ 498 EWP2_Err "0x3";
BA_ "GenSigStartValue" SG_ 498 EWP2_Err 3;
BA_ "GenSigInvalidValue" SG_ 498 EWP2_Err 3;
BA_ "GenSigSendType" SG_ 498 FWV_Err 3;
BA_ "GenSigRoutingTimeoutValue" SG_ 498 FWV_Err 3;
BA_ "GenSigInactiveValue" SG_ 498 FWV_Err 3;
BA_ "GenSigRoutingTimeoutValue_String" SG_ 498 FWV_Err "0x3";
BA_ "GenSigStartValue" SG_ 498 FWV_Err 3;
BA_ "GenSigInvalidValue" SG_ 498 FWV_Err 3;
BA_ "GenSigSendType" SG_ 498 EWP1_Err 3;
BA_ "GenSigRoutingTimeoutValue" SG_ 498 EWP1_Err 3;
BA_ "GenSigInactiveValue" SG_ 498 EWP1_Err 3;
BA_ "GenSigRoutingTimeoutValue_String" SG_ 498 EWP1_Err "0x3";
BA_ "GenSigStartValue" SG_ 498 EWP1_Err 3;
BA_ "GenSigInvalidValue" SG_ 498 EWP1_Err 3;
BA_ "GenSigSendType" SG_ 498 WPTC_Err 3;
BA_ "GenSigRoutingTimeoutValue" SG_ 498 WPTC_Err 3;
BA_ "GenSigInactiveValue" SG_ 498 WPTC_Err 3;
BA_ "GenSigRoutingTimeoutValue_String" SG_ 498 WPTC_Err "0x3";
BA_ "GenSigStartValue" SG_ 498 WPTC_Err 3;
BA_ "GenSigInvalidValue" SG_ 498 WPTC_Err 3;
BA_ "GenSigSendType" SG_ 498 Fan_Err 3;
BA_ "GenSigRoutingTimeoutValue" SG_ 498 Fan_Err 3;
BA_ "GenSigInactiveValue" SG_ 498 Fan_Err 3;
BA_ "GenSigRoutingTimeoutValue_String" SG_ 498 Fan_Err "0x3";
BA_ "GenSigStartValue" SG_ 498 Fan_Err 3;
BA_ "GenSigInvalidValue" SG_ 498 Fan_Err 3;
BA_ "GenSigSendType" SG_ 498 EXV2_Err 3;
BA_ "GenSigRoutingTimeoutValue" SG_ 498 EXV2_Err 3;
BA_ "GenSigInactiveValue" SG_ 498 EXV2_Err 3;
BA_ "GenSigRoutingTimeoutValue_String" SG_ 498 EXV2_Err "0x3";
BA_ "GenSigStartValue" SG_ 498 EXV2_Err 3;
BA_ "GenSigInvalidValue" SG_ 498 EXV2_Err 3;
BA_ "GenSigSendType" SG_ 498 EXV1_Err 3;
BA_ "GenSigRoutingTimeoutValue" SG_ 498 EXV1_Err 3;
BA_ "GenSigInactiveValue" SG_ 498 EXV1_Err 3;
BA_ "GenSigRoutingTimeoutValue_String" SG_ 498 EXV1_Err "0x3";
BA_ "GenSigStartValue" SG_ 498 EXV1_Err 3;
BA_ "GenSigInvalidValue" SG_ 498 EXV1_Err 3;
BA_ "GenSigSendType" SG_ 498 SOTXV_Err 3;
BA_ "GenSigRoutingTimeoutValue" SG_ 498 SOTXV_Err 3;
BA_ "GenSigInactiveValue" SG_ 498 SOTXV_Err 3;
BA_ "GenSigRoutingTimeoutValue_String" SG_ 498 SOTXV_Err "0x3";
BA_ "GenSigStartValue" SG_ 498 SOTXV_Err 3;
BA_ "GenSigInvalidValue" SG_ 498 SOTXV_Err 3;
BA_ "GenSigSendType" SG_ 498 COMP_Err 3;
BA_ "GenSigRoutingTimeoutValue" SG_ 498 COMP_Err 3;
BA_ "GenSigInactiveValue" SG_ 498 COMP_Err 3;
BA_ "GenSigRoutingTimeoutValue_String" SG_ 498 COMP_Err "0x3";
BA_ "GenSigStartValue" SG_ 498 COMP_Err 3;
BA_ "GenSigInvalidValue" SG_ 498 COMP_Err 3;
BA_ "GenSigSendType" SG_ 498 SOV3_Err 3;
BA_ "GenSigRoutingTimeoutValue" SG_ 498 SOV3_Err 3;
BA_ "GenSigInactiveValue" SG_ 498 SOV3_Err 3;
BA_ "GenSigRoutingTimeoutValue_String" SG_ 498 SOV3_Err "0x3";
BA_ "GenSigStartValue" SG_ 498 SOV3_Err 3;
BA_ "GenSigInvalidValue" SG_ 498 SOV3_Err 3;
BA_ "GenSigSendType" SG_ 498 SOV2_Err 3;
BA_ "GenSigRoutingTimeoutValue" SG_ 498 SOV2_Err 3;
BA_ "GenSigInactiveValue" SG_ 498 SOV2_Err 3;
BA_ "GenSigRoutingTimeoutValue_String" SG_ 498 SOV2_Err "0x3";
BA_ "GenSigStartValue" SG_ 498 SOV2_Err 3;
BA_ "GenSigInvalidValue" SG_ 498 SOV2_Err 3;
BA_ "GenSigSendType" SG_ 498 SOV1_Err 3;
BA_ "GenSigRoutingTimeoutValue" SG_ 498 SOV1_Err 3;
BA_ "GenSigInactiveValue" SG_ 498 SOV1_Err 3;
BA_ "GenSigRoutingTimeoutValue_String" SG_ 498 SOV1_Err "0x3";
BA_ "GenSigStartValue" SG_ 498 SOV1_Err 3;
BA_ "GenSigInvalidValue" SG_ 498 SOV1_Err 3;
BA_ "GenSigSendType" SG_ 498 PT_High_Tact_Err 3;
BA_ "GenSigRoutingTimeoutValue" SG_ 498 PT_High_Tact_Err 3;
BA_ "GenSigInactiveValue" SG_ 498 PT_High_Tact_Err 3;
BA_ "GenSigRoutingTimeoutValue_String" SG_ 498 PT_High_Tact_Err "0x3";
BA_ "GenSigStartValue" SG_ 498 PT_High_Tact_Err 3;
BA_ "GenSigInvalidValue" SG_ 498 PT_High_Tact_Err 3;
BA_ "GenSigSendType" SG_ 498 PT_High_P_Err 3;
BA_ "GenSigRoutingTimeoutValue" SG_ 498 PT_High_P_Err 3;
BA_ "GenSigInactiveValue" SG_ 498 PT_High_P_Err 3;
BA_ "GenSigRoutingTimeoutValue_String" SG_ 498 PT_High_P_Err "0x3";
BA_ "GenSigStartValue" SG_ 498 PT_High_P_Err 3;
BA_ "GenSigInvalidValue" SG_ 498 PT_High_P_Err 3;
BA_ "GenSigSendType" SG_ 498 PT_Low_T2_Err 3;
BA_ "GenSigRoutingTimeoutValue" SG_ 498 PT_Low_T2_Err 3;
BA_ "GenSigInactiveValue" SG_ 498 PT_Low_T2_Err 3;
BA_ "GenSigRoutingTimeoutValue_String" SG_ 498 PT_Low_T2_Err "0x3";
BA_ "GenSigStartValue" SG_ 498 PT_Low_T2_Err 3;
BA_ "GenSigInvalidValue" SG_ 498 PT_Low_T2_Err 3;
BA_ "GenSigSendType" SG_ 498 PT_Low_P2_Err 3;
BA_ "GenSigRoutingTimeoutValue" SG_ 498 PT_Low_P2_Err 3;
BA_ "GenSigInactiveValue" SG_ 498 PT_Low_P2_Err 3;
BA_ "GenSigRoutingTimeoutValue_String" SG_ 498 PT_Low_P2_Err "0x3";
BA_ "GenSigStartValue" SG_ 498 PT_Low_P2_Err 3;
BA_ "GenSigInvalidValue" SG_ 498 PT_Low_P2_Err 3;
BA_ "GenSigSendType" SG_ 498 PT_Low_T1_Err 3;
BA_ "GenSigRoutingTimeoutValue" SG_ 498 PT_Low_T1_Err 3;
BA_ "GenSigInactiveValue" SG_ 498 PT_Low_T1_Err 3;
BA_ "GenSigRoutingTimeoutValue_String" SG_ 498 PT_Low_T1_Err "0x3";
BA_ "GenSigStartValue" SG_ 498 PT_Low_T1_Err 3;
BA_ "GenSigInvalidValue" SG_ 498 PT_Low_T1_Err 3;
BA_ "GenSigSendType" SG_ 498 PT_Low_P1_Err 3;
BA_ "GenSigRoutingTimeoutValue" SG_ 498 PT_Low_P1_Err 3;
BA_ "GenSigInactiveValue" SG_ 498 PT_Low_P1_Err 3;
BA_ "GenSigRoutingTimeoutValue_String" SG_ 498 PT_Low_P1_Err "0x3";
BA_ "GenSigStartValue" SG_ 498 PT_Low_P1_Err 3;
BA_ "GenSigInvalidValue" SG_ 498 PT_Low_P1_Err 3;
BA_ "GenSigSendType" SG_ 498 Motor_Out_Temp_Err 3;
BA_ "GenSigRoutingTimeoutValue" SG_ 498 Motor_Out_Temp_Err 3;
BA_ "GenSigInactiveValue" SG_ 498 Motor_Out_Temp_Err 3;
BA_ "GenSigRoutingTimeoutValue_String" SG_ 498 Motor_Out_Temp_Err "0x3";
BA_ "GenSigStartValue" SG_ 498 Motor_Out_Temp_Err 3;
BA_ "GenSigInvalidValue" SG_ 498 Motor_Out_Temp_Err 3;
BA_ "GenSigSendType" SG_ 498 Bat_Out_Temp_Err 3;
BA_ "GenSigRoutingTimeoutValue" SG_ 498 Bat_Out_Temp_Err 3;
BA_ "GenSigInactiveValue" SG_ 498 Bat_Out_Temp_Err 3;
BA_ "GenSigRoutingTimeoutValue_String" SG_ 498 Bat_Out_Temp_Err "0x3";
BA_ "GenSigStartValue" SG_ 498 Bat_Out_Temp_Err 3;
BA_ "GenSigInvalidValue" SG_ 498 Bat_Out_Temp_Err 3;
BA_ "GenSigSendType" SG_ 498 Motor_In_Temp_Err 3;
BA_ "GenSigRoutingTimeoutValue" SG_ 498 Motor_In_Temp_Err 3;
BA_ "GenSigInactiveValue" SG_ 498 Motor_In_Temp_Err 3;
BA_ "GenSigRoutingTimeoutValue_String" SG_ 498 Motor_In_Temp_Err "0x3";
BA_ "GenSigStartValue" SG_ 498 Motor_In_Temp_Err 3;
BA_ "GenSigInvalidValue" SG_ 498 Motor_In_Temp_Err 3;
BA_ "GenSigSendType" SG_ 498 Bat_In_Temp_Err 3;
BA_ "GenSigRoutingTimeoutValue" SG_ 498 Bat_In_Temp_Err 3;
BA_ "GenSigInactiveValue" SG_ 498 Bat_In_Temp_Err 3;
BA_ "GenSigRoutingTimeoutValue_String" SG_ 498 Bat_In_Temp_Err "0x3";
BA_ "GenSigStartValue" SG_ 498 Bat_In_Temp_Err 3;
BA_ "GenSigInvalidValue" SG_ 498 Bat_In_Temp_Err 3;
BA_ "GenSigSendType" SG_ 498 Tamb_Err 3;
BA_ "GenSigRoutingTimeoutValue" SG_ 498 Tamb_Err 3;
BA_ "GenSigInactiveValue" SG_ 498 Tamb_Err 3;
BA_ "GenSigRoutingTimeoutValue_String" SG_ 498 Tamb_Err "0x3";
BA_ "GenSigStartValue" SG_ 498 Tamb_Err 3;
BA_ "GenSigInvalidValue" SG_ 498 Tamb_Err 3;
BA_ "GenSigSendType" SG_ 498 ZFR_SYS_MCURetryCnt_Sta 3;
BA_ "GenSigSendType" SG_ 498 ZFR_SYS_BMSCCURetryCnt_Sta 3;
BA_ "GenSigSendType" SG_ 498 ZFR_SYS_BSWSleepReq_Sta 3;
BA_ "GenSigSendType" SG_ 498 ZFR_VCU_HWReset_Sta 3;
BA_ "GenSigSendType" SG_ 498 ZFR_VCU_PwrSupply_Sta 3;
BA_ "GenSigRoutingTimeoutValue_String" SG_ 547 FrntPTCSts "0x0";
BA_ "GenSigRoutingTimeoutValue_String" SG_ 547 FrntPTCFltSt "0x0";
BA_ "GenSigRoutingTimeoutValue_String" SG_ 547 FrntPTCLVUnderUFlt "0x0";
BA_ "GenSigRoutingTimeoutValue_String" SG_ 547 FrntPTCLVOverUFlt "0x0";
BA_ "GenSigRoutingTimeoutValue_String" SG_ 547 FrntPTCHVUnderUFlt "0x0";
BA_ "GenSigRoutingTimeoutValue_String" SG_ 547 FrntPTCHVOverUFlt "0x0";
BA_ "GenSigRoutingTimeoutValue_String" SG_ 547 FrntPTCLeOverAFlt "0x0";
BA_ "GenSigRoutingTimeoutValue_String" SG_ 547 FrntPTCRiOverAFlt "0x0";
BA_ "GenSigRoutingTimeoutValue_String" SG_ 547 FrntPTCLeCoreTSnsrFlt "0x0";
BA_ "GenSigRoutingTimeoutValue_String" SG_ 547 FrntPTCRiCoreTSnsrFlt "0x0";
BA_ "GenSigRoutingTimeoutValue_String" SG_ 547 FrntPTCLeCoreOverTFlt "0x0";
BA_ "GenSigRoutingTimeoutValue_String" SG_ 547 FrntPTCRiCoreOverTFlt "0x0";
BA_ "GenSigRoutingTimeoutValue_String" SG_ 547 FrntPTCLeIGBTShoCircFlt "0x0";
BA_ "GenSigRoutingTimeoutValue_String" SG_ 547 FrntPTCRiIGBTShoCircFlt "0x0";
BA_ "GenSigRoutingTimeoutValue_String" SG_ 547 FrntPTCLeOpentCircFlt "0x0";
BA_ "GenSigRoutingTimeoutValue_String" SG_ 547 FrntPTCRiOpentCircFlt "0x0";
BA_ "GenSigRoutingTimeoutValue_String" SG_ 547 FrntPTCPCBTSnsrFlt "0x0";
BA_ "GenSigRoutingTimeoutValue_String" SG_ 547 FrntPTCPCBOverTFlt "0x0";
BA_ "GenSigRoutingTimeoutValue_String" SG_ 547 FrntPTCComFlt "0x0";
BA_ "GenSigRoutingTimeoutValue_String" SG_ 547 FrntPTCLeIGBTTSnsrFlt "0x0";
BA_ "GenSigRoutingTimeoutValue_String" SG_ 547 FrntPTCRiIGBTTSnsrFlt "0x0";
BA_ "GenSigRoutingTimeoutValue_String" SG_ 547 FrntPTCLeIGBTOverTFlt "0x0";
BA_ "GenSigRoutingTimeoutValue_String" SG_ 547 FrntPTCRiIGBTOverTFlt "0x0";
BA_ "GenSigRoutingTimeoutValue_String" SG_ 547 FrntPTCSWVers "0x0";
BA_ "GenSigRoutingTimeoutValue_String" SG_ 547 FrntPTCHWVers "0x0";
BA_ "GenSigRoutingTimeoutValue_String" SG_ 547 FrntPTCSupplierCod "0x0";
BA_ "GenSigRoutingTimeoutValue_String" SG_ 547 FrntPTCRearLeOverAFlt "0x0";
BA_ "GenSigRoutingTimeoutValue_String" SG_ 547 FrntPTCRearLeOpentCircFlt "0x0";
BA_ "GenSigRoutingTimeoutValue_String" SG_ 547 FrntPTCRearRiCoreOverTFlt "0x0";
BA_ "GenSigRoutingTimeoutValue_String" SG_ 547 FrntPTCRearLeCoreOverTFlt "0x0";
BA_ "GenSigRoutingTimeoutValue_String" SG_ 547 FrntPTCRearRiCoreTSnsrFlt "0x0";
BA_ "GenSigRoutingTimeoutValue_String" SG_ 547 FrntPTCRearLeCoreTSnsrFlt "0x0";
BA_ "GenSigRoutingTimeoutValue_String" SG_ 547 FrntPTCRearRiOverAFlt "0x0";
BA_ "GenSigRoutingTimeoutValue_String" SG_ 547 FrntPTCRearRiOpentCircFlt "0x0";
BA_ "GenSigRoutingTimeoutValue_String" SG_ 547 FrntPTCRearRiIGBTShoCFlt "0x0";
BA_ "GenSigRoutingTimeoutValue_String" SG_ 547 FrntPTCRearLeIGBTShoCFlt "0x0";
BA_ "GenSigRoutingTimeoutValue" SG_ 547 FrntPTCRearLeBusLineC 255;
BA_ "GenSigInactiveValue" SG_ 547 FrntPTCRearLeBusLineC 255;
BA_ "GenSigRoutingTimeoutValue_String" SG_ 547 FrntPTCRearLeBusLineC "0xFF";
BA_ "GenSigStartValue" SG_ 547 FrntPTCRearLeBusLineC 255;
BA_ "GenSigInvalidValue" SG_ 547 FrntPTCRearLeBusLineC 255;
BA_ "GenSigRoutingTimeoutValue" SG_ 547 FrntPTCLeCoreT 255;
BA_ "GenSigInactiveValue" SG_ 547 FrntPTCLeCoreT 255;
BA_ "GenSigRoutingTimeoutValue_String" SG_ 547 FrntPTCLeCoreT "0xFF";
BA_ "GenSigStartValue" SG_ 547 FrntPTCLeCoreT 255;
BA_ "GenSigInvalidValue" SG_ 547 FrntPTCLeCoreT 255;
BA_ "GenSigRoutingTimeoutValue" SG_ 547 FrntPTCRiCoreT 255;
BA_ "GenSigInactiveValue" SG_ 547 FrntPTCRiCoreT 255;
BA_ "GenSigRoutingTimeoutValue_String" SG_ 547 FrntPTCRiCoreT "0xFF";
BA_ "GenSigStartValue" SG_ 547 FrntPTCRiCoreT 255;
BA_ "GenSigInvalidValue" SG_ 547 FrntPTCRiCoreT 255;
BA_ "GenSigRoutingTimeoutValue" SG_ 547 FrntPTCLeActHeatPwr 255;
BA_ "GenSigInactiveValue" SG_ 547 FrntPTCLeActHeatPwr 255;
BA_ "GenSigRoutingTimeoutValue_String" SG_ 547 FrntPTCLeActHeatPwr "0xFF";
BA_ "GenSigStartValue" SG_ 547 FrntPTCLeActHeatPwr 255;
BA_ "GenSigInvalidValue" SG_ 547 FrntPTCLeActHeatPwr 255;
BA_ "GenSigRoutingTimeoutValue" SG_ 547 FrntPTCRiActHeatPwr 255;
BA_ "GenSigInactiveValue" SG_ 547 FrntPTCRiActHeatPwr 255;
BA_ "GenSigRoutingTimeoutValue_String" SG_ 547 FrntPTCRiActHeatPwr "0xFF";
BA_ "GenSigStartValue" SG_ 547 FrntPTCRiActHeatPwr 255;
BA_ "GenSigInvalidValue" SG_ 547 FrntPTCRiActHeatPwr 255;
BA_ "GenSigRoutingTimeoutValue" SG_ 547 FrntPTCLeIGBTT 255;
BA_ "GenSigInactiveValue" SG_ 547 FrntPTCLeIGBTT 255;
BA_ "GenSigRoutingTimeoutValue_String" SG_ 547 FrntPTCLeIGBTT "0xFF";
BA_ "GenSigStartValue" SG_ 547 FrntPTCLeIGBTT 255;
BA_ "GenSigInvalidValue" SG_ 547 FrntPTCLeIGBTT 255;
BA_ "GenSigRoutingTimeoutValue" SG_ 547 FrntPTCRiIGBTT 255;
BA_ "GenSigInactiveValue" SG_ 547 FrntPTCRiIGBTT 255;
BA_ "GenSigRoutingTimeoutValue_String" SG_ 547 FrntPTCRiIGBTT "0xFF";
BA_ "GenSigStartValue" SG_ 547 FrntPTCRiIGBTT 255;
BA_ "GenSigInvalidValue" SG_ 547 FrntPTCRiIGBTT 255;
BA_ "GenSigRoutingTimeoutValue" SG_ 547 FrntPTCPCBT 255;
BA_ "GenSigInactiveValue" SG_ 547 FrntPTCPCBT 255;
BA_ "GenSigRoutingTimeoutValue_String" SG_ 547 FrntPTCPCBT "0xFF";
BA_ "GenSigStartValue" SG_ 547 FrntPTCPCBT 255;
BA_ "GenSigInvalidValue" SG_ 547 FrntPTCPCBT 255;
BA_ "GenSigRoutingTimeoutValue" SG_ 547 FrntPTCRearRiBusLineC 255;
BA_ "GenSigInactiveValue" SG_ 547 FrntPTCRearRiBusLineC 255;
BA_ "GenSigRoutingTimeoutValue_String" SG_ 547 FrntPTCRearRiBusLineC "0xFF";
BA_ "GenSigStartValue" SG_ 547 FrntPTCRearRiBusLineC 255;
BA_ "GenSigInvalidValue" SG_ 547 FrntPTCRearRiBusLineC 255;
BA_ "GenSigRoutingTimeoutValue" SG_ 547 FrntPTCRearLeActHeatPwr 255;
BA_ "GenSigInactiveValue" SG_ 547 FrntPTCRearLeActHeatPwr 255;
BA_ "GenSigRoutingTimeoutValue_String" SG_ 547 FrntPTCRearLeActHeatPwr "0xFF";
BA_ "GenSigStartValue" SG_ 547 FrntPTCRearLeActHeatPwr 255;
BA_ "GenSigInvalidValue" SG_ 547 FrntPTCRearLeActHeatPwr 255;
BA_ "GenSigRoutingTimeoutValue" SG_ 547 FrntPTCRearLeCoreT 255;
BA_ "GenSigInactiveValue" SG_ 547 FrntPTCRearLeCoreT 255;
BA_ "GenSigRoutingTimeoutValue_String" SG_ 547 FrntPTCRearLeCoreT "0xFF";
BA_ "GenSigStartValue" SG_ 547 FrntPTCRearLeCoreT 255;
BA_ "GenSigInvalidValue" SG_ 547 FrntPTCRearLeCoreT 255;
BA_ "GenSigRoutingTimeoutValue" SG_ 547 FrntPTCRearRiActHeatPwr 255;
BA_ "GenSigInactiveValue" SG_ 547 FrntPTCRearRiActHeatPwr 255;
BA_ "GenSigRoutingTimeoutValue_String" SG_ 547 FrntPTCRearRiActHeatPwr "0xFF";
BA_ "GenSigStartValue" SG_ 547 FrntPTCRearRiActHeatPwr 255;
BA_ "GenSigInvalidValue" SG_ 547 FrntPTCRearRiActHeatPwr 255;
BA_ "GenSigRoutingTimeoutValue" SG_ 547 FrntPTCRearRiCoreT 255;
BA_ "GenSigInactiveValue" SG_ 547 FrntPTCRearRiCoreT 255;
BA_ "GenSigRoutingTimeoutValue_String" SG_ 547 FrntPTCRearRiCoreT "0xFF";
BA_ "GenSigStartValue" SG_ 547 FrntPTCRearRiCoreT 255;
BA_ "GenSigInvalidValue" SG_ 547 FrntPTCRearRiCoreT 255;
BA_ "GenSigRoutingTimeoutValue" SG_ 547 FrntPTCLeBusLineC 255;
BA_ "GenSigInactiveValue" SG_ 547 FrntPTCLeBusLineC 255;
BA_ "GenSigRoutingTimeoutValue_String" SG_ 547 FrntPTCLeBusLineC "0xFF";
BA_ "GenSigStartValue" SG_ 547 FrntPTCLeBusLineC 255;
BA_ "GenSigInvalidValue" SG_ 547 FrntPTCLeBusLineC 255;
BA_ "GenSigRoutingTimeoutValue" SG_ 547 FrntPTCRiBusLineC 255;
BA_ "GenSigInactiveValue" SG_ 547 FrntPTCRiBusLineC 255;
BA_ "GenSigRoutingTimeoutValue_String" SG_ 547 FrntPTCRiBusLineC "0xFF";
BA_ "GenSigStartValue" SG_ 547 FrntPTCRiBusLineC 255;
BA_ "GenSigInvalidValue" SG_ 547 FrntPTCRiBusLineC 255;
BA_ "GenSigRoutingTimeoutValue" SG_ 547 FrntPTCBusLineHiV 1023;
BA_ "GenSigInactiveValue" SG_ 547 FrntPTCBusLineHiV 1023;
BA_ "GenSigRoutingTimeoutValue_String" SG_ 547 FrntPTCBusLineHiV "0x3FF";
BA_ "GenSigStartValue" SG_ 547 FrntPTCBusLineHiV 1023;
BA_ "GenSigInvalidValue" SG_ 547 FrntPTCBusLineHiV 1023;
BA_ "GenSigSendType" SG_ 550 RLS_LIN_Resp_Err 3;
BA_ "GenSigRoutingTimeoutValue" SG_ 550 RLS_LIN_Resp_Err 1;
BA_ "GenSigRoutingTimeoutValue_String" SG_ 550 RLS_LIN_Resp_Err "0x1";
BA_ "GenSigSendType" SG_ 550 RLS_LightSnrErr 3;
BA_ "GenSigSendType" SG_ 550 RLS_RainSnrErr 3;
BA_ "GenSigSendType" SG_ 550 CSW_resp_error 3;
BA_ "GenSigRoutingTimeoutValue" SG_ 550 CSW_resp_error 1;
BA_ "GenSigRoutingTimeoutValue_String" SG_ 550 CSW_resp_error "0x1";
BA_ "GenSigSendType" SG_ 550 RLS_Lamp_Sta 3;
BA_ "GenSigRoutingTimeoutValue_String" SG_ 550 RLS_Lamp_Sta "0x0";
BA_ "GenSigSendType" SG_ 550 RLS_RainSnrWiperCmd 3;
BA_ "GenSigSendType" SG_ 550 CSW_FWipSw_Sta 3;
BA_ "GenSigRoutingTimeoutValue" SG_ 550 CSW_FWipSw_Sta 7;
BA_ "GenSigRoutingTimeoutValue_String" SG_ 550 CSW_FWipSw_Sta "0x7";
BA_ "GenSigInvalidValue" SG_ 550 CSW_FWipSw_Sta 7;
BA_ "GenSigSendType" SG_ 550 CSW_TurnSw_Sta 3;
BA_ "GenSigRoutingTimeoutValue" SG_ 550 CSW_TurnSw_Sta 3;
BA_ "GenSigRoutingTimeoutValue_String" SG_ 550 CSW_TurnSw_Sta "0x3";
BA_ "GenSigInvalidValue" SG_ 550 CSW_TurnSw_Sta 3;
BA_ "GenSigSendType" SG_ 550 CSW_RWasSW_Sta 3;
BA_ "GenSigRoutingTimeoutValue" SG_ 550 CSW_RWasSW_Sta 3;
BA_ "GenSigRoutingTimeoutValue_String" SG_ 550 CSW_RWasSW_Sta "0x3";
BA_ "GenSigInvalidValue" SG_ 550 CSW_RWasSW_Sta 3;
BA_ "GenSigSendType" SG_ 550 CSW_FWasSw_Sta 3;
BA_ "GenSigRoutingTimeoutValue" SG_ 550 CSW_FWasSw_Sta 3;
BA_ "GenSigRoutingTimeoutValue_String" SG_ 550 CSW_FWasSw_Sta "0x3";
BA_ "GenSigInvalidValue" SG_ 550 CSW_FWasSw_Sta 3;
BA_ "GenSigSendType" SG_ 550 CSW_PassSW_Sta 3;
BA_ "GenSigRoutingTimeoutValue_String" SG_ 550 CSW_PassSW_Sta "0x0";
BA_ "GenSigSendType" SG_ 550 CSW_DimSw 3;
BA_ "GenSigRoutingTimeoutValue_String" SG_ 550 CSW_DimSw "0x0";
BA_ "GenSigSendType" SG_ 550 CSW_RWipIntSw_Sta 3;
BA_ "GenSigRoutingTimeoutValue" SG_ 550 CSW_RWipIntSw_Sta 3;
BA_ "GenSigRoutingTimeoutValue_String" SG_ 550 CSW_RWipIntSw_Sta "0x3";
BA_ "GenSigInvalidValue" SG_ 550 CSW_RWipIntSw_Sta 3;
BA_ "GenSigRoutingTimeoutValue_String" SG_ 550 CSW_HW_version "0x0";
BA_ "GenSigRoutingTimeoutValue_String" SG_ 550 CSW_SW_version "0x0";
BA_ "GenSigSendType" SG_ 550 SWC_Drivemode_Sta 3;
BA_ "GenSigSendType" SG_ 550 SWC_CANCEL_Sta 3;
BA_ "GenSigRoutingTimeoutValue_String" SG_ 550 SWC_CANCEL_Sta "0x0";
BA_ "GenSigSendType" SG_ 550 SWC_ACC_Sta 3;
BA_ "GenSigRoutingTimeoutValue_String" SG_ 550 SWC_ACC_Sta "0x0";
BA_ "GenSigSendType" SG_ 550 SWC_A_Resp_Err 3;
BA_ "GenSigRoutingTimeoutValue" SG_ 550 SWC_A_Resp_Err 1;
BA_ "GenSigRoutingTimeoutValue_String" SG_ 550 SWC_A_Resp_Err "0x1";
BA_ "GenSigSendType" SG_ 550 SWC_Distance_Sta 3;
BA_ "GenSigSendType" SG_ 550 SWC_Down_Sta 3;
BA_ "GenSigRoutingTimeoutValue_String" SG_ 550 SWC_Down_Sta "0x0";
BA_ "GenSigSendType" SG_ 550 SWC_RegenUp 3;
BA_ "GenSigRoutingTimeoutValue_String" SG_ 550 SWC_RegenUp "0x0";
BA_ "GenSigSendType" SG_ 550 SWC_Left_Sta 3;
BA_ "GenSigRoutingTimeoutValue_String" SG_ 550 SWC_Left_Sta "0x0";
BA_ "GenSigSendType" SG_ 550 SWC_mode_Sta 3;
BA_ "GenSigRoutingTimeoutValue_String" SG_ 550 SWC_mode_Sta "0x0";
BA_ "GenSigSendType" SG_ 550 SWC_resp_error 3;
BA_ "GenSigSendType" SG_ 550 SWC_Res_Up_Sta 3;
BA_ "GenSigRoutingTimeoutValue_String" SG_ 550 SWC_Res_Up_Sta "0x0";
BA_ "GenSigSendType" SG_ 550 SWC_RegenDown 3;
BA_ "GenSigRoutingTimeoutValue_String" SG_ 550 SWC_RegenDown "0x0";
BA_ "GenSigSendType" SG_ 550 SWC_Right_Sta 3;
BA_ "GenSigRoutingTimeoutValue_String" SG_ 550 SWC_Right_Sta "0x0";
BA_ "GenSigSendType" SG_ 550 SWC_Set_down_Sta 3;
BA_ "GenSigRoutingTimeoutValue_String" SG_ 550 SWC_Set_down_Sta "0x0";
BA_ "GenSigSendType" SG_ 550 SWC_Trip_Sta 3;
BA_ "GenSigRoutingTimeoutValue_String" SG_ 550 SWC_Trip_Sta "0x0";
BA_ "GenSigSendType" SG_ 550 SWC_Up_Sta 3;
BA_ "GenSigRoutingTimeoutValue_String" SG_ 550 SWC_Up_Sta "0x0";
BA_ "GenSigSendType" SG_ 550 SWC_VR_Sta 3;
BA_ "GenSigRoutingTimeoutValue_String" SG_ 550 SWC_VR_Sta "0x0";
BA_ "GenSigSendType" SG_ 550 SWC_Undefined_Sta 3;
BA_ "GenSigRoutingTimeoutValue_String" SG_ 550 SWC_Undefined_Sta "0x0";
BA_ "GenSigSendType" SG_ 550 SWC_LKA_Sta 3;
BA_ "GenSigRoutingTimeoutValue_String" SG_ 550 SWC_LKA_Sta "0x0";
BA_ "GenSigSendType" SG_ 550 L_Pas_Wdw_Obs_InhibitSts 3;
BA_ "GenSigSendType" SG_ 550 L_Drv_Wdw_RRD_Switch 3;
BA_ "GenSigSendType" SG_ 550 L_Drv_Wdw_RLD_Switch 3;
BA_ "GenSigSendType" SG_ 550 L_Pas_Wdw_OD_Sts 3;
BA_ "GenSigSendType" SG_ 550 L_Pas_Wdw_Init 3;
BA_ "GenSigSendType" SG_ 550 L_Pas_OverHeat_Protect 3;
BA_ "GenSigSendType" SG_ 550 L_Pas_Motor_Relay_Error 3;
BA_ "GenSigRoutingTimeoutValue_String" SG_ 550 L_Pas_Motor_Relay_Error "0x0";
BA_ "GenSigSendType" SG_ 550 L_Pas_Motor_Ripple_Error 3;
BA_ "GenSigRoutingTimeoutValue_String" SG_ 550 L_Pas_Motor_Ripple_Error "0x0";
BA_ "GenSigSendType" SG_ 550 L_Drv_Wdw_Pas_Switch 3;
BA_ "GenSigRoutingTimeoutValue" SG_ 550 L_Pas_Val_Wdw_Opened 127;
BA_ "GenSigInactiveValue" SG_ 550 L_Pas_Val_Wdw_Opened 127;
BA_ "GenSigRoutingTimeoutValue_String" SG_ 550 L_Pas_Val_Wdw_Opened "0x7F";
BA_ "GenSigStartValue" SG_ 550 L_Pas_Val_Wdw_Opened 127;
BA_ "GenSigInvalidValue" SG_ 550 L_Pas_Val_Wdw_Opened 127;
BA_ "GenSigSendType" SG_ 550 L_Pas_Wdw_PositionSts 3;
BA_ "GenSigRoutingTimeoutValue" SG_ 550 L_Pas_Wdw_PositionSts 3;
BA_ "GenSigInactiveValue" SG_ 550 L_Pas_Wdw_PositionSts 3;
BA_ "GenSigRoutingTimeoutValue_String" SG_ 550 L_Pas_Wdw_PositionSts "0x3";
BA_ "GenSigStartValue" SG_ 550 L_Pas_Wdw_PositionSts 3;
BA_ "GenSigInvalidValue" SG_ 550 L_Pas_Wdw_PositionSts 3;
BA_ "GenSigSendType" SG_ 550 L_Pas_Wdw_LocalSwitch 3;
BA_ "GenSigSendType" SG_ 550 L_Pas_Wdw_Running_Sts 3;
BA_ "GenSigSendType" SG_ 550 L_Power_Status 3;
BA_ "GenSigSendType" SG_ 550 FAPWL_01_LIN_Response_Error 3;
BA_ "GenSigRoutingTimeoutValue" SG_ 550 FAPWL_01_LIN_Response_Error 1;
BA_ "GenSigRoutingTimeoutValue_String" SG_ 550 FAPWL_01_LIN_Response_Error "0x1";
BA_ "GenSigSendType" SG_ 550 L_Drv_Wdw_Obs_InhibitSts 3;
BA_ "GenSigSendType" SG_ 550 L_Drv_Wdw_OD_Sts 3;
BA_ "GenSigSendType" SG_ 550 L_Drv_Wdw_Init 3;
BA_ "GenSigSendType" SG_ 550 L_Drv_OverHeat_Protect 3;
BA_ "GenSigSendType" SG_ 550 L_Drv_Motor_Relay_Error 3;
BA_ "GenSigRoutingTimeoutValue_String" SG_ 550 L_Drv_Motor_Relay_Error "0x0";
BA_ "GenSigSendType" SG_ 550 L_Drv_Motor_Ripple_Error 3;
BA_ "GenSigRoutingTimeoutValue_String" SG_ 550 L_Drv_Motor_Ripple_Error "0x0";
BA_ "GenSigRoutingTimeoutValue" SG_ 550 L_Drv_Val_Wdw_Opened 127;
BA_ "GenSigInactiveValue" SG_ 550 L_Drv_Val_Wdw_Opened 127;
BA_ "GenSigRoutingTimeoutValue_String" SG_ 550 L_Drv_Val_Wdw_Opened "0x7F";
BA_ "GenSigStartValue" SG_ 550 L_Drv_Val_Wdw_Opened 127;
BA_ "GenSigInvalidValue" SG_ 550 L_Drv_Val_Wdw_Opened 127;
BA_ "GenSigSendType" SG_ 550 L_Drv_Wdw_PositionSts 3;
BA_ "GenSigRoutingTimeoutValue" SG_ 550 L_Drv_Wdw_PositionSts 3;
BA_ "GenSigInactiveValue" SG_ 550 L_Drv_Wdw_PositionSts 3;
BA_ "GenSigRoutingTimeoutValue_String" SG_ 550 L_Drv_Wdw_PositionSts "0x3";
BA_ "GenSigStartValue" SG_ 550 L_Drv_Wdw_PositionSts 3;
BA_ "GenSigInvalidValue" SG_ 550 L_Drv_Wdw_PositionSts 3;
BA_ "GenSigSendType" SG_ 550 L_Drv_Wdw_LocalSwitch 3;
BA_ "GenSigSendType" SG_ 550 L_Drv_Wdw_Running_Sts 3;
BA_ "GenSigSendType" SG_ 550 L_RLD_Wdw_Init 3;
BA_ "GenSigRoutingTimeoutValue" SG_ 550 L_RRD_Val_Wdw_Opened 127;
BA_ "GenSigInactiveValue" SG_ 550 L_RRD_Val_Wdw_Opened 127;
BA_ "GenSigRoutingTimeoutValue_String" SG_ 550 L_RRD_Val_Wdw_Opened "0x7F";
BA_ "GenSigStartValue" SG_ 550 L_RRD_Val_Wdw_Opened 127;
BA_ "GenSigInvalidValue" SG_ 550 L_RRD_Val_Wdw_Opened 127;
BA_ "GenSigSendType" SG_ 550 L_RRD_Wdw_PositionSts 3;
BA_ "GenSigRoutingTimeoutValue" SG_ 550 L_RRD_Wdw_PositionSts 3;
BA_ "GenSigInactiveValue" SG_ 550 L_RRD_Wdw_PositionSts 3;
BA_ "GenSigRoutingTimeoutValue_String" SG_ 550 L_RRD_Wdw_PositionSts "0x3";
BA_ "GenSigStartValue" SG_ 550 L_RRD_Wdw_PositionSts 3;
BA_ "GenSigInvalidValue" SG_ 550 L_RRD_Wdw_PositionSts 3;
BA_ "GenSigSendType" SG_ 550 L_RRD_Wdw_Obs_InhibitSts 3;
BA_ "GenSigSendType" SG_ 550 L_RRD_Wdw_OD_Sts 3;
BA_ "GenSigSendType" SG_ 550 L_RRD_Wdw_Init 3;
BA_ "GenSigSendType" SG_ 550 L_RRD_OverHeat_Protect 3;
BA_ "GenSigSendType" SG_ 550 L_RRD_Motor_Relay_Error 3;
BA_ "GenSigRoutingTimeoutValue_String" SG_ 550 L_RRD_Motor_Relay_Error "0x0";
BA_ "GenSigSendType" SG_ 550 L_RRD_Motor_Ripple_Error 3;
BA_ "GenSigRoutingTimeoutValue_String" SG_ 550 L_RRD_Motor_Ripple_Error "0x0";
BA_ "GenSigSendType" SG_ 550 L_RRD_Wdw_LocalSwitch 3;
BA_ "GenSigSendType" SG_ 550 L_RRD_Wdw_Running_Sts 3;
BA_ "GenSigSendType" SG_ 550 RAPWL_01_LIN_Response_Error 3;
BA_ "GenSigRoutingTimeoutValue" SG_ 550 RAPWL_01_LIN_Response_Error 1;
BA_ "GenSigRoutingTimeoutValue_String" SG_ 550 RAPWL_01_LIN_Response_Error "0x1";
BA_ "GenSigSendType" SG_ 550 L_RLD_Wdw_Obs_InhibitSts 3;
BA_ "GenSigSendType" SG_ 550 L_RLD_Wdw_OD_Sts 3;
BA_ "GenSigRoutingTimeoutValue" SG_ 550 L_RLD_Val_Wdw_Opened 127;
BA_ "GenSigInactiveValue" SG_ 550 L_RLD_Val_Wdw_Opened 127;
BA_ "GenSigRoutingTimeoutValue_String" SG_ 550 L_RLD_Val_Wdw_Opened "0x7F";
BA_ "GenSigStartValue" SG_ 550 L_RLD_Val_Wdw_Opened 127;
BA_ "GenSigInvalidValue" SG_ 550 L_RLD_Val_Wdw_Opened 127;
BA_ "GenSigSendType" SG_ 550 L_RLD_OverHeat_Protect 3;
BA_ "GenSigSendType" SG_ 550 L_RLD_Motor_Relay_Error 3;
BA_ "GenSigRoutingTimeoutValue_String" SG_ 550 L_RLD_Motor_Relay_Error "0x0";
BA_ "GenSigSendType" SG_ 550 L_RLD_Motor_Ripple_Error 3;
BA_ "GenSigRoutingTimeoutValue_String" SG_ 550 L_RLD_Motor_Ripple_Error "0x0";
BA_ "GenSigSendType" SG_ 550 L_RLD_Wdw_PositionSts 3;
BA_ "GenSigRoutingTimeoutValue" SG_ 550 L_RLD_Wdw_PositionSts 3;
BA_ "GenSigInactiveValue" SG_ 550 L_RLD_Wdw_PositionSts 3;
BA_ "GenSigRoutingTimeoutValue_String" SG_ 550 L_RLD_Wdw_PositionSts "0x3";
BA_ "GenSigStartValue" SG_ 550 L_RLD_Wdw_PositionSts 3;
BA_ "GenSigInvalidValue" SG_ 550 L_RLD_Wdw_PositionSts 3;
BA_ "GenSigSendType" SG_ 550 L_RLD_Wdw_LocalSwitch 3;
BA_ "GenSigSendType" SG_ 550 L_RLD_Wdw_Running_Sts 3;
BA_ "GenSigSendType" SG_ 550 SWC2_R_Right_Sta 3;
BA_ "GenSigRoutingTimeoutValue_String" SG_ 550 SWC2_R_Right_Sta "0x0";
BA_ "GenSigSendType" SG_ 550 SWC2_R_ScrollUp_Sta 3;
BA_ "GenSigRoutingTimeoutValue_String" SG_ 550 SWC2_R_ScrollUp_Sta "0x0";
BA_ "GenSigSendType" SG_ 550 SWC2_R_ScrollPress_Sta 3;
BA_ "GenSigRoutingTimeoutValue_String" SG_ 550 SWC2_R_ScrollPress_Sta "0x0";
BA_ "GenSigSendType" SG_ 550 SWC2_R_ScrollDown_Sta 3;
BA_ "GenSigRoutingTimeoutValue_String" SG_ 550 SWC2_R_ScrollDown_Sta "0x0";
BA_ "GenSigSendType" SG_ 550 SWC2_R_Left_Sta 3;
BA_ "GenSigRoutingTimeoutValue_String" SG_ 550 SWC2_R_Left_Sta "0x0";
BA_ "GenSigSendType" SG_ 550 SWC2_R_VR_Sta 3;
BA_ "GenSigRoutingTimeoutValue_String" SG_ 550 SWC2_R_VR_Sta "0x0";
BA_ "GenSigSendType" SG_ 550 SWC2_R_PageSwitch_Sta 3;
BA_ "GenSigRoutingTimeoutValue_String" SG_ 550 SWC2_R_PageSwitch_Sta "0x0";
BA_ "GenSigSendType" SG_ 550 SWC2_R_Customize_Sta 3;
BA_ "GenSigRoutingTimeoutValue_String" SG_ 550 SWC2_R_Customize_Sta "0x0";
BA_ "GenSigSendType" SG_ 550 SWC2_L_Left_Sta 3;
BA_ "GenSigSendType" SG_ 550 SWC2_L_ScrollUp_Sta 3;
BA_ "GenSigSendType" SG_ 550 SWC2_L_ScrollPress_Sta 3;
BA_ "GenSigSendType" SG_ 550 SWC2_L_ScrollDown_Sta 3;
BA_ "GenSigSendType" SG_ 550 SWC2_L_Right_Sta 3;
BA_ "GenSigSendType" SG_ 550 SWC2_L_RegenUp_Sta 3;
BA_ "GenSigSendType" SG_ 550 SWC2_L_ADAS_Sta 3;
BA_ "GenSigSendType" SG_ 550 SWC2_L_Home_Sta 3;
BA_ "GenSigRoutingTimeoutValue_String" SG_ 550 SWC2_L_Home_Sta "0x0";
BA_ "GenSigSendType" SG_ 550 SWC2_ResponseError 3;
BA_ "GenSigRoutingTimeoutValue" SG_ 550 SWC2_ResponseError 1;
BA_ "GenSigRoutingTimeoutValue_String" SG_ 550 SWC2_ResponseError "0x1";
BA_ "GenSigSendType" SG_ 550 SWC2_R_RegenDown_Sta 3;
BA_ "GenSigSendType" SG_ 550 SWC2_L_DriveMode_Sta 3;
BA_ "GenSigRoutingTimeoutValue_String" SG_ 550 SWC2_L_DriveMode_Sta "0x0";
BA_ "SystemSignalLongSymbol" SG_ 805 ACT5_Select_position_specificati "ACT5_Select_position_specification";
BA_ "SystemSignalLongSymbol" SG_ 805 ACT4_Select_position_specificati "ACT4_Select_position_specification";
BA_ "SystemSignalLongSymbol" SG_ 805 ACT3_Select_position_specificati "ACT3_Select_position_specification";
BA_ "SystemSignalLongSymbol" SG_ 805 ACT2_Select_position_specificati "ACT2_Select_position_specification";
BA_ "SystemSignalLongSymbol" SG_ 805 ACT1_Select_position_specificati "ACT1_Select_position_specification";
BA_ "GenSigSendType" SG_ 805 HornSW 3;
BA_ "GenSigSendType" SG_ 805 AllLockSta 3;
BA_ "GenSigSendType" SG_ 805 AutoLightSW 3;
BA_ "GenSigSendType" SG_ 805 BrakeLampFail 3;
BA_ "GenSigSendType" SG_ 805 DrLockSta 3;
BA_ "GenSigSendType" SG_ 805 WiperSWPos 3;
BA_ "GenSigRoutingTimeoutValue" SG_ 805 WiperSWPos 255;
BA_ "GenSigInactiveValue" SG_ 805 WiperSWPos 255;
BA_ "GenSigRoutingTimeoutValue_String" SG_ 805 WiperSWPos "0xFF";
BA_ "GenSigStartValue" SG_ 805 WiperSWPos 255;
BA_ "GenSigInvalidValue" SG_ 805 WiperSWPos 255;
BA_ "GenSigSendType" SG_ 805 RRTurnLampC 3;
BA_ "GenSigRoutingTimeoutValue" SG_ 805 RRTurnLampC 255;
BA_ "GenSigInactiveValue" SG_ 805 RRTurnLampC 255;
BA_ "GenSigRoutingTimeoutValue_String" SG_ 805 RRTurnLampC "0xFF";
BA_ "GenSigStartValue" SG_ 805 RRTurnLampC 255;
BA_ "GenSigInvalidValue" SG_ 805 RRTurnLampC 255;
BA_ "GenSigSendType" SG_ 805 RLTurnLampC 3;
BA_ "GenSigRoutingTimeoutValue" SG_ 805 RLTurnLampC 255;
BA_ "GenSigInactiveValue" SG_ 805 RLTurnLampC 255;
BA_ "GenSigRoutingTimeoutValue_String" SG_ 805 RLTurnLampC "0xFF";
BA_ "GenSigStartValue" SG_ 805 RLTurnLampC 255;
BA_ "GenSigInvalidValue" SG_ 805 RLTurnLampC 255;
BA_ "GenSigSendType" SG_ 805 Wip_Speed 3;
BA_ "GenSigSendType" SG_ 805 MIRROR_FOLD_SW 3;
BA_ "GenSigSendType" SG_ 805 PsLockSta 3;
BA_ "GenSigSendType" SG_ 805 RLLockSta 3;
BA_ "GenSigSendType" SG_ 805 RLS_Exist 3;
BA_ "GenSigSendType" SG_ 805 RRLockSta 3;
BA_ "GenSigSendType" SG_ 805 RWiperAS 3;
BA_ "GenSigSendType" SG_ 805 RWiperProtection 3;
BA_ "GenSigSendType" SG_ 805 WiperZeroPosSW 3;
BA_ "GenSigSendType" SG_ 805 RLTurnLPErr 3;
BA_ "GenSigSendType" SG_ 805 RRTurnLPErr 3;
BA_ "GenSigRoutingTimeoutValue" SG_ 805 RRTurnLPErr 1;
BA_ "GenSigRoutingTimeoutValue_String" SG_ 805 RRTurnLPErr "0x1";
BA_ "GenSigSendType" SG_ 805 ZDR_THCM_IntakeFail_Sta 3;
BA_ "GenSigSendType" SG_ 805 ZDR_THCM_LINACT1_Sta 3;
BA_ "GenSigSendType" SG_ 805 ZDR_THCM_LINACT2_Sta 3;
BA_ "GenSigSendType" SG_ 805 ZDR_THCM_LINACT3_Sta 3;
BA_ "GenSigSendType" SG_ 805 ZDR_THCM_LINACT4_Sta 3;
BA_ "GenSigSendType" SG_ 805 ZDR_THCM_LINACT5_Sta 3;
BA_ "GenSigSendType" SG_ 805 ZDR_THCM_ModeFail_Sta 3;
VAL_ 278 Dr_SeatSta 2 "Invalid" 1 "Seat occupied" 0 "Seat empty" ;
VAL_ 278 MSA_Crl_Sta 7 "Pedal Override" 6 "Invalid" 5 "Error" 4 "Over Speed" 3 "Under Speed" 2 "Active" 1 "Standby" 0 "Off" ;
VAL_ 278 CC_Crl_Sta 7 "Pedal Override" 6 "Invalid" 5 "Error" 4 "Over Speed" 3 "Under Speed" 2 "Active" 1 "Standby" 0 "Off" ;
VAL_ 278 ShiftGearPosn 7 "Reverse" 6 "Failure" 5 "Drive" 4 "Neutral" 3 "Not used" 2 "Not used" 1 "Invalid" 0 "Park" ;
VAL_ 278 PwrSta 7 "Invalid" 5 "READY" 4 "ON" 3 "STANDBY" 2 "OFF-After-Run" 1 "OFF-Charging" 0 "OFF" ;
VAL_ 278 ReBrakeLPReq 1 "On" 0 "Off" ;
VAL_ 278 EquivAccPedalSWSta 1 "On" 0 "Off" ;
VAL_ 278 HornCtrl 1 "ON" 0 "OFF" ;
VAL_ 278 BCM_DoorLock_Sta 1 "Lock" 0 "Unlock" ;
VAL_ 278 DimmerEN 1 "Enable" 0 "Disable" ;
VAL_ 278 RoomLampH 1 "ON" 0 "OFF" ;
VAL_ 278 RoomLampL 1 "ON" 0 "OFF" ;
VAL_ 278 TailgateRemote 3 "Invalid" 2 "Handle Request" 1 "Remote Request" 0 "No Request" ;
VAL_ 278 LockSetting 1 "Unlock Single Door" 0 "Unlock All Door" ;
VAL_ 278 L_APM_WdwEnable 1 "Normal" 0 "Inhibit" ;
VAL_ 278 CrashDetd 1 "Crash detected" 0 "Crash not detected" ;
VAL_ 278 AntiTheftSeatFold 1 "Fold" 0 "No Request" ;
VAL_ 278 AntitheftSta 3 "Alarm Status" 2 "Wait for Rearm Status" 1 "Arm Status" 0 "Disarm Status" ;
VAL_ 278 RTurnLP 1 "On" 0 "Off" ;
VAL_ 278 LTurnLP 1 "On" 0 "Off" ;
VAL_ 278 HazardSW 1 "On" 0 "Off" ;
VAL_ 278 Rr_FogLamp 1 "On" 0 "Off" ;
VAL_ 278 Fr_FogLamp 1 "On" 0 "Off" ;
VAL_ 278 RBSD 1 "On" 0 "Off" ;
VAL_ 278 LBSD 1 "On" 0 "Off" ;
VAL_ 278 BrakeLamp 1 "On" 0 "Off" ;
VAL_ 278 ReverseLamp 1 "On" 0 "Off" ;
VAL_ 278 RDRL 1 "On" 0 "Off" ;
VAL_ 278 LDRL 1 "On" 0 "Off" ;
VAL_ 278 PosLamp 1 "On" 0 "Off" ;
VAL_ 278 H_Beam 1 "On" 0 "Off" ;
VAL_ 278 L_Beam 1 "On" 0 "Off" ;
VAL_ 278 WasherCtrl 3 "Undefined" 2 "Rear Washer" 1 "Front Washer" 0 "No Command" ;
VAL_ 278 WiperFixMode 1 "On" 0 "Off" ;
VAL_ 278 Rr_Wiper 1 "On" 0 "Off" ;
VAL_ 278 Fr_Wiper_L 1 "On" 0 "Off" ;
VAL_ 278 Fr_Wiper_H 1 "On" 0 "Off" ;
VAL_ 278 MirrorCtrl 3 "Undefined" 2 "Unfold" 1 "Fold" 0 "No Command" ;
VAL_ 278 TailgateHDSW 1 "Press" 0 "Release" ;
VAL_ 278 TrunkRel 1 "Release" 0 "Off" ;
VAL_ 278 Rr_Defog 1 "On" 0 "Off" ;
VAL_ 278 Fr_ChargingDoorCtrl 3 "Undefined" 2 "Lock" 1 "Unlock" 0 "No Command" ;
VAL_ 278 HoodSW 1 "Open" 0 "Close" ;
VAL_ 278 DoorLockIND 1 "On" 0 "Off" ;
VAL_ 278 AllDoorSW 1 "Any Door Open" 0 "Close" ;
VAL_ 278 RRDoorSW 1 "Open" 0 "Close" ;
VAL_ 278 RLDoorSW 1 "Open" 0 "Close" ;
VAL_ 278 PsDoorSW 1 "Open" 0 "Close" ;
VAL_ 278 Rr_ChargingDoorCtrl 3 "Undefined" 2 "Lock" 1 "Unlock" 0 "No Command" ;
VAL_ 278 CTDCtrl 3 "Lock All Door" 2 "Unlock All Door" 1 "Unlock Driver Door" 0 "No Command" ;
VAL_ 278 FD_TBOX_VehData_Sta 2 "Upload" 1 "Pack" 0 "Idle" ;
VAL_ 278 FD_TBOX_VehData_Err 2 "Upload error" 1 "Pack error" 0 "No error" ;
VAL_ 278 FD_DKC_VehData_Sta 2 "Upload" 1 "Pack" 0 "Idle" ;
VAL_ 278 FD_DKC_VehData_Err 2 "Upload error" 1 "Pack error" 0 "No error" ;
VAL_ 278 FD_TBOX_DTCData_Sta 2 "Upload" 1 "Pack" 0 "Idle" ;
VAL_ 278 FD_TBOX_DTCData_Err 2 "Upload error" 1 "Pack error" 0 "No error" ;
VAL_ 278 LampPwr 1 "ON" 0 "OFF" ;
VAL_ 278 DKCAuthSta 3 "invalid" 2 "Time S/N compare error" 1 "Decryption fail" 0 "Normal" ;
VAL_ 278 MirrorDefog 1 "On" 0 "Off" ;
VAL_ 278 DrDoorSW 1 "Open" 0 "Close" ;
VAL_ 278 CTDLockSW 1 "Press" 0 "Release" ;
VAL_ 278 CTDUnlockSW 1 "Press" 0 "Release" ;
VAL_ 278 Tailgate_SW 1 "Open" 0 "Close" ;
VAL_ 278 HWResetSta 3 "Reserved" 2 "Hardware reset finish" 1 "Hardware resetting" 0 "No reset" ;
VAL_ 278 CtrlFrBMSCCUCIR 1 "Request power off" 0 "No request" ;
VAL_ 278 CtrlFrEDUINVERTER 1 "Request power off" 0 "No request" ;
VAL_ 278 CtrlFrIRC1 1 "Request power off" 0 "No request" ;
VAL_ 278 CtrlFrPwrStbA1P 1 "Request power off" 0 "No request" ;
VAL_ 278 CtrlDrPwrStbA2 1 "Request power off" 0 "No request" ;
VAL_ 278 H_Beam_ADB 1 "ON" 0 "OFF" ;
VAL_ 278 APS_Sta_System 4 "Remote Actived" 3 "Failed" 2 "Active" 1 "Enable" 0 "Disable" ;
VAL_ 386 CCU_HEATMaxLampSts 1 "Lamp ON" 0 "Lamp OFF" ;
VAL_ 386 CCU_ACLampSts 1 "Lamp ON" 0 "Lamp OFF" ;
VAL_ 386 CCU_EcoSts 1 "Lamp ON" 0 "Lamp OFF" ;
VAL_ 386 CCU_AutoMidLampSts 1 "Lamp ON" 0 "Lamp OFF" ;
VAL_ 386 CCU_AutoLampSts 1 "Lamp ON" 0 "Lamp OFF" ;
VAL_ 386 CCU_ACMaxLampSts 1 "Lamp ON" 0 "Lamp OFF" ;
VAL_ 386 CCU_RrOnOffLampSts 1 "Lamp ON" 0 "Lamp OFF" ;
VAL_ 386 CCU_FrtOnOffLampSts 1 "Lamp ON" 0 "Lamp OFF" ;
VAL_ 386 CCU_SyncLampSts 1 "Lamp ON" 0 "Lamp OFF" ;
VAL_ 386 HPThermalRecoveryReq 1 "Request" 0 "Not Request" ;
VAL_ 386 EDriveMode 2 "Waste Heat Recovery" 1 "Cooling" 0 "OFF" ;
VAL_ 386 FD_RecyAuto_Cmd 7 "Invalid" 6 "reserved" 5 "reserved" 4 "100% out recycle" 3 "70% out recycle" 2 "50% out recycle" 1 "30% out recycle" 0 "0% out recycle" ;
VAL_ 386 BatteryMode 5 "Active Heating" 4 "Passive Heating" 3 "Isothermal Cycle" 2 "Passive Cooling" 1 "Active Cooling" 0 "OFF" ;
VAL_ 386 CabinMode 15 "Invalid" 11 "Reserved" 10 "Cabin Deice Mode" 9 "Cabin Heating Mode 2" 8 "Cabin Heating Mode 1" 7 "Cabin Dehumidity Mode 4" 6 "Cabin Dehumidity Mode 3" 5 "Cabin Dehumidity Mode 2" 4 "Cabin Dehumidity Mode 1" 3 "Mode 1" 2 "Comp On" 1 "Comp Off" 0 "OFF" ;
VAL_ 386 FD_SOV3_Cmd 1 "Close" 0 "Open" ;
VAL_ 386 FD_SOV2_Cmd 1 "Close" 0 "Open" ;
VAL_ 386 FD_SOV1_Cmd 1 "Close" 0 "Open" ;
VAL_ 386 FD_SOTXV_Cmd 1 "Close" 0 "Open" ;
VAL_ 386 FD_FWV_Cmd 1 "Open Port 1 to Port 4, Port 2 to port 3" 0 "Open Port 1 to Port 2, Port 3 to port 4" ;
VAL_ 386 CCU_HiVoltageReq 1 "High Voltage Request" 0 "High Voltage not Request" ;
VAL_ 386 CCU_CbnPreSts 3 "Reserved" 2 "Calculate Estimated Time Status" 1 "ON" 0 "OFF" ;
VAL_ 386 DeiceModReq 1 "Request" 0 "Not Request" ;
VAL_ 386 CCU_CbnPreACWkSts 3 "Fail" 2 "Success" 1 "Init" 0 "No Request" ;
VAL_ 386 CCU_CbnPreEstimdTi 63 "Invalid" 62 "Reserved" 61 "Reserved" 60 "Normal" 0 "Normal" ;
VAL_ 386 FD_FrRiAPTCHeatPwr_Cmd 255 "Invalid" 201 "~0xFE Reserved" 0 "~ 0xC8 actual value" ;
VAL_ 386 FD_FrLeAPTCHeatPwr_Cmd 255 "Invalid" 201 "~0xFE Reserved" 0 "~ 0xC8 actual value" ;
VAL_ 386 FD_RrAPTCHeatPwr_Cmd 255 "Invalid" 201 "~ 0xFE Reserved" 0 "~0xC8 actual value" ;
VAL_ 386 FD_EWP3_Cmd 255 "Invalid" 250 "Maxmum Speed" 50 "Minmum Speed" 0 "Stop" ;
VAL_ 386 FD_EWP2_Cmd 255 "Invalid" 250 "Maxmum Speed" 50 "Minmum Speed" 0 "Stop" ;
VAL_ 386 FD_EWP1_Cmd 255 "Invalid" 250 "Maxmum Speed" 50 "Minmum Speed" 0 "Stop" ;
VAL_ 386 sigRecircSt 1 "ON" 0 "OFF" ;
VAL_ 386 sigWindDirZon1St 7 "NOT Set / Reserved" 6 "All open" 5 "Face + Screen" 4 "DEFOG" 3 "Foot + Screen" 2 "Foot" 1 "Bilevel" 0 "FACE" ;
VAL_ 386 sigHvacSt 1 "ON" 0 "OFF" ;
VAL_ 386 sigWindDirZon3St 7 "NOT Set / Reserved" 6 "All open" 5 "Face + Screen" 4 "DEFOG" 3 "Foot + Screen" 2 "Foot" 1 "Bilevel" 0 "FACE" ;
VAL_ 386 ACSubMode 7 "mode 7" 6 "mode 6" 5 "Mode 5" 4 "Mode 4" 3 "Mode 3" 2 "Mode 2" 1 "Mode 1" 0 "OFF" ;
VAL_ 386 FDC_THCM_CLEVentY_Sta 127 "Invalid" 126 "OFF" ;
VAL_ 386 sigAirIntenZon1St 15 "Invalid" 14 "Reserved" 11 "Reserved" 10 "NOT set" 9 "Level 8" 8 "Level 7" 7 "Level 6" 6 "Level 5" 5 "Level 4" 4 "Level 3" 3 "Level 2" 2 "Level 1" 1 "OFF" 0 "NO display / No request" ;
VAL_ 386 sigAirIntenZon3St 15 "Invalid" 14 "Reserved" 11 "Reserved" 10 "NOT set" 9 "Level 8" 8 "Level 7" 7 "Level 6" 6 "Level 5" 5 "Level 4" 4 "Level 3" 3 "Level 2" 2 "Level 1" 1 "OFF" 0 "NO display / No request" ;
VAL_ 386 sigDfrstSt 1 "ON" 0 "OFF" ;
VAL_ 386 FDC_THCM_CLEVentZ_Sta 127 "Invalid" 126 "OFF" ;
VAL_ 386 FDC_THCM_CLVent_Sta 1 "ON" 0 "OFF" ;
VAL_ 386 FDC_THCM_CREVentY_Sta 127 "Invalid" 126 "OFF" ;
VAL_ 386 FDC_THCM_CREVentZ_Sta 127 "Invalid" 126 "OFF" ;
VAL_ 386 FDC_THCM_CRVent_Sta 1 "ON" 0 "OFF" ;
VAL_ 386 FDC_THCM_DrEVentMode_Sta 3 "Balanced" 2 "Sweep" 1 "Manual" 0 "No Request" ;
VAL_ 386 FDC_THCM_DrEVentY_Sta 127 "Invalid" 126 "OFF" ;
VAL_ 386 FDC_THCM_DrEVentZ_Sta 127 "Invalid" 126 "OFF" ;
VAL_ 386 FDC_THCM_DrVent_Sta 1 "ON" 0 "OFF" ;
VAL_ 386 FDC_THCM_PsEVentMode_Sta 3 "Balanced" 2 "Sweep" 1 "Manual" 0 "No Request" ;
VAL_ 386 FDC_THCM_PsEVentY_Sta 127 "Invalid" 126 "OFF" ;
VAL_ 386 FDC_THCM_PsEVentZ_Sta 127 "Invalid" 126 "OFF" ;
VAL_ 386 FDC_THCM_PsVent_Sta 1 "ON" 0 "OFF" ;
VAL_ 535 FDLHandleLampCmd 1 "On" 0 "Off" ;
VAL_ 535 FDRHandleLampCmd 1 "On" 0 "Off" ;
VAL_ 535 AmbLightColor1 63 "Red(255,0,0)" 62 "IndianRed(205,92,92)" 61 "LightCoral(240,128,128)" 60 "Tomato(255,99,71)" 59 "OrangeRed(255,69,0)" 58 "Coral(255,127,80)" 57 "LightSalmon(255,160,122)" 56 "DarkOrange(255,140,0)" 55 "Bisque(255,228,196)" 54 "NavajoWhite(255,222,173)" 53 "BlanchedAlmond(255,235,205)" 52 "Gold(255,215,0)" 51 "LemonChiffon(255,250,205)" 50 "Yellow(255,255,0)" 49 "LightYellow(255,255,224)" 48 "Ivory(255,255,240)" 47 "LightGoldenrodYellow(250,250,210)" 46 "Beige(245,245,220)" 45 "GreenYellow(173,255,47)" 44 "Chartreuse(127,255,0)" 43 "Lime(0,255,0)" 42 "LimeGreen(50,205,50)" 41 "PaleGreen(152,251,152)" 40 "LightGreen(144,238,144)" 39 "SeaGreen(46,139,87)" 38 "SpringGreen(60,179,113)" 37 "MediumSpringGreen(0,255,127)" 36 "MediumAquamarine(0,250,154)" 35 "Auqamarin(127,255,170)" 34 "MediumTurquoise(72,209,204)" 33 "DarkCyan(0,139,139)" 32 "DarkTurquoise(0,206,209)" 31 "Cyan(0,255,255)" 30 "PaleTurquoise(175,238,238)" 29 "DeepSkyBlue(0,191,255)" 28 "SkyBlue(135,206,235)" 27 "LightSkyBlue(135,206,250)" 26 "DoderBlue(30,144,255)" 25 "CornflowerBlue(100,149,237)" 24 "RoyalBlue(65,105,225)" 23 "Navy(0,0,128)" 22 "DarkBlue(0,0,139)" 21 "MidnightBlue(25,25,112)" 20 "MediumBlue(0,0,205)" 19 "Blue(0,0,255)" 18 "DarkSlateBlue(72,61,139)" 17 "SlateBlue(106,90,205)" 16 "MediumSlateBlue(123,104,238)" 15 "MediumPurple(147,112,219)" 14 "BlueViolet(138,43,226)" 13 "Indigo(75,0,130)" 12 "DarkOrchid(153,50,204)" 11 "DarkVoilet(148,0,211)" 10 "MediumOrchid(186,85,211)" 9 "DarkMagenta(139,0,139)" 8 "Magenta(255,0,255)" 7 "Violet(238,130,238)" 6 "Orchid(218,112,214)" 5 "MediumVioletRed(199,21,133)" 4 "DeepPink(255,20,147)" 3 "HotPink(255,105,180)" 2 "PaleVioletRed(219,112,147)" 1 "Crimson(220,20,60)" 0 "LightPink(255,182,193)" ;
VAL_ 535 BCM_Buzzer_Req 1 "Request" 0 "No Request" ;
VAL_ 535 AmbLightColor2 63 "Red(255,0,0)" 62 "IndianRed(205,92,92)" 61 "LightCoral(240,128,128)" 60 "Tomato(255,99,71)" 59 "OrangeRed(255,69,0)" 58 "Coral(255,127,80)" 57 "LightSalmon(255,160,122)" 56 "DarkOrange(255,140,0)" 55 "Bisque(255,228,196)" 54 "NavajoWhite(255,222,173)" 53 "BlanchedAlmond(255,235,205)" 52 "Gold(255,215,0)" 51 "LemonChiffon(255,250,205)" 50 "Yellow(255,255,0)" 49 "LightYellow(255,255,224)" 48 "Ivory(255,255,240)" 47 "LightGoldenrodYellow(250,250,210)" 46 "Beige(245,245,220)" 45 "GreenYellow(173,255,47)" 44 "Chartreuse(127,255,0)" 43 "Lime(0,255,0)" 42 "LimeGreen(50,205,50)" 41 "PaleGreen(152,251,152)" 40 "LightGreen(144,238,144)" 39 "SeaGreen(46,139,87)" 38 "SpringGreen(60,179,113)" 37 "MediumSpringGreen(0,255,127)" 36 "MediumAquamarine(0,250,154)" 35 "Auqamarin(127,255,170)" 34 "MediumTurquoise(72,209,204)" 33 "DarkCyan(0,139,139)" 32 "DarkTurquoise(0,206,209)" 31 "Cyan(0,255,255)" 30 "PaleTurquoise(175,238,238)" 29 "DeepSkyBlue(0,191,255)" 28 "SkyBlue(135,206,235)" 27 "LightSkyBlue(135,206,250)" 26 "DoderBlue(30,144,255)" 25 "CornflowerBlue(100,149,237)" 24 "RoyalBlue(65,105,225)" 23 "Navy(0,0,128)" 22 "DarkBlue(0,0,139)" 21 "MidnightBlue(25,25,112)" 20 "MediumBlue(0,0,205)" 19 "Blue(0,0,255)" 18 "DarkSlateBlue(72,61,139)" 17 "SlateBlue(106,90,205)" 16 "MediumSlateBlue(123,104,238)" 15 "MediumPurple(147,112,219)" 14 "BlueViolet(138,43,226)" 13 "Indigo(75,0,130)" 12 "DarkOrchid(153,50,204)" 11 "DarkVoilet(148,0,211)" 10 "MediumOrchid(186,85,211)" 9 "DarkMagenta(139,0,139)" 8 "Magenta(255,0,255)" 7 "Violet(238,130,238)" 6 "Orchid(218,112,214)" 5 "MediumVioletRed(199,21,133)" 4 "DeepPink(255,20,147)" 3 "HotPink(255,105,180)" 2 "PaleVioletRed(219,112,147)" 1 "Crimson(220,20,60)" 0 "LightPink(255,182,193)" ;
VAL_ 535 AmbLightColor3 63 "Red(255,0,0)" 62 "IndianRed(205,92,92)" 61 "LightCoral(240,128,128)" 60 "Tomato(255,99,71)" 59 "OrangeRed(255,69,0)" 58 "Coral(255,127,80)" 57 "LightSalmon(255,160,122)" 56 "DarkOrange(255,140,0)" 55 "Bisque(255,228,196)" 54 "NavajoWhite(255,222,173)" 53 "BlanchedAlmond(255,235,205)" 52 "Gold(255,215,0)" 51 "LemonChiffon(255,250,205)" 50 "Yellow(255,255,0)" 49 "LightYellow(255,255,224)" 48 "Ivory(255,255,240)" 47 "LightGoldenrodYellow(250,250,210)" 46 "Beige(245,245,220)" 45 "GreenYellow(173,255,47)" 44 "Chartreuse(127,255,0)" 43 "Lime(0,255,0)" 42 "LimeGreen(50,205,50)" 41 "PaleGreen(152,251,152)" 40 "LightGreen(144,238,144)" 39 "SeaGreen(46,139,87)" 38 "SpringGreen(60,179,113)" 37 "MediumSpringGreen(0,255,127)" 36 "MediumAquamarine(0,250,154)" 35 "Auqamarin(127,255,170)" 34 "MediumTurquoise(72,209,204)" 33 "DarkCyan(0,139,139)" 32 "DarkTurquoise(0,206,209)" 31 "Cyan(0,255,255)" 30 "PaleTurquoise(175,238,238)" 29 "DeepSkyBlue(0,191,255)" 28 "SkyBlue(135,206,235)" 27 "LightSkyBlue(135,206,250)" 26 "DoderBlue(30,144,255)" 25 "CornflowerBlue(100,149,237)" 24 "RoyalBlue(65,105,225)" 23 "Navy(0,0,128)" 22 "DarkBlue(0,0,139)" 21 "MidnightBlue(25,25,112)" 20 "MediumBlue(0,0,205)" 19 "Blue(0,0,255)" 18 "DarkSlateBlue(72,61,139)" 17 "SlateBlue(106,90,205)" 16 "MediumSlateBlue(123,104,238)" 15 "MediumPurple(147,112,219)" 14 "BlueViolet(138,43,226)" 13 "Indigo(75,0,130)" 12 "DarkOrchid(153,50,204)" 11 "DarkVoilet(148,0,211)" 10 "MediumOrchid(186,85,211)" 9 "DarkMagenta(139,0,139)" 8 "Magenta(255,0,255)" 7 "Violet(238,130,238)" 6 "Orchid(218,112,214)" 5 "MediumVioletRed(199,21,133)" 4 "DeepPink(255,20,147)" 3 "HotPink(255,105,180)" 2 "PaleVioletRed(219,112,147)" 1 "Crimson(220,20,60)" 0 "LightPink(255,182,193)" ;
VAL_ 535 FDHandleCmd 3 "Handle Fold" 2 "All Handle Unfold" 1 "Dr Handle Unfold" 0 "No Command" ;
VAL_ 535 AmbLightColor4 63 "Red(255,0,0)" 62 "IndianRed(205,92,92)" 61 "LightCoral(240,128,128)" 60 "Tomato(255,99,71)" 59 "OrangeRed(255,69,0)" 58 "Coral(255,127,80)" 57 "LightSalmon(255,160,122)" 56 "DarkOrange(255,140,0)" 55 "Bisque(255,228,196)" 54 "NavajoWhite(255,222,173)" 53 "BlanchedAlmond(255,235,205)" 52 "Gold(255,215,0)" 51 "LemonChiffon(255,250,205)" 50 "Yellow(255,255,0)" 49 "LightYellow(255,255,224)" 48 "Ivory(255,255,240)" 47 "LightGoldenrodYellow(250,250,210)" 46 "Beige(245,245,220)" 45 "GreenYellow(173,255,47)" 44 "Chartreuse(127,255,0)" 43 "Lime(0,255,0)" 42 "LimeGreen(50,205,50)" 41 "PaleGreen(152,251,152)" 40 "LightGreen(144,238,144)" 39 "SeaGreen(46,139,87)" 38 "SpringGreen(60,179,113)" 37 "MediumSpringGreen(0,255,127)" 36 "MediumAquamarine(0,250,154)" 35 "Auqamarin(127,255,170)" 34 "MediumTurquoise(72,209,204)" 33 "DarkCyan(0,139,139)" 32 "DarkTurquoise(0,206,209)" 31 "Cyan(0,255,255)" 30 "PaleTurquoise(175,238,238)" 29 "DeepSkyBlue(0,191,255)" 28 "SkyBlue(135,206,235)" 27 "LightSkyBlue(135,206,250)" 26 "DoderBlue(30,144,255)" 25 "CornflowerBlue(100,149,237)" 24 "RoyalBlue(65,105,225)" 23 "Navy(0,0,128)" 22 "DarkBlue(0,0,139)" 21 "MidnightBlue(25,25,112)" 20 "MediumBlue(0,0,205)" 19 "Blue(0,0,255)" 18 "DarkSlateBlue(72,61,139)" 17 "SlateBlue(106,90,205)" 16 "MediumSlateBlue(123,104,238)" 15 "MediumPurple(147,112,219)" 14 "BlueViolet(138,43,226)" 13 "Indigo(75,0,130)" 12 "DarkOrchid(153,50,204)" 11 "DarkVoilet(148,0,211)" 10 "MediumOrchid(186,85,211)" 9 "DarkMagenta(139,0,139)" 8 "Magenta(255,0,255)" 7 "Violet(238,130,238)" 6 "Orchid(218,112,214)" 5 "MediumVioletRed(199,21,133)" 4 "DeepPink(255,20,147)" 3 "HotPink(255,105,180)" 2 "PaleVioletRed(219,112,147)" 1 "Crimson(220,20,60)" 0 "LightPink(255,182,193)" ;
VAL_ 535 AmbLightColor5 63 "Red(255,0,0)" 62 "IndianRed(205,92,92)" 61 "LightCoral(240,128,128)" 60 "Tomato(255,99,71)" 59 "OrangeRed(255,69,0)" 58 "Coral(255,127,80)" 57 "LightSalmon(255,160,122)" 56 "DarkOrange(255,140,0)" 55 "Bisque(255,228,196)" 54 "NavajoWhite(255,222,173)" 53 "BlanchedAlmond(255,235,205)" 52 "Gold(255,215,0)" 51 "LemonChiffon(255,250,205)" 50 "Yellow(255,255,0)" 49 "LightYellow(255,255,224)" 48 "Ivory(255,255,240)" 47 "LightGoldenrodYellow(250,250,210)" 46 "Beige(245,245,220)" 45 "GreenYellow(173,255,47)" 44 "Chartreuse(127,255,0)" 43 "Lime(0,255,0)" 42 "LimeGreen(50,205,50)" 41 "PaleGreen(152,251,152)" 40 "LightGreen(144,238,144)" 39 "SeaGreen(46,139,87)" 38 "SpringGreen(60,179,113)" 37 "MediumSpringGreen(0,255,127)" 36 "MediumAquamarine(0,250,154)" 35 "Auqamarin(127,255,170)" 34 "MediumTurquoise(72,209,204)" 33 "DarkCyan(0,139,139)" 32 "DarkTurquoise(0,206,209)" 31 "Cyan(0,255,255)" 30 "PaleTurquoise(175,238,238)" 29 "DeepSkyBlue(0,191,255)" 28 "SkyBlue(135,206,235)" 27 "LightSkyBlue(135,206,250)" 26 "DoderBlue(30,144,255)" 25 "CornflowerBlue(100,149,237)" 24 "RoyalBlue(65,105,225)" 23 "Navy(0,0,128)" 22 "DarkBlue(0,0,139)" 21 "MidnightBlue(25,25,112)" 20 "MediumBlue(0,0,205)" 19 "Blue(0,0,255)" 18 "DarkSlateBlue(72,61,139)" 17 "SlateBlue(106,90,205)" 16 "MediumSlateBlue(123,104,238)" 15 "MediumPurple(147,112,219)" 14 "BlueViolet(138,43,226)" 13 "Indigo(75,0,130)" 12 "DarkOrchid(153,50,204)" 11 "DarkVoilet(148,0,211)" 10 "MediumOrchid(186,85,211)" 9 "DarkMagenta(139,0,139)" 8 "Magenta(255,0,255)" 7 "Violet(238,130,238)" 6 "Orchid(218,112,214)" 5 "MediumVioletRed(199,21,133)" 4 "DeepPink(255,20,147)" 3 "HotPink(255,105,180)" 2 "PaleVioletRed(219,112,147)" 1 "Crimson(220,20,60)" 0 "LightPink(255,182,193)" ;
VAL_ 535 AmbLightColor6 63 "Red(255,0,0)" 62 "IndianRed(205,92,92)" 61 "LightCoral(240,128,128)" 60 "Tomato(255,99,71)" 59 "OrangeRed(255,69,0)" 58 "Coral(255,127,80)" 57 "LightSalmon(255,160,122)" 56 "DarkOrange(255,140,0)" 55 "Bisque(255,228,196)" 54 "NavajoWhite(255,222,173)" 53 "BlanchedAlmond(255,235,205)" 52 "Gold(255,215,0)" 51 "LemonChiffon(255,250,205)" 50 "Yellow(255,255,0)" 49 "LightYellow(255,255,224)" 48 "Ivory(255,255,240)" 47 "LightGoldenrodYellow(250,250,210)" 46 "Beige(245,245,220)" 45 "GreenYellow(173,255,47)" 44 "Chartreuse(127,255,0)" 43 "Lime(0,255,0)" 42 "LimeGreen(50,205,50)" 41 "PaleGreen(152,251,152)" 40 "LightGreen(144,238,144)" 39 "SeaGreen(46,139,87)" 38 "SpringGreen(60,179,113)" 37 "MediumSpringGreen(0,255,127)" 36 "MediumAquamarine(0,250,154)" 35 "Auqamarin(127,255,170)" 34 "MediumTurquoise(72,209,204)" 33 "DarkCyan(0,139,139)" 32 "DarkTurquoise(0,206,209)" 31 "Cyan(0,255,255)" 30 "PaleTurquoise(175,238,238)" 29 "DeepSkyBlue(0,191,255)" 28 "SkyBlue(135,206,235)" 27 "LightSkyBlue(135,206,250)" 26 "DoderBlue(30,144,255)" 25 "CornflowerBlue(100,149,237)" 24 "RoyalBlue(65,105,225)" 23 "Navy(0,0,128)" 22 "DarkBlue(0,0,139)" 21 "MidnightBlue(25,25,112)" 20 "MediumBlue(0,0,205)" 19 "Blue(0,0,255)" 18 "DarkSlateBlue(72,61,139)" 17 "SlateBlue(106,90,205)" 16 "MediumSlateBlue(123,104,238)" 15 "MediumPurple(147,112,219)" 14 "BlueViolet(138,43,226)" 13 "Indigo(75,0,130)" 12 "DarkOrchid(153,50,204)" 11 "DarkVoilet(148,0,211)" 10 "MediumOrchid(186,85,211)" 9 "DarkMagenta(139,0,139)" 8 "Magenta(255,0,255)" 7 "Violet(238,130,238)" 6 "Orchid(218,112,214)" 5 "MediumVioletRed(199,21,133)" 4 "DeepPink(255,20,147)" 3 "HotPink(255,105,180)" 2 "PaleVioletRed(219,112,147)" 1 "Crimson(220,20,60)" 0 "LightPink(255,182,193)" ;
VAL_ 535 AmbLightBrightness1 101 "~0x7F Invalid" ;
VAL_ 535 AmbLightBrightness2 101 "~0x7F Invalid" ;
VAL_ 535 AmbLightBrightness3 101 "~0x7F Invalid" ;
VAL_ 535 AmbLightBrightness4 101 "~0x7F Invalid" ;
VAL_ 535 AmbLightBrightness5 101 "~0x7F Invalid" ;
VAL_ 535 AmbLightBrightness6 101 "~0x7F Invalid" ;
VAL_ 535 AmbLightBreath1 7 "Breath Keep" 6 "Flash Keep" 5 "Breath Keep Ice Blue" 4 "Flash Keep Ice Blue" 3 "Flash Keep Red" 2 "Breath Red" 1 "Welcome" 0 "OFF" ;
VAL_ 535 AmbLightBreath2 7 "Breath Keep" 6 "Flash Keep" 5 "Breath Keep Ice Blue" 4 "Flash Keep Ice Blue" 3 "Flash Keep Red" 2 "Breath Red" 1 "Welcome" 0 "OFF" ;
VAL_ 535 AmbLightBreath3 7 "Breath Keep" 6 "Flash Keep" 5 "Breath Keep Ice Blue" 4 "Flash Keep Ice Blue" 3 "Flash Keep Red" 2 "Breath Red" 1 "Welcome" 0 "OFF" ;
VAL_ 535 AmbLightBreath4 7 "Breath Keep" 6 "Flash Keep" 5 "Breath Keep Ice Blue" 4 "Flash Keep Ice Blue" 3 "Flash Keep Red" 2 "Breath Red" 1 "Welcome" 0 "OFF" ;
VAL_ 535 AmbLightBreath5 7 "Breath Keep" 6 "Flash Keep" 5 "Breath Keep Ice Blue" 4 "Flash Keep Ice Blue" 3 "Flash Keep Red" 2 "Breath Red" 1 "Welcome" 0 "OFF" ;
VAL_ 535 AmbLightBreath6 7 "Breath Keep" 6 "Flash Keep" 5 "Breath Keep Ice Blue" 4 "Flash Keep Ice Blue" 3 "Flash Keep Red" 2 "Breath Red" 1 "Welcome" 0 "OFF" ;
VAL_ 535 WelcomeLight 2 "Lock Mode" 1 "Welcome Mode" 0 "Off" ;
VAL_ 535 FDC_BCM_TurnSwTSetSta_Sta 3 "Undefiend" 2 "7 times" 1 "5 times" 0 "3 times" ;
VAL_ 535 FDC_BCM_UserHeightSet_Sta 1023 "Invalid" ;
VAL_ 535 FDC_BCM_UserNow_Sta 7 "Rent" 6 "Guest" 5 "User 5" 4 "User 4" 3 "User 3" 2 "User 2" 1 "User 1" 0 "Invalid" ;
VAL_ 535 FDC_DKC_CommandToBCM_Cmd 15 "Invalid" 13 "Remote Charge Port door Open" 12 "Remote Front Hood Open" 11 "UWB Unlock" 10 "UWB Lock" 9 "NFC Command" 8 "Car Search Mute" 7 "Forced to lift anti-theft" 6 "HandleTailgate Open/Close" 5 "Failed to Lock Tailgate" 4 "Car Search" 3 "Remote Tailgate Open/Close" 2 "Unlock" 1 "Lock" 0 "Default" ;
VAL_ 535 FDC_DKC_DKeyAreaPE_Sta 3 "UnusedandReserved" 2 "In to Unlock Zone" 1 "In to Lock Zone" 0 "Unavailable" ;
VAL_ 535 FDC_BCM_PTGOpenHeight_Sta 7 "Invalid" 6 "Invalid" 5 "Invalid" 4 "Set by User" 3 "Lv3(80%)" 2 "Lv2(60%)" 1 "Lv1(40%)" 0 "Full Open" ;
VAL_ 535 FDC_BCM_ATCtrl_Cmd 2 "Unlock" 1 "Lock" 0 "Stand By" ;
VAL_ 535 FDC_BCM_LockAlarm_Cmd 2 "Lock Fail" 1 "Lock" 0 "No Request" ;
VAL_ 535 FDC_BCM_FWipSw_Sta 7 "Invalid" 4 "Int" 3 "High" 2 "Low" 1 "Auto" 0 "OFF" ;
VAL_ 535 FDC_BCM_TurnSw_Sta 3 "Invalid" 2 "Right" 1 "Left" 0 "OFF" ;
VAL_ 535 FDC_BCM_FWasSw_Sta 3 "Invalid" 2 "Mist" 1 "ON" 0 "OFF" ;
VAL_ 535 FDC_BCM_PassSW_Sta 1 "Press" 0 "Release" ;
VAL_ 535 FDC_BCM_DimSw 1 "On" 0 "Off" ;
VAL_ 535 FDC_THCM_ACTInitial_Cmd 1 "Initial Reuqest" 0 "No Request" ;
VAL_ 535 FDC_DKC_SPTGDet_Cmd 1 "Request" 0 "No request" ;
VAL_ 535 FDC_DKC_SPTGOpen_Cmd 1 "Request" 0 "No request" ;
VAL_ 535 FDC_BCM_HazardIND_Cmd 1 "ON" 0 "OFF" ;
VAL_ 535 FDC_THCM_AirIntZ3_Sta 4 "Level 3" 3 "Level 2" 2 "Level 1" 1 "OFF" 0 "Invalid" ;
VAL_ 535 FDC_BCM_OutMode_Cmd 9 "PTG Flash Twice" 8 "SPTG Detecting" 7 "ESS_Active" 6 "Antitheft Alarm" 5 "Unlock or PTG Flash 3 times" 4 "Lock" 3 "Hazard" 2 "Right Turn Lamp" 1 "Left Turn Lamp" 0 "Stand By" ;
VAL_ 535 FDC_EChrg_SW_Sta 2 "Invalid" 1 "Press" 0 "Release" ;
VAL_ 595 IVI_Located_STA 3 "Not Used" 2 "3D fix" 1 "2D fix" 0 "No fix" ;
VAL_ 595 Approach_Unlock_SW 1 "Press" 0 "Release" ;
VAL_ 595 Walkaway_Lock_SW 1 "Press" 0 "Release" ;
VAL_ 595 BrkSw_Sta 1 "Active" 0 "Inactive" ;
VAL_ 595 DSEAT_anti_set 1 "ON" 0 "OFF" ;
VAL_ 595 DSEAT_entryfun_set 1 "ON" 0 "OFF" ;
VAL_ 595 IVI_PTG_Mode_SW 2 "Invalid" 1 "Press" 0 "No Request" ;
VAL_ 595 PSEAT_vent_req 4 "OFF" 3 "Vent3" 2 "Vent2" 1 "Vent1" 0 "No request" ;
VAL_ 595 IVI_PTG_Sta_SW 2 "Invalid" 1 "Press" 0 "Release" ;
VAL_ 595 IVI_ISA_OffsetSpd 15 "Invalid" 14 "reserve" 13 "reserve" 12 "reserve" 11 "5 mph" 10 "0 mph" 9 "-5 mph" 8 "reserve" 7 "reserve" 6 "reserve" 5 "+10 km/h" 4 "+5 km/h" 3 "0 km/h" 2 "-5 km/h" 1 "-10 km/h" 0 "Off" ;
VAL_ 595 SenstivityPosition 15 "not used" 14 "not used" 13 "not used" 12 "not used" 11 "not used" 10 "not used" 9 "not used" 8 "not used" 7 "not used" 6 "not used" 5 "not used" 4 "senstivity level-4" 3 "senstivity level-3" 2 "senstivity level-2" 1 "senstivity level-1" 0 "not used" ;
VAL_ 595 Distance_unit 1 "mile" 0 "kilometer" ;
VAL_ 595 Hood_Latch_SW 2 "invalid" 1 "Press" 0 "No Request" ;
VAL_ 595 DSEAT_vent_req 7 "Not used" 6 "Not used" 5 "Not used" 4 "OFF" 3 "High" 2 "Middle" 1 "Low" 0 "No request" ;
VAL_ 595 HeadLampSW 3 "OFF" 2 "Low beam" 1 "Postion lamp" 0 "AUTO" ;
VAL_ 595 IVI_Time_Month 15 "Not Used" 14 "Not Used" 13 "Not Used" 0 "invalid" ;
VAL_ 595 IVI_DSEATHeater_Cmd 7 "Not used" 6 "Not used" 5 "Not used" 4 "OFF" 3 "High" 2 "Middle" 1 "Low" 0 "No request" ;
VAL_ 595 IVI_PSEATHeater_Cmd 7 "Not used" 6 "Not used" 5 "Not used" 4 "OFF" 3 "High" 2 "Middle" 1 "Low" 0 "No request" ;
VAL_ 595 FDC_PTG_inner_SW_2 3 "Stuck" 2 "Press&Hold" 1 "Push" 0 "Off" ;
VAL_ 595 BrkSw_V 1 "Invalid" 0 "Valid" ;
VAL_ 595 MCPressure_V 1 "Invalid" 0 "Valid" ;
VAL_ 595 BrkPedalPos_Sta 1 "Valid" 0 "Invalid" ;
VAL_ 595 VehSpeed 4095 "Invalid" ;
VAL_ 595 L_Drv_CtrlCmd 127 "No Request" 100 "Max" 0 "Min" ;
VAL_ 595 L_Pas_CtrlCmd 127 "No Request" 100 "Max" 0 "Min" ;
VAL_ 595 L_RLD_CtrlCmd 127 "No Request" 100 "Max" 0 "Min" ;
VAL_ 595 L_RRD_CtrlCmd 127 "No Request" 100 "Max" 0 "Min" ;
VAL_ 595 OFF_AC_MODE 7 "Invalid" 3 "CAMP" 2 "Pet" 1 "ON" 0 "OFF" ;
VAL_ 595 WlcmLight_Mode 2 "Mode3" 1 "Mode2" 0 "Mode1" ;
VAL_ 595 Light_ShowStart_Req 1 "Press" 0 "Release" ;
VAL_ 595 Light_ShowStop_Req 1 "Press" 0 "Release" ;
VAL_ 595 AVM_parking_excute 3 "remote request" 2 "invalid" 1 "press" 0 "release" ;
VAL_ 595 IVI_PTG_Open_Height 7 "Invalid" 6 "Invalid" 5 "No Request" 4 "Set by User" 3 "Lv3(80%)" 2 "Lv2(60%)" 1 "Lv1(40%)" 0 "Full Open" ;
VAL_ 595 TBOX_Remote_PW 16 "App 4Door AutoDown" 15 "App 4Door AutoUp" 14 "Stop" 13 "App RR" 12 "App RL ManualDown" 11 "App FR MaualDown" 10 "App FL ManualDown" 9 "App 4Door ManualDown" 8 "App RR AutoDown" 7 "App RR AutoUp" 6 "App RL AutoDown" 5 "App RL AutoUp" 4 "App FR AutoDown" 3 "App FR AutoUp" 2 "App FL AutoDown" 1 "App FL AutoUp" 0 "release" ;
VAL_ 595 METER_KPH_Calcu 255 "Invalid" ;
VAL_ 595 ChrgInLockReq 2 "Unlock" 1 "Lock" 0 "No action" ;
VAL_ 595 IVI_TrailerCheckReq_Sta 1 "Press" 0 "Release" ;
VAL_ 595 IVI_TrailerModeSW_Sta 1 "ON" 0 "OFF" ;
VAL_ 595 IVI_ChargePortSW_Sta 1 "Press" 0 "Release" ;
VAL_ 595 ChrgPlugSta 3 "Plug-in dectected" 2 "DC Plug in" 1 "AC Plug in" 0 "No plug" ;
VAL_ 595 ExtChrgSta 3 "Fault" 2 "Charging Completed" 1 "Charging" 0 "No action" ;
VAL_ 595 OBCV2LSta 2 "Fault" 1 "Working" 0 "Not working" ;
VAL_ 595 V2LSta 3 "Invalid" 2 "SW on" 1 "V2L Adapter Plug-in" 0 "No plug" ;
VAL_ 1080 OTA_Progress_Rate 102 "Invalid" 101 "Not in progress" ;
VAL_ 1080 OTA_MDA_Status 15 "Undefine" 14 "Vehicle Reversed" 13 "OTA Task Finished" 12 "Vehicle Update Complete" 11 "Update Failed" 10 "Download Failed" 9 "Wait Arm" 8 "Download Suspend" 7 "Vehicle Roll-Back" 6 "Vehicle Updating" 5 "Wait Update" 4 "Campaign Downloading" 3 "Wait Download" 2 "Ask Campaign" 1 "Wait Network" 0 "Not Ready" ;
VAL_ 1080 OTA_Network_Type 3 "Undefine" 2 "WiFi" 1 "LTE" 0 "Network Not Available" ;
VAL_ 1080 OTA_Mode 1 "OTA mode" 0 "Normal mode" ;
VAL_ 1080 OTA_DL_Available 1 "Ready for Download" 0 "Not Ready" ;
VAL_ 1080 OTA_InVehicle_FW 2 "FW Need Update" 1 "FW Up to Date" 0 "Not Confirm" ;
VAL_ 1080 OTA_Update_Available 1 "Ready for Update" 0 "Not Ready" ;
VAL_ 1080 OTA_Updating_ECU_8bit 255 "Invalid" 36 "Zone_R" 35 "Zone_L" 34 "DKC_UWB3" 33 "DKC_UWB2" 32 "DKC_UWB1" 31 "DKC_NFC" 30 "DKC_BLE" 29 "HMI" 28 "W_PTC" 27 "EBM" 26 "AIRPTC" 25 "E_Compressor" 24 "Shifter" 23 "TELLTALE" 22 "MRR" 21 "SRR_M" 20 "FCM" 19 "EPS" 18 "EOP_F" 17 "EOP_R" 16 "MCU_F" 15 "MCU_R" 14 "eBST" 13 "ESC" 12 "ABM" 11 "PSEAT" 10 "DSEAT" 9 "PTG" 8 "CCU" 7 "BMS" 6 "DKC" 5 "Zone_Dr" 4 "Zone_Fr" 3 "T-Box" 2 "IVI" 1 "FDC" 0 "No action" ;
VAL_ 1080 OTA_Lock_Req 1 "Lock Request" 0 "No action" ;
VAL_ 1080 OTA_TBOXResetReq 1 "Request reset" 0 "No request" ;
VAL_ 1080 OTA_Permit_Agreed 1 "Confirmed" 0 "Not Confirm" ;
VAL_ 1080 OTA_Remained_Time 1081 "No action" ;
VAL_ 1080 OTA_Debug_Code 63 "Backend unreachable" 56 "ECU upgrade stuck" 40 "Invalid parameter" 55 "ECU invalid data" 54 "ECU timeout" 53 "ECU unreachable" 51 "Method not support" 50 "Unknown error" 65 "Backend invalid data" 64 "Backend timeout" 0 "Normal state" ;
VAL_ 1080 OTA_Emergency_Sta 2 "Emergency - Lock Mode" 1 "Emergency - Limp Mode" 0 "Normal" ;
VAL_ 1280 NM_FUSION_PNI 1 "NM PDU contains Partial Network request information" 0 "NM PDU contains no Partial Network request information" ;
VAL_ 1280 NM_FUSION_Active_WU 1 "Node has woken up the network (active Wakeup)" 0 "Node has not woken up the network (passive wakeup)" ;
VAL_ 1280 NM_FUSION_CSB 1 "Start of synchronized shutdown is requested by main coordinator" 0 "Start of synchronized shutdown is not requested by main coordinator" ;
VAL_ 1280 NM_FUSION_Rpt_Msg_Req 1 "Repeat Message State requested" 0 "Repeat Message State not requested" ;
VAL_ 1280 NM_FUSION_ERROR_State 8 "BUS OFF_L2" 4 "BUS OFF_L1" 2 "ERROR PASSIVE" 1 "ERROR ACTIVE" 0 "Inactive" ;
VAL_ 1174 TimeSyncFromBS_Month 15 "Not Used" 14 "Not Used" 13 "Not Used" 0 "invalid" ;
VAL_ 497 DrPMMSysErrLmp 1 "Error" 0 "Normal" ;
VAL_ 497 DrPMMLVOutPErrLmp 1 "Error" 0 "Normal" ;
VAL_ 497 DrPMMLimpHomeActReq 1 "Error" 0 "Normal" ;
VAL_ 497 DrAPWStaErr 1 "Error" 0 "Normal" ;
VAL_ 497 DrIVIFault 2 "Check fail" 1 "Check OK" 0 "No check" ;
VAL_ 497 DrEOBDFault 2 "Check fail" 1 "Check OK" 0 "No check" ;
VAL_ 497 DrInfoFault 2 "Check fail" 1 "Check OK" 0 "No check" ;
VAL_ 497 DrPwrWindowECUFault 2 "Check fail" 1 "Check OK" 0 "No check" ;
VAL_ 497 DrTHCMFault 2 "Check fail" 1 "Check OK" 0 "No check" ;
VAL_ 497 DrColumnSWFault 2 "Check fail" 1 "Check OK" 0 "No check" ;
VAL_ 497 Blower_FB 15 "Invalid" ;
VAL_ 497 APTC_Err 3 "Invalid" 2 "reserved" 1 "fault" 0 "normal" ;
VAL_ 497 Blower_Err 3 "Invalid" 2 "reserved" 1 "fault" 0 "normal" ;
VAL_ 497 T_Foot_Rr_Err 3 "Invalid" 2 "reserved" 1 "fault" 0 "normal" ;
VAL_ 497 T_Face_Rr_Err 3 "Invalid" 2 "reserved" 1 "fault" 0 "normal" ;
VAL_ 497 T_Foot_R_Err 3 "Invalid" 2 "reserved" 1 "fault" 0 "normal" ;
VAL_ 497 T_Face_R_Err 3 "Invalid" 2 "reserved" 1 "fault" 0 "normal" ;
VAL_ 497 T_Foot_L_Err 3 "Invalid" 2 "reserved" 1 "fault" 0 "normal" ;
VAL_ 497 T_Face_L_Err 3 "Invalid" 2 "reserved" 1 "fault" 0 "normal" ;
VAL_ 497 Tincar_Err 3 "Invalid" 2 "reserved" 1 "fault" 0 "normal" ;
VAL_ 497 Tevap_Err 3 "Invalid" 2 "reserved" 1 "fault" 0 "normal" ;
VAL_ 497 SolarR_Err 3 "Invalid" 2 "reserved" 1 "fault" 0 "normal" ;
VAL_ 497 SolarL_Err 3 "Invalid" 2 "reserved" 1 "fault" 0 "normal" ;
VAL_ 497 DrSCPSysErrLmp 1 "Error" 0 "Normal" ;
VAL_ 497 ZoneDrMalfunLevel 5 "Invalid" 4 "4th grade malfunction" 3 "3rd grade malfunction" 2 "2nd grade malfunction" 1 "1st grade malfunction" 0 "Normal" ;
VAL_ 497 DrAPWLINErr 1 "Error" 0 "Normal" ;
VAL_ 497 DrONA1ErrSta 1 "Error" 0 "Normal" ;
VAL_ 497 DrStdAErrSta 1 "Error" 0 "Normal" ;
VAL_ 497 DrPwrWinErrSta 1 "Error" 0 "Normal" ;
VAL_ 497 DrInfoErrSta 1 "Error" 0 "Normal" ;
VAL_ 497 RegenSW_Err 1 "Error" 0 "Normal" ;
VAL_ 497 DrPwrSta 7 "Invalid" 5 "READY" 4 "ON" 3 "STANDBY" 2 "OFF-After-Run" 1 "OFF-Charging" 0 "OFF" ;
VAL_ 497 DrPwrInformationSta 1 "ON" 0 "OFF" ;
VAL_ 497 ZDR_SYS_BSWSleepReq_Sta 1 "Request" 0 "No Request" ;
VAL_ 497 ZDR_VCU_HWReset_Sta 25 "EBM power off" 24 "ECompressor power off" 23 "WPTC power off" 22 "HMI power off" 21 "TBox power off" 20 "IVI power off" 19 "AirPTC power off" 18 "PSEAT power off" 17 "DSEAT power off" 16 "ABM power off" 15 "EPS power off" 14 "BMS power off" 13 "EOP_F power off" 12 "EOP_R power off" 11 "CCU power off" 10 "DKC power off" 9 "MRR power off" 8 "SRR_M power off" 7 "FCM power off" 6 "MCU_F power off" 5 "MCU_R power off" 4 "Shifter power off" 3 "Telltale power off" 2 "EBST power off" 1 "ESC power off" 0 "No request" ;
VAL_ 497 ZDR_VCU_PwrSupply_Sta 1 "Power supply off" 0 "No action" ;
VAL_ 498 FrPwrStdbyA1PlusFault 7 "Reserved" 6 "Reserved" 5 "Reserved" 4 "Reserved" 3 "Reserved" 2 "Reserved" 1 "Fault" 0 "Normal" ;
VAL_ 498 FrPwrStdbyA2PlusFault 7 "Reserved" 6 "Reserved" 5 "Reserved" 4 "Reserved" 3 "Reserved" 2 "Reserved" 1 "Fault" 0 "Normal" ;
VAL_ 498 FrPwrONA1Fault 2 "Check fail" 1 "Check OK" 0 "No check" ;
VAL_ 498 FrBMS_CCU_CIRFault 7 "Reserved" 6 "Reserved" 5 "Reserved" 4 "Reserved" 3 "Reserved" 2 "Reserved" 1 "Fault" 0 "Normal" ;
VAL_ 498 FrEDU_INVERTERFault 7 "Reserved" 6 "Reserved" 5 "Reserved" 4 "Reserved" 3 "Reserved" 2 "Reserved" 1 "Fault" 0 "Normal" ;
VAL_ 498 FrPwrStdbyA1Fault 2 "Check fail" 1 "Check OK" 0 "No check" ;
VAL_ 498 FrPMMSysErrLmp 1 "Error" 0 "Normal" ;
VAL_ 498 FrPMMLVOutPErrLmp 1 "Error" 0 "Normal" ;
VAL_ 498 FrPMMLimpHomeActReq 1 "Error" 0 "Normal" ;
VAL_ 498 ZoneFrMalfunLevel 5 "Invalid" 4 "4th grade malfunction" 3 "3rd grade malfunction" 2 "2nd grade malfunction" 1 "1st grade malfunction" 0 "Normal" ;
VAL_ 498 FrStdA1PCErr 1 "Error" 0 "Normal" ;
VAL_ 498 FrStdA2PErr 1 "Error" 0 "Normal" ;
VAL_ 498 FrStdA2PCErr 1 "Error" 0 "Normal" ;
VAL_ 498 FrBMSCCUCErr 1 "Error" 0 "Normal" ;
VAL_ 498 FrEDUErr 1 "Error" 0 "Normal" ;
VAL_ 498 FrPwrSta 7 "Invalid" 5 "READY" 4 "ON" 3 "STANDBY" 2 "OFF-After-Run" 1 "OFF-Charging" 0 "OFF" ;
VAL_ 498 EACProtectEnable 2 "level2" 1 "level1" 0 "off" ;
VAL_ 498 TWV_Err 3 "Invalid" 2 "reserved" 1 "fault" 0 "normal" ;
VAL_ 498 EWP3_Err 3 "Invalid" 2 "reserved" 1 "fault" 0 "normal" ;
VAL_ 498 EWP2_Err 3 "Invalid" 2 "reserved" 1 "fault" 0 "normal" ;
VAL_ 498 FWV_Err 3 "Invalid" 2 "reserved" 1 "fault" 0 "normal" ;
VAL_ 498 EWP1_Err 3 "Invalid" 2 "reserved" 1 "fault" 0 "normal" ;
VAL_ 498 WPTC_Err 3 "Invalid" 2 "reserved" 1 "fault" 0 "normal" ;
VAL_ 498 Fan_Err 3 "Invalid" 2 "reserved" 1 "fault" 0 "normal" ;
VAL_ 498 EXV2_Err 3 "Invalid" 2 "reserved" 1 "fault" 0 "normal" ;
VAL_ 498 EXV1_Err 3 "Invalid" 2 "reserved" 1 "fault" 0 "normal" ;
VAL_ 498 SOTXV_Err 3 "Invalid" 2 "reserved" 1 "fault" 0 "normal" ;
VAL_ 498 COMP_Err 3 "Invalid" 2 "reserved" 1 "fault" 0 "normal" ;
VAL_ 498 SOV3_Err 3 "Invalid" 2 "reserved" 1 "fault" 0 "normal" ;
VAL_ 498 SOV2_Err 3 "Invalid" 2 "reserved" 1 "fault" 0 "normal" ;
VAL_ 498 SOV1_Err 3 "Invalid" 2 "reserved" 1 "fault" 0 "normal" ;
VAL_ 498 PT_High_Tact_Err 3 "Invalid" 2 "reserved" 1 "fault" 0 "normal" ;
VAL_ 498 PT_High_P_Err 3 "Invalid" 2 "level2" 1 "level1" 0 "off" ;
VAL_ 498 PT_Low_T2_Err 3 "Invalid" 2 "reserved" 1 "fault" 0 "normal" ;
VAL_ 498 PT_Low_P2_Err 3 "Invalid" 2 "reserved" 1 "fault" 0 "normal" ;
VAL_ 498 PT_Low_T1_Err 3 "Invalid" 2 "reserved" 1 "fault" 0 "normal" ;
VAL_ 498 PT_Low_P1_Err 3 "Invalid" 2 "reserved" 1 "fault" 0 "normal" ;
VAL_ 498 Motor_Out_Temp_Err 3 "Invalid" 2 "reserved" 1 "fault" 0 "normal" ;
VAL_ 498 Bat_Out_Temp_Err 3 "Invalid" 2 "reserved" 1 "fault" 0 "normal" ;
VAL_ 498 Motor_In_Temp_Err 3 "Invalid" 2 "reserved" 1 "fault" 0 "normal" ;
VAL_ 498 Bat_In_Temp_Err 3 "Invalid" 2 "reserved" 1 "fault" 0 "normal" ;
VAL_ 498 Tamb_Err 3 "Invalid" 2 "reserved" 1 "fault" 0 "normal" ;
VAL_ 498 ZFR_SYS_BSWSleepReq_Sta 1 "Request" 0 "No Request" ;
VAL_ 498 ZFR_VCU_HWReset_Sta 25 "EBM power off" 24 "ECompressor power off" 23 "WPTC power off" 22 "HMI power off" 21 "TBox power off" 20 "IVI power off" 19 "AirPTC power off" 18 "PSEAT power off" 17 "DSEAT power off" 16 "ABM power off" 15 "EPS power off" 14 "BMS power off" 13 "EOP_F power off" 12 "EOP_R power off" 11 "CCU power off" 10 "DKC power off" 9 "MRR power off" 8 "SRR_M power off" 7 "FCM power off" 6 "MCU_F power off" 5 "MCU_R power off" 4 "Shifter power off" 3 "Telltale power off" 2 "EBST power off" 1 "ESC power off" 0 "No request" ;
VAL_ 498 ZFR_VCU_PwrSupply_Sta 1 "Power supply off" 0 "No action" ;
VAL_ 547 FrntPTCSts 1 "ON" 0 "OFF" ;
VAL_ 547 FrntPTCFltSt 3 "Degraded Failure" 2 "Permanent Failure" 1 "Temporary Failure" 0 "Normal" ;
VAL_ 547 FrntPTCLVUnderUFlt 1 "Failure" 0 "Normal" ;
VAL_ 547 FrntPTCLVOverUFlt 1 "Failure" 0 "Normal" ;
VAL_ 547 FrntPTCHVUnderUFlt 1 "Failure" 0 "Normal" ;
VAL_ 547 FrntPTCHVOverUFlt 1 "Failure" 0 "Normal" ;
VAL_ 547 FrntPTCLeOverAFlt 1 "Failure" 0 "Normal" ;
VAL_ 547 FrntPTCRiOverAFlt 1 "Failure" 0 "Normal" ;
VAL_ 547 FrntPTCLeCoreTSnsrFlt 1 "Failure" 0 "Normal" ;
VAL_ 547 FrntPTCRiCoreTSnsrFlt 1 "Failure" 0 "Normal" ;
VAL_ 547 FrntPTCLeCoreOverTFlt 1 "Failure" 0 "Normal" ;
VAL_ 547 FrntPTCRiCoreOverTFlt 1 "Failure" 0 "Normal" ;
VAL_ 547 FrntPTCLeIGBTShoCircFlt 1 "Failure" 0 "Normal" ;
VAL_ 547 FrntPTCRiIGBTShoCircFlt 1 "Failure" 0 "Normal" ;
VAL_ 547 FrntPTCLeOpentCircFlt 1 "Failure" 0 "Normal" ;
VAL_ 547 FrntPTCRiOpentCircFlt 1 "Failure" 0 "Normal" ;
VAL_ 547 FrntPTCPCBTSnsrFlt 1 "Failure" 0 "Normal" ;
VAL_ 547 FrntPTCPCBOverTFlt 1 "Failure" 0 "Normal" ;
VAL_ 547 FrntPTCComFlt 1 "Failure" 0 "Normal" ;
VAL_ 547 FrntPTCLeIGBTTSnsrFlt 1 "Failure" 0 "Normal" ;
VAL_ 547 FrntPTCRiIGBTTSnsrFlt 1 "Failure" 0 "Normal" ;
VAL_ 547 FrntPTCLeIGBTOverTFlt 1 "Failure" 0 "Normal" ;
VAL_ 547 FrntPTCRiIGBTOverTFlt 1 "Failure" 0 "Normal" ;
VAL_ 547 FrntPTCRearLeOverAFlt 1 "Failure" 0 "Normal" ;
VAL_ 547 FrntPTCRearLeOpentCircFlt 1 "Failure" 0 "Normal" ;
VAL_ 547 FrntPTCRearRiCoreOverTFlt 1 "Failure" 0 "Normal" ;
VAL_ 547 FrntPTCRearLeCoreOverTFlt 1 "Failure" 0 "Normal" ;
VAL_ 547 FrntPTCRearRiCoreTSnsrFlt 1 "Failure" 0 "Normal" ;
VAL_ 547 FrntPTCRearLeCoreTSnsrFlt 1 "Failure" 0 "Normal" ;
VAL_ 547 FrntPTCRearRiOverAFlt 1 "Failure" 0 "Normal" ;
VAL_ 547 FrntPTCRearRiOpentCircFlt 1 "Failure" 0 "Normal" ;
VAL_ 547 FrntPTCRearRiIGBTShoCFlt 1 "Failure" 0 "Normal" ;
VAL_ 547 FrntPTCRearLeIGBTShoCFlt 1 "Failure" 0 "Normal" ;
VAL_ 547 FrntPTCRearLeBusLineC 255 "Invalid" ;
VAL_ 547 FrntPTCLeCoreT 255 "Invalid" ;
VAL_ 547 FrntPTCRiCoreT 255 "Invalid" ;
VAL_ 547 FrntPTCLeActHeatPwr 255 "Invalid" 201 "~ 0xFE Invalid" ;
VAL_ 547 FrntPTCRiActHeatPwr 255 "Invalid" 201 "~ 0xFE Invalid" ;
VAL_ 547 FrntPTCLeIGBTT 255 "Invalid" ;
VAL_ 547 FrntPTCRiIGBTT 255 "Invalid" ;
VAL_ 547 FrntPTCPCBT 255 "Invalid" ;
VAL_ 547 FrntPTCRearRiBusLineC 255 "Invalid" ;
VAL_ 547 FrntPTCRearLeActHeatPwr 255 "Invalid" 201 "-0xFE:Reserved" ;
VAL_ 547 FrntPTCRearLeCoreT 255 "Invalid" ;
VAL_ 547 FrntPTCRearRiActHeatPwr 255 "Invalid" ;
VAL_ 547 FrntPTCRearRiCoreT 255 "Invalid" ;
VAL_ 547 FrntPTCLeBusLineC 255 "Invalid" ;
VAL_ 547 FrntPTCRiBusLineC 255 "Invalid" ;
VAL_ 547 FrntPTCBusLineHiV 1023 "Invalid" 1001 "~0x3FF   Invalid" ;
VAL_ 550 RLS_LIN_Resp_Err 1 "Error" 0 "Normal" ;
VAL_ 550 RLS_LightSnrErr 1 "LS error" 0 "LS no error" ;
VAL_ 550 RLS_RainSnrErr 1 "RS error" 0 "RS no error" ;
VAL_ 550 CSW_resp_error 1 "Error" 0 "Normal" ;
VAL_ 550 RLS_Lamp_Sta 1 "Lamps ON" 0 "Lamps OFF" ;
VAL_ 550 RLS_RainSnrWiperCmd 7 "Failure" 3 "High Speed" 2 "Low Speed" 0 "Off" ;
VAL_ 550 CSW_FWipSw_Sta 7 "invalid" 3 "High" 2 "Low" 1 "Auto" 0 "OFF" ;
VAL_ 550 CSW_TurnSw_Sta 3 "invalid" 2 "Right" 1 "Left" 0 "OFF" ;
VAL_ 550 CSW_RWasSW_Sta 3 "invalid" 1 "Press" 0 "Release" ;
VAL_ 550 CSW_FWasSw_Sta 3 "invalid" 2 "Mist" 1 "ON" 0 "OFF" ;
VAL_ 550 CSW_PassSW_Sta 1 "Press" 0 "Release" ;
VAL_ 550 CSW_DimSw 1 "On" 0 "Off" ;
VAL_ 550 CSW_RWipIntSw_Sta 3 "Invalid" 2 "Low" 1 "int" 0 "off" ;
VAL_ 550 SWC_Drivemode_Sta 1 "Press" 0 "Release" ;
VAL_ 550 SWC_CANCEL_Sta 1 "Press" 0 "Release" ;
VAL_ 550 SWC_ACC_Sta 1 "Press" 0 "Release" ;
VAL_ 550 SWC_A_Resp_Err 1 "Error" 0 "Normal" ;
VAL_ 550 SWC_Distance_Sta 1 "Press" 0 "Release" ;
VAL_ 550 SWC_Down_Sta 1 "Press" 0 "Release" ;
VAL_ 550 SWC_RegenUp 1 "Press" 0 "Release" ;
VAL_ 550 SWC_Left_Sta 1 "Press" 0 "Release" ;
VAL_ 550 SWC_mode_Sta 1 "Press" 0 "Release" ;
VAL_ 550 SWC_resp_error 1 "Error" 0 "Normal" ;
VAL_ 550 SWC_Res_Up_Sta 1 "Press" 0 "Release" ;
VAL_ 550 SWC_RegenDown 1 "Press" 0 "Release" ;
VAL_ 550 SWC_Right_Sta 1 "Press" 0 "Release" ;
VAL_ 550 SWC_Set_down_Sta 1 "Press" 0 "Release" ;
VAL_ 550 SWC_Trip_Sta 1 "Press" 0 "Release" ;
VAL_ 550 SWC_Up_Sta 1 "Press" 0 "Release" ;
VAL_ 550 SWC_VR_Sta 1 "Press" 0 "Release" ;
VAL_ 550 SWC_Undefined_Sta 1 "Press" 0 "Release" ;
VAL_ 550 SWC_LKA_Sta 1 "Press" 0 "Release" ;
VAL_ 550 L_Pas_Wdw_Obs_InhibitSts 1 "Obs Inhibit status" 0 "Not Obs Inhibit status" ;
VAL_ 550 L_Drv_Wdw_RRD_Switch 7 "Error" 6 "Reserved" 5 "Reserved" 4 "Auto Down" 3 "Auto Up" 2 "Manual Down" 1 "Manual Up" 0 "Inactive" ;
VAL_ 550 L_Drv_Wdw_RLD_Switch 7 "Error" 6 "Reserved" 5 "Reserved" 4 "Auto Down" 3 "Auto Up" 2 "Manual Down" 1 "Manual Up" 0 "Inactive" ;
VAL_ 550 L_Pas_Wdw_OD_Sts 1 "In Anti-pinch status" 0 "Non anti-pinch status" ;
VAL_ 550 L_Pas_Wdw_Init 1 "Window init complete" 0 "Window init incomplete" ;
VAL_ 550 L_Pas_OverHeat_Protect 1 "Active" 0 "Inactive" ;
VAL_ 550 L_Pas_Motor_Relay_Error 1 "Error" 0 "Normal" ;
VAL_ 550 L_Pas_Motor_Ripple_Error 1 "Error" 0 "Normal" ;
VAL_ 550 L_Drv_Wdw_Pas_Switch 7 "Error" 6 "Reserved" 5 "Reserved" 4 "Auto Down" 3 "Auto Up" 2 "Manual Down" 1 "Manual Up" 0 "Inactive" ;
VAL_ 550 L_Pas_Val_Wdw_Opened 127 "Invalid" ;
VAL_ 550 L_Pas_Wdw_PositionSts 3 "Invalid" 2 "Complete Close" 1 "Complete Open" 0 "Middle position" ;
VAL_ 550 L_Pas_Wdw_LocalSwitch 7 "Error" 6 "Reserved" 5 "Reserved" 4 "Auto Down" 3 "Auto Up" 2 "Manual Down" 1 "Manual Up" 0 "Inactive" ;
VAL_ 550 L_Pas_Wdw_Running_Sts 7 "Reserved" 5 "Reserved" 4 "Auto Down" 3 "Auto Up" 2 "Manual Down" 1 "Manual Up" 0 "Window stop" ;
VAL_ 550 L_Power_Status 3 "Voltage>16V" 2 "Voltage<9V" 1 "9V<Voltage<16V" 0 "Default" ;
VAL_ 550 FAPWL_01_LIN_Response_Error 1 "Error" 0 "Normal" ;
VAL_ 550 L_Drv_Wdw_Obs_InhibitSts 1 "Obs Inhibit status" 0 "Not Obs Inhibit status" ;
VAL_ 550 L_Drv_Wdw_OD_Sts 1 "In Anti-pinch status" 0 "Non anti-pinch status" ;
VAL_ 550 L_Drv_Wdw_Init 1 "Window init complete" 0 "Window init incomplete" ;
VAL_ 550 L_Drv_OverHeat_Protect 1 "Active" 0 "Inactive" ;
VAL_ 550 L_Drv_Motor_Relay_Error 1 "Error" 0 "Normal" ;
VAL_ 550 L_Drv_Motor_Ripple_Error 1 "Error" 0 "Normal" ;
VAL_ 550 L_Drv_Val_Wdw_Opened 127 "Invalid" ;
VAL_ 550 L_Drv_Wdw_PositionSts 3 "Invalid" 2 "Complete Close" 1 "Complete Open" 0 "Middle position" ;
VAL_ 550 L_Drv_Wdw_LocalSwitch 7 "Error" 6 "Reserved" 5 "Reserved" 4 "Auto Down" 3 "Auto Up" 2 "Manual Down" 1 "Manual Up" 0 "Inactive" ;
VAL_ 550 L_Drv_Wdw_Running_Sts 7 "Reserved" 5 "Reserved" 4 "Auto Down" 3 "Auto Up" 2 "Manual Down" 1 "Manual Up" 0 "Window stop" ;
VAL_ 550 L_RLD_Wdw_Init 1 "Window init complete" 0 "Window init incomplete" ;
VAL_ 550 L_RRD_Val_Wdw_Opened 127 "Invalid" ;
VAL_ 550 L_RRD_Wdw_PositionSts 3 "Invalid" 2 "Complete Close" 1 "Complete Open" 0 "Middle position" ;
VAL_ 550 L_RRD_Wdw_Obs_InhibitSts 1 "Obs Inhibit status" 0 "Not Obs Inhibit status" ;
VAL_ 550 L_RRD_Wdw_OD_Sts 1 "In Anti-pinch status" 0 "Non anti-pinch status" ;
VAL_ 550 L_RRD_Wdw_Init 1 "Window init complete" 0 "Window init incomplete" ;
VAL_ 550 L_RRD_OverHeat_Protect 1 "Active" 0 "Inactive" ;
VAL_ 550 L_RRD_Motor_Relay_Error 1 "Error" 0 "Normal" ;
VAL_ 550 L_RRD_Motor_Ripple_Error 1 "Error" 0 "Normal" ;
VAL_ 550 L_RRD_Wdw_LocalSwitch 7 "Error" 6 "Reserved" 5 "Reserved" 4 "Auto Down" 3 "Auto Up" 2 "Manual Down" 1 "Manual Up" 0 "Inactive" ;
VAL_ 550 L_RRD_Wdw_Running_Sts 7 "Reserved" 5 "Reserved" 4 "Auto Down" 3 "Auto Up" 2 "Manual Down" 1 "Manual Up" 0 "Window stop" ;
VAL_ 550 RAPWL_01_LIN_Response_Error 1 "Error" 0 "Normal" ;
VAL_ 550 L_RLD_Wdw_Obs_InhibitSts 1 "Obs Inhibit status" 0 "Not Obs Inhibit status" ;
VAL_ 550 L_RLD_Wdw_OD_Sts 1 "In Anti-pinch status" 0 "Non anti-pinch status" ;
VAL_ 550 L_RLD_Val_Wdw_Opened 127 "Invalid" ;
VAL_ 550 L_RLD_OverHeat_Protect 1 "Active" 0 "Inactive" ;
VAL_ 550 L_RLD_Motor_Relay_Error 1 "Error" 0 "Normal" ;
VAL_ 550 L_RLD_Motor_Ripple_Error 1 "Error" 0 "Normal" ;
VAL_ 550 L_RLD_Wdw_PositionSts 3 "Invalid" 2 "Complete Close" 1 "Complete Open" 0 "Middle position" ;
VAL_ 550 L_RLD_Wdw_LocalSwitch 7 "Error" 6 "Reserved" 5 "Reserved" 4 "Auto Down" 3 "Auto Up" 2 "Manual Down" 1 "Manual Up" 0 "Inactive" ;
VAL_ 550 L_RLD_Wdw_Running_Sts 7 "Reserved" 5 "Reserved" 4 "Auto Down" 3 "Auto Up" 2 "Manual Down" 1 "Manual Up" 0 "Window stop" ;
VAL_ 550 SWC2_R_Right_Sta 1 "Press" 0 "Release" ;
VAL_ 550 SWC2_R_ScrollUp_Sta 1 "Press" 0 "Release" ;
VAL_ 550 SWC2_R_ScrollPress_Sta 1 "Press" 0 "Release" ;
VAL_ 550 SWC2_R_ScrollDown_Sta 1 "Press" 0 "Release" ;
VAL_ 550 SWC2_R_Left_Sta 1 "Press" 0 "Release" ;
VAL_ 550 SWC2_R_VR_Sta 1 "Press" 0 "Release" ;
VAL_ 550 SWC2_R_PageSwitch_Sta 1 "Press" 0 "Release" ;
VAL_ 550 SWC2_R_Customize_Sta 1 "Press" 0 "Release" ;
VAL_ 550 SWC2_L_Left_Sta 1 "Press" 0 "Release" ;
VAL_ 550 SWC2_L_ScrollUp_Sta 1 "Press" 0 "Release" ;
VAL_ 550 SWC2_L_ScrollPress_Sta 1 "Press" 0 "Release" ;
VAL_ 550 SWC2_L_ScrollDown_Sta 1 "Press" 0 "Release" ;
VAL_ 550 SWC2_L_Right_Sta 1 "Press" 0 "Release" ;
VAL_ 550 SWC2_L_RegenUp_Sta 1 "Press" 0 "Release" ;
VAL_ 550 SWC2_L_ADAS_Sta 1 "Press" 0 "Release" ;
VAL_ 550 SWC2_L_Home_Sta 1 "Press" 0 "Release" ;
VAL_ 550 SWC2_ResponseError 1 "Error" 0 "Normal" ;
VAL_ 550 SWC2_R_RegenDown_Sta 1 "Press" 0 "Release" ;
VAL_ 550 SWC2_L_DriveMode_Sta 1 "Press" 0 "Release" ;
VAL_ 805 ACT5_Stop_mode 1 "Stop" 0 "Normal" ;
VAL_ 805 ACT5_Speed_specification 5 "AutoSpeed" 4 "Speed_4" 3 "Speed_3" 2 "Speed_2" 1 "Speed_1" ;
VAL_ 805 ACT5_Select_position_specificati 1 "Start_Position" 0 "Set_Position" ;
VAL_ 805 ACT5_Clear_Event_Flags 14 "AllEventClear" 0 "NotClear" ;
VAL_ 805 ACT4_Stop_mode 1 "Stop" 0 "Normal" ;
VAL_ 805 ACT4_Speed_specification 5 "AutoSpeed" 4 "Speed_4" 3 "Speed_3" 2 "Speed_2" 1 "Speed_1" ;
VAL_ 805 ACT4_Select_position_specificati 1 "Start_Position" 0 "Set_Position" ;
VAL_ 805 ACT4_Clear_Event_Flags 14 "AllEventClear" 0 "NotClear" ;
VAL_ 805 ACT3_Stop_mode 1 "Stop" 0 "Normal" ;
VAL_ 805 ACT3_Speed_specification 5 "AutoSpeed" 4 "Speed_4" 3 "Speed_3" 2 "Speed_2" 1 "Speed_1" ;
VAL_ 805 ACT3_Select_position_specificati 1 "Start_Position" 0 "Set_Position" ;
VAL_ 805 ACT3_Clear_Event_Flags 14 "AllEventClear" 0 "NotClear" ;
VAL_ 805 ACT2_Stop_mode 1 "Stop" 0 "Normal" ;
VAL_ 805 ACT2_Speed_specification 5 "AutoSpeed" 4 "Speed_4" 3 "Speed_3" 2 "Speed_2" 1 "Speed_1" ;
VAL_ 805 ACT2_Select_position_specificati 1 "Start_Position" 0 "Set_Position" ;
VAL_ 805 ACT2_Clear_Event_Flags 14 "AllEventClear" 0 "NotClear" ;
VAL_ 805 ACT1_Stop_mode 1 "Stop" 0 "Normal" ;
VAL_ 805 ACT1_Select_position_specificati 1 "Start_Position" 0 "Set_Position" ;
VAL_ 805 HornSW 1 "Press" 0 "Release" ;
VAL_ 805 AllLockSta 1 "Lock" 0 "Unlcok" ;
VAL_ 805 AutoLightSW 1 "EnableAutolamps" 0 "DisableAutolamps" ;
VAL_ 805 BrakeLampFail 1 "Fail" 0 "Normal" ;
VAL_ 805 DrLockSta 1 "Lock" 0 "Unlcok" ;
VAL_ 805 WiperSWPos 255 "Invalid" 8 "wash mode" 4 "wiper in HS mode(manual)" 2 "wiper in LS mode(manual)" 1 "wiper in Auto mode" 16 "mist mode" 0 "wiper off" ;
VAL_ 805 RRTurnLampC 255 "Invalid" ;
VAL_ 805 RLTurnLampC 255 "Invalid" ;
VAL_ 805 Wip_Speed 3 "High speed" 2 "Low speed" 1 "Intermittent" 0 "OFF" ;
VAL_ 805 MIRROR_FOLD_SW 1 "Press" 0 "Release" ;
VAL_ 805 PsLockSta 1 "Lock" 0 "Unlcok" ;
VAL_ 805 RLLockSta 1 "Lock" 0 "Unlcok" ;
VAL_ 805 RLS_Exist 1 "Exist" 0 "Not Exist" ;
VAL_ 805 RRLockSta 1 "Lock" 0 "Unlcok" ;
VAL_ 805 RWiperAS 1 "Not at Stop Position" 0 "Stop Position" ;
VAL_ 805 RWiperProtection 1 "In protection" 0 "Not in Protectio" ;
VAL_ 805 WiperZeroPosSW 1 "Wiper is not in zero position" 0 "Wiper is in zero position" ;
VAL_ 805 RLTurnLPErr 1 "Error" 0 "Normal" ;
VAL_ 805 RRTurnLPErr 1 "Error" 0 "Normal" ;
VAL_ 805 ZDR_THCM_IntakeFail_Sta 2 "NG" 1 "OK" 0 "Checking" ;
VAL_ 805 ZDR_THCM_LINACT1_Sta 2 "NG" 1 "OK" 0 "Checking" ;
VAL_ 805 ZDR_THCM_LINACT2_Sta 2 "NG" 1 "OK" 0 "Checking" ;
VAL_ 805 ZDR_THCM_LINACT3_Sta 2 "NG" 1 "OK" 0 "Checking" ;
VAL_ 805 ZDR_THCM_LINACT4_Sta 2 "NG" 1 "OK" 0 "Checking" ;
VAL_ 805 ZDR_THCM_LINACT5_Sta 2 "NG" 1 "OK" 0 "Checking" ;
VAL_ 805 ZDR_THCM_ModeFail_Sta 2 "NG" 1 "OK" 0 "Checking" ;
VAL_ 805 ACT1_Clear_Event_Flags 14 "AllEventClear" 0 "NotClear" ;
VAL_ 805 ACT1_Speed_specification 5 "AutoSpeed" 4 "Speed_4" 3 "Speed_3" 2 "Speed_2" 1 "Speed_1" ;
